VERSION "V5.0.0"

NS_ :

BS_:

BU_: SGW_SG CGW_SG

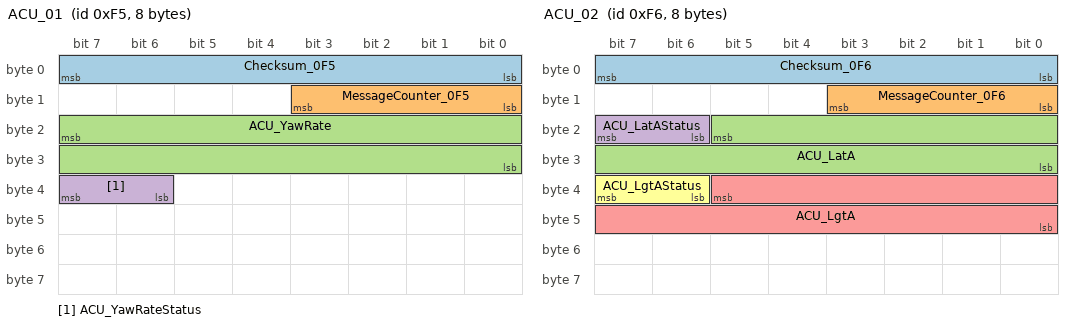
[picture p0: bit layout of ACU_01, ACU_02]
BO_ 245 ACU_01: 8 CGW_SG
 SG_ Checksum_0F5  : 7|8@0+ (1,0) [0|255] "" SGW_SG
 SG_ MessageCounter_0F5  : 11|4@0+ (1,0) [0|15] "" SGW_SG
 SG_ ACU_YawRate  : 23|16@0+ (0.01,-300) [-300|355.35] "degrees/s" SGW_SG
 SG_ ACU_YawRateStatus  : 39|2@0+ (1,0) [0|3] "" SGW_SG

BO_ 246 ACU_02: 8 CGW_SG
 SG_ Checksum_0F6  : 7|8@0+ (1,0) [0|255] "" SGW_SG
 SG_ MessageCounter_0F6  : 11|4@0+ (1,0) [0|15] "" SGW_SG
 SG_ ACU_LatA  : 21|14@0+ (0.01,-49.05) [-49.05|114.78] "m/s^2" SGW_SG
 SG_ ACU_LatAStatus  : 23|2@0+ (1,0) [0|3] "" SGW_SG
 SG_ ACU_LgtA  : 37|14@0+ (0.01,-49.05) [-49.05|114.78] "m/s^2" SGW_SG
 SG_ ACU_LgtAStatus  : 39|2@0+ (1,0) [0|3] "" SGW_SG

BO_ 151 ACU_info: 8 CGW_SG
 SG_ Checksum_097  : 7|8@0+ (1,0) [0|255] "" SGW_SG
 SG_ MessageCounter_097  : 11|4@0+ (1,0) [0|15] "" SGW_SG
 SG_ ACU_CrashOutputSts  : 23|5@0+ (1,0) [0|31] "" SGW_SG
 SG_ ACU_CrashOutputStsValid  : 16|1@0+ (1,0) [0|1] "" SGW_SG
 SG_ ACU_DriverSeatBeltSts  : 31|1@0+ (1,0) [0|1] "" SGW_SG
 SG_ ACU_DriverSeatBeltStsValid  : 30|1@0+ (1,0) [0|1] "" SGW_SG
 SG_ ACU_PassengerSeatBeltSts  : 27|1@0+ (1,0) [0|1] "" SGW_SG
 SG_ ACU_PassengerSeatBeltStsValid  : 26|1@0+ (1,0) [0|1] "" SGW_SG
 SG_ ACU_PassengerSts  : 25|1@0+ (1,0) [0|1] "" SGW_SG
 SG_ ACU_SecondLeftSeatBeltSts  : 39|1@0+ (1,0) [0|1] "" SGW_SG
 SG_ ACU_RLSeatBeltStatusValid  : 38|1@0+ (1,0) [0|1] "" SGW_SG
 SG_ ACU_SecondLeftSts  : 37|1@0+ (1,0) [0|1] "" SGW_SG
 SG_ ACU_SecondRightSeatBeltSts  : 55|1@0+ (1,0) [0|1] "" SGW_SG
 SG_ ACU_RRSeatBeltStatusValid  : 54|1@0+ (1,0) [0|1] "" SGW_SG
 SG_ ACU_SecondRightSts  : 53|1@0+ (1,0) [0|1] "" SGW_SG
 SG_ ACU_PassengerAirbagSts  : 63|2@0+ (1,0) [0|3] "" SGW_SG
 SG_ ACU_DriverWarningLampSts  : 61|2@0+ (1,0) [0|2] "" SGW_SG
 SG_ ACU_PassengerWarningLampSts  : 59|2@0+ (1,0) [0|2] "" SGW_SG
 SG_ ACU_WarningLampSts  : 57|2@0+ (1,0) [0|2] "" SGW_SG

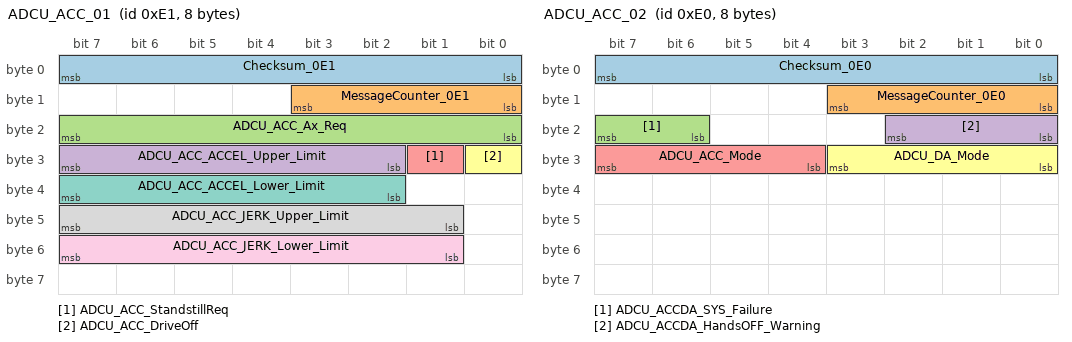
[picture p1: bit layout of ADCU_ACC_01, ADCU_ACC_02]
BO_ 225 ADCU_ACC_01: 8 CGW_SG
 SG_ Checksum_0E1  : 7|8@0+ (1,0) [0|255] "" SGW_SG
 SG_ MessageCounter_0E1  : 11|4@0+ (1,0) [0|15] "" SGW_SG
 SG_ ADCU_ACC_Ax_Req  : 23|8@0+ (0.05,-5) [-5|7.75] "m/s^2" SGW_SG
 SG_ ADCU_ACC_ACCEL_Upper_Limit  : 31|6@0+ (0.05,0) [0|3.15] "m/s^2" SGW_SG
 SG_ ADCU_ACC_StandstillReq  : 25|1@0+ (1,0) [0|1] "" SGW_SG
 SG_ ADCU_ACC_DriveOff  : 24|1@0+ (1,0) [0|1] "" SGW_SG
 SG_ ADCU_ACC_ACCEL_Lower_Limit  : 39|6@0+ (0.05,0) [0|3.15] "m/s^2" SGW_SG
 SG_ ADCU_ACC_JERK_Upper_Limit  : 47|7@0+ (0.1,0) [0|12.7] "m/s^3" SGW_SG
 SG_ ADCU_ACC_JERK_Lower_Limit  : 55|7@0+ (0.1,-12.7) [-12.7|0] "m/s^3" SGW_SG

BO_ 224 ADCU_ACC_02: 8 CGW_SG
 SG_ Checksum_0E0  : 7|8@0+ (1,0) [0|255] "" SGW_SG
 SG_ MessageCounter_0E0  : 11|4@0+ (1,0) [0|15] "" SGW_SG
 SG_ ADCU_ACCDA_SYS_Failure  : 23|2@0+ (1,0) [0|3] "" SGW_SG
 SG_ ADCU_ACCDA_HandsOFF_Warning  : 18|3@0+ (1,0) [0|7] "" SGW_SG
 SG_ ADCU_ACC_Mode  : 31|4@0+ (1,0) [0|10] "" SGW_SG
 SG_ ADCU_DA_Mode  : 27|4@0+ (1,0) [0|14] "" SGW_SG

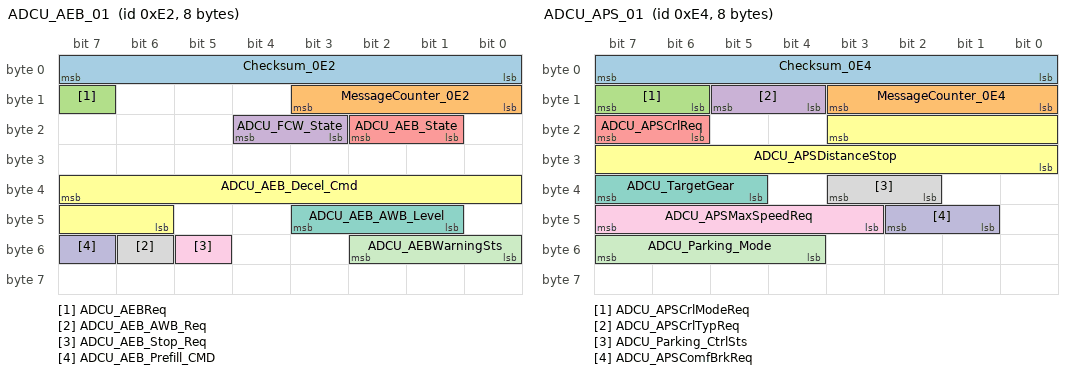
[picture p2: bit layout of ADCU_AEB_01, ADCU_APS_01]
BO_ 226 ADCU_AEB_01: 8 CGW_SG
 SG_ Checksum_0E2  : 7|8@0+ (1,0) [0|255] "" SGW_SG
 SG_ MessageCounter_0E2  : 11|4@0+ (1,0) [0|15] "" SGW_SG
 SG_ ADCU_AEBReq  : 15|1@0+ (1,0) [0|1] "" SGW_SG
 SG_ ADCU_FCW_State  : 20|2@0+ (1,0) [0|3] "" SGW_SG
 SG_ ADCU_AEB_State  : 18|2@0+ (1,0) [0|3] "" SGW_SG
 SG_ ADCU_AEB_Decel_Cmd  : 39|10@0+ (0.05,-16) [-16|16] "m/s^2" SGW_SG
 SG_ ADCU_AEB_AWB_Level  : 43|3@0+ (1,0) [0|5] "" SGW_SG
 SG_ ADCU_AEB_AWB_Req  : 54|1@0+ (1,0) [0|1] "" SGW_SG
 SG_ ADCU_AEB_Stop_Req  : 53|1@0+ (1,0) [0|1] "" SGW_SG
 SG_ ADCU_AEB_Prefill_CMD  : 55|1@0+ (1,0) [0|1] "" SGW_SG
 SG_ ADCU_AEBWarningSts  : 50|3@0+ (1,0) [0|7] "" SGW_SG

BO_ 228 ADCU_APS_01: 8 CGW_SG
 SG_ Checksum_0E4  : 7|8@0+ (1,0) [0|255] "" SGW_SG
 SG_ MessageCounter_0E4  : 11|4@0+ (1,0) [0|15] "" SGW_SG
 SG_ ADCU_APSCrlModeReq  : 15|2@0+ (1,0) [0|3] "" SGW_SG
 SG_ ADCU_APSCrlTypReq  : 13|2@0+ (1,0) [0|3] "" SGW_SG
 SG_ ADCU_APSCrlReq  : 23|2@0+ (1,0) [0|3] "" SGW_SG
 SG_ ADCU_APSDistanceStop  : 19|12@0+ (1,0) [0|4095] "cm" SGW_SG
 SG_ ADCU_TargetGear  : 39|3@0+ (1,0) [0|4] "" SGW_SG
 SG_ ADCU_Parking_CtrlSts  : 35|2@0+ (1,0) [0|3] "" SGW_SG
 SG_ ADCU_APSMaxSpeedReq  : 47|5@0+ (1,0) [0|30] "km/h" SGW_SG
 SG_ ADCU_APSComfBrkReq  : 42|2@0+ (1,0) [0|2] "" SGW_SG
 SG_ ADCU_Parking_Mode  : 55|4@0+ (1,0) [0|15] "" SGW_SG

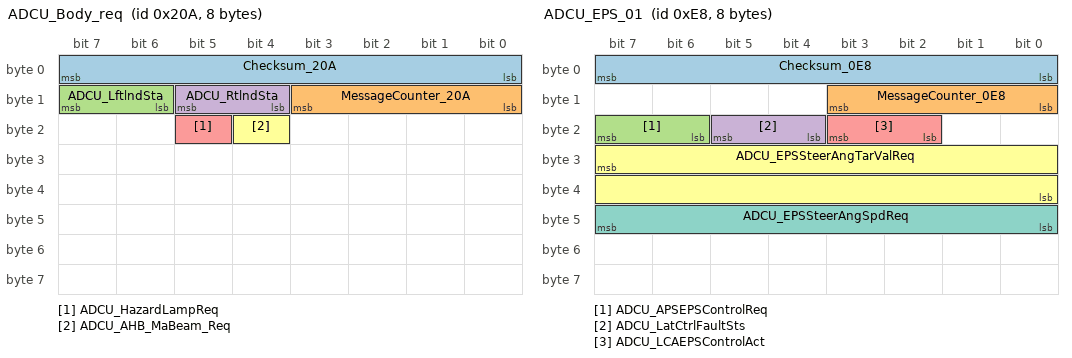
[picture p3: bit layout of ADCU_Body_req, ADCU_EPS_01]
BO_ 522 ADCU_Body_req: 8 CGW_SG
 SG_ Checksum_20A  : 7|8@0+ (1,0) [0|255] "" SGW_SG
 SG_ MessageCounter_20A  : 11|4@0+ (1,0) [0|15] "" SGW_SG
 SG_ ADCU_LftlndSta  : 15|2@0+ (1,0) [0|3] "" SGW_SG
 SG_ ADCU_RtlndSta  : 13|2@0+ (1,0) [0|3] "" SGW_SG
 SG_ ADCU_HazardLampReq  : 21|1@0+ (1,0) [0|1] "" SGW_SG
 SG_ ADCU_AHB_MaBeam_Req  : 20|1@0+ (1,0) [0|1] "" SGW_SG

BO_ 232 ADCU_EPS_01: 8 CGW_SG
 SG_ Checksum_0E8  : 7|8@0+ (1,0) [0|255] "" SGW_SG
 SG_ MessageCounter_0E8  : 11|4@0+ (1,0) [0|15] "" SGW_SG
 SG_ ADCU_APSEPSControlReq  : 23|2@0+ (1,0) [0|3] "" SGW_SG
 SG_ ADCU_LatCtrlFaultSts  : 21|2@0+ (1,0) [0|3] "" SGW_SG
 SG_ ADCU_LCAEPSControlAct  : 19|2@0+ (1,0) [0|3] "" SGW_SG
 SG_ ADCU_EPSSteerAngTarValReq  : 31|16@0+ (0.1,-780) [-780|779.9] "degrees" SGW_SG
 SG_ ADCU_EPSSteerAngSpdReq  : 47|8@0+ (10,-540) [-540|540] "degrees/s" SGW_SG

BO_ 515 ADCU_LDW_01: 8 CGW_SG
 SG_ ADCU_LDW_SYS_Sts  : 39|3@0+ (1,0) [0|7] "" SGW_SG

BO_ 613 APTC_TCU: 8 CGW_SG
 SG_ APTC_HVPowerUpReq  : 7|1@0+ (1,0) [0|1] "" SGW_SG
 SG_ APTC_HeatingFaltStatus  : 6|1@0+ (1,0) [0|1] "" SGW_SG
 SG_ APTC_DriveFaltStatus  : 5|1@0+ (1,0) [0|1] "" SGW_SG
 SG_ APTC_LostCommuFaltStatus  : 4|1@0+ (1,0) [0|1] "" SGW_SG
 SG_ APTC_IGBTFaltStatus  : 3|2@0+ (1,0) [0|3] "" SGW_SG
 SG_ APTC_Core1TempSensorFaltStatus  : 1|2@0+ (1,0) [0|3] "" SGW_SG
 SG_ APTC_LeftCoreTemp  : 15|8@0+ (1,-40) [-40|215] "degrees" SGW_SG
 SG_ APTC_RightCoreTemp  : 23|8@0+ (1,-40) [-40|215] "degrees" SGW_SG
 SG_ APTC_PowerConsumption  : 31|8@0+ (0.04,0) [0|10.2] "KW" SGW_SG
 SG_ APTC_HVBusVoltage  : 39|11@0+ (0.5,0) [0|1020] "V" SGW_SG
 SG_ APTC_OverCurrentFault  : 52|1@0+ (1,0) [0|1] "" SGW_SG
 SG_ APTC_LowVoltageStatus  : 51|2@0+ (1,0) [0|3] "" SGW_SG
 SG_ APTC_HighVoltageStatus  : 49|2@0+ (1,0) [0|3] "" SGW_SG
 SG_ APTC_OverLoadStatus  : 63|2@0+ (1,0) [0|3] "" SGW_SG
 SG_ APTC_IGBTTempSensorStatus  : 61|2@0+ (1,0) [0|3] "" SGW_SG
 SG_ APTC_PCBTempSensorStatus  : 59|2@0+ (1,0) [0|3] "" SGW_SG
 SG_ APTC_Core2TempSensorFaltStatus  : 57|2@0+ (1,0) [0|3] "" SGW_SG

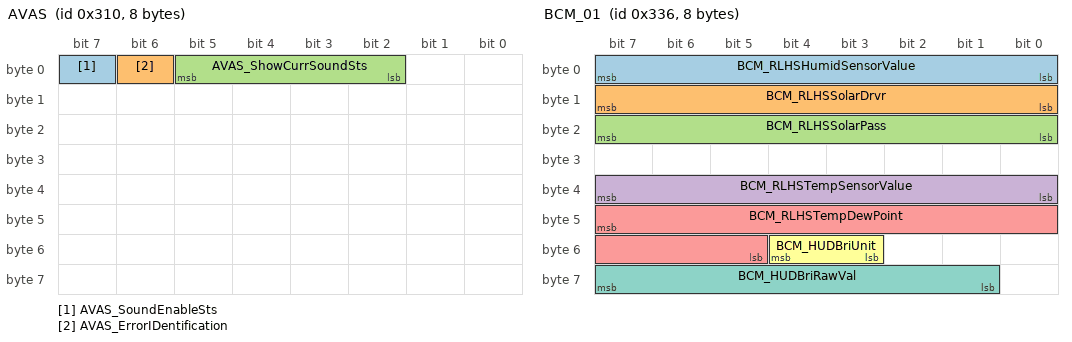
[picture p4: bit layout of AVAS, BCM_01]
BO_ 784 AVAS: 8 CGW_SG
 SG_ AVAS_SoundEnableSts  : 7|1@0+ (1,0) [0|1] "" SGW_SG
 SG_ AVAS_ErrorIDentification  : 6|1@0+ (1,0) [0|1] "" SGW_SG
 SG_ AVAS_ShowCurrSoundSts  : 5|4@0+ (1,0) [0|8] "" SGW_SG

BO_ 822 BCM_01: 8 CGW_SG
 SG_ BCM_RLHSHumidSensorValue  : 7|8@0+ (0.5,-0.5) [0|100] "percent" SGW_SG
 SG_ BCM_RLHSSolarDrvr  : 15|8@0+ (4,0) [0|1000] "W/m^2" SGW_SG
 SG_ BCM_RLHSSolarPass  : 23|8@0+ (4,0) [0|1000] "W/m^2" SGW_SG
 SG_ BCM_RLHSTempSensorValue  : 39|8@0+ (0.5,-40) [-39.5|87] "celsius" SGW_SG
 SG_ BCM_RLHSTempDewPoint  : 47|11@0+ (0.1,-39.6) [-39.5|60.4] "celsius" SGW_SG
 SG_ BCM_HUDBriUnit  : 52|2@0+ (1,0) [0|3] "" SGW_SG
 SG_ BCM_HUDBriRawVal  : 63|7@0+ (1,0) [0|126] "" SGW_SG

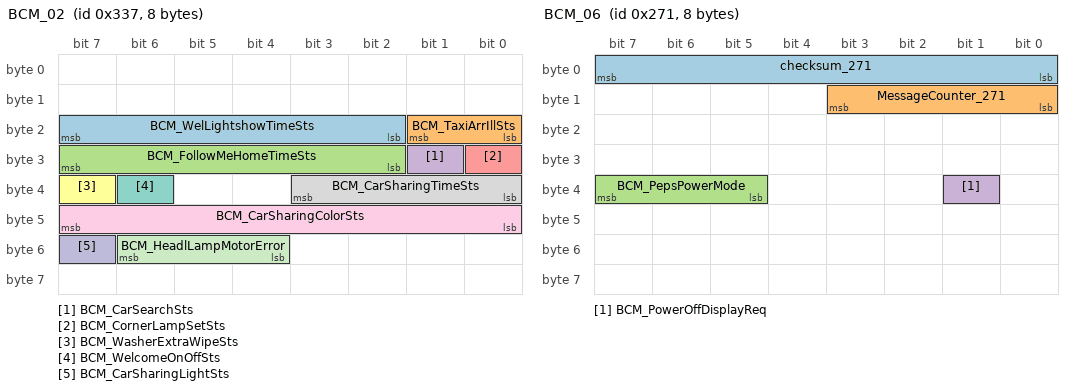
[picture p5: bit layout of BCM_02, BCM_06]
BO_ 823 BCM_02: 8 CGW_SG
 SG_ BCM_WelLightshowTimeSts  : 23|6@0+ (5,5) [5|180] "s" SGW_SG
 SG_ BCM_TaxiArrIllSts  : 17|2@0+ (1,0) [0|2] "" SGW_SG
 SG_ BCM_FollowMeHomeTimeSts  : 31|6@0+ (5,5) [5|180] "s" SGW_SG
 SG_ BCM_CarSearchSts  : 25|1@0+ (1,0) [0|1] "" SGW_SG
 SG_ BCM_CornerLampSetSts  : 24|1@0+ (1,0) [0|1] "" SGW_SG
 SG_ BCM_WasherExtraWipeSts  : 39|1@0+ (1,0) [0|1] "" SGW_SG
 SG_ BCM_WelcomeOnOffSts  : 38|1@0+ (1,0) [0|1] "" SGW_SG
 SG_ BCM_CarSharingTimeSts  : 35|4@0+ (1,0) [0|9] "" SGW_SG
 SG_ BCM_CarSharingColorSts  : 47|8@0+ (1,0) [0|255] "" SGW_SG
 SG_ BCM_CarSharingLightSts  : 55|1@0+ (1,0) [0|1] "" SGW_SG
 SG_ BCM_HeadlLampMotorError  : 54|3@0+ (1,0) [0|7] "" SGW_SG

BO_ 824 BCM_03: 8 CGW_SG
 SG_ Checksum_338  : 7|8@0+ (1,0) [0|255] "" SGW_SG
 SG_ MessageCounter_338  : 11|4@0+ (1,0) [0|15] "" SGW_SG
 SG_ BCM_HazardWarnSts  : 15|1@0+ (1,0) [0|1] "" SGW_SG
 SG_ BCM_DRLReq  : 14|2@0+ (1,0) [0|2] "" SGW_SG
 SG_ BCM_FollowMeHomeSts  : 23|1@0+ (1,0) [0|1] "" SGW_SG
 SG_ BCM_ChargingLightReq  : 22|3@0+ (1,0) [0|7] "" SGW_SG
 SG_ BCM_TaxiArrIllReq  : 16|1@0+ (1,0) [0|1] "" SGW_SG
 SG_ BCM_LeCornrgLiReq  : 31|2@0+ (1,0) [0|2] "" SGW_SG
 SG_ BCM_MainBeamReq  : 29|2@0+ (1,0) [0|2] "" SGW_SG
 SG_ BCM_DippedBeamReq  : 27|2@0+ (1,0) [0|3] "" SGW_SG
 SG_ BCM_RiCornrgLiReq  : 39|2@0+ (1,0) [0|2] "" SGW_SG
 SG_ BCM_RLS_AutoLampSenSts  : 37|2@0+ (1,0) [0|3] "" SGW_SG
 SG_ BCM_RearFogLampSts  : 35|1@0+ (1,0) [0|1] "" SGW_SG
 SG_ BCM_ExtLightFault  : 32|1@0+ (1,0) [0|1] "" SGW_SG
 SG_ BCM_StoplampReq  : 47|1@0+ (1,0) [0|1] "" SGW_SG
 SG_ BCM_AutoLmpSts  : 44|1@0+ (1,0) [0|1] "" SGW_SG
 SG_ BCM_HeightSetSts  : 43|3@0+ (1,0) [0|7] "" SGW_SG
 SG_ BCM_RLS_LightSensorFault  : 40|1@0+ (1,0) [0|1] "" SGW_SG
 SG_ BCM_RLS_RainSensorFault  : 45|1@0+ (1,0) [0|1] "" SGW_SG
 SG_ BCM_PosLampReq  : 55|2@0+ (1,0) [0|2] "" SGW_SG
 SG_ BCM_FrontFogLampReq  : 53|2@0+ (1,0) [0|2] "" SGW_SG
 SG_ BCM_FRDomeLampSts  : 51|2@0+ (1,0) [0|1] "" SGW_SG
 SG_ BCM_RRDomeLampSts  : 49|2@0+ (1,0) [0|1] "" SGW_SG
 SG_ BCM_WiperFaultWarn  : 60|1@0+ (1,0) [0|1] "" SGW_SG

BO_ 825 BCM_04: 8 CGW_SG
 SG_ Checksum_339  : 7|8@0+ (1,0) [0|255] "" SGW_SG
 SG_ MessageCounter_339  : 11|4@0+ (1,0) [0|15] "" SGW_SG
 SG_ BCM_LockFailRemindReq  : 15|1@0+ (1,0) [0|1] "" SGW_SG
 SG_ BCM_LockRLCtrlReq  : 17|2@0+ (1,0) [0|3] "" SGW_SG
 SG_ BCM_LockRRCtrlReq  : 19|2@0+ (1,0) [0|3] "" SGW_SG
 SG_ BCM_LockFRCtrlReq  : 21|2@0+ (1,0) [0|3] "" SGW_SG
 SG_ BCM_LockFLCtrlReq  : 23|2@0+ (1,0) [0|3] "" SGW_SG
 SG_ BCM_AwayLockSts  : 24|1@0+ (1,0) [0|1] "" SGW_SG
 SG_ BCM_OutsideUnlockModeSts  : 26|1@0+ (1,0) [0|1] "" SGW_SG
 SG_ BCM_ApproachingUnlockSts  : 27|1@0+ (1,0) [0|1] "" SGW_SG
 SG_ BCM_ChrgFlapSts  : 40|1@0+ (1,0) [0|1] "" SGW_SG
 SG_ BCM_TailgateLogicLockSts  : 41|1@0+ (1,0) [0|1] "" SGW_SG
 SG_ BCM_TailgateSts  : 42|1@0+ (1,0) [0|1] "" SGW_SG
 SG_ BCM_HoodSts  : 43|1@0+ (1,0) [0|1] "" SGW_SG
 SG_ BCM_CentralLockSts  : 44|1@0+ (1,0) [0|1] "" SGW_SG
 SG_ BCM_ChdLockSts  : 46|2@0+ (1,0) [0|3] "" SGW_SG
 SG_ BCM_GlassUnclsWarnCtrlRqst  : 48|1@0+ (1,0) [0|1] "" SGW_SG
 SG_ BCM_NFCCloseDoorAndLockFeedback  : 49|1@0+ (1,0) [0|1] "" SGW_SG
 SG_ BCM_WinAntipinchNotice  : 50|1@0+ (1,0) [0|1] "" SGW_SG
 SG_ BCM_LockDoorOpenReHornSts  : 53|1@0+ (1,0) [0|1] "" SGW_SG
 SG_ BCM_AntiTheftReHornSts  : 54|1@0+ (1,0) [0|1] "" SGW_SG
 SG_ BCM_LeftKeyReHornSts  : 55|1@0+ (1,0) [0|1] "" SGW_SG
 SG_ BCM_AlarmEnableSts  : 56|1@0+ (1,0) [0|1] "" SGW_SG
 SG_ BCM_RelockSts  : 59|3@0+ (1,0) [0|4] "" SGW_SG
 SG_ BCM_WinClsReq  : 62|1@0+ (1,0) [0|1] "" SGW_SG

BO_ 826 BCM_05: 8 CGW_SG
 SG_ Checksum_33A  : 7|8@0+ (1,0) [0|255] "" SGW_SG
 SG_ MessageCounter_33A  : 11|4@0+ (1,0) [0|15] "" SGW_SG
 SG_ BCM_GearTimesSts  : 15|3@0+ (1,0) [0|5] "" SGW_SG
 SG_ BCM_ChrgFlapLockSts  : 12|1@0+ (1,0) [0|1] "" SGW_SG
 SG_ BCM_FRSeatBeltRemindReq  : 17|2@0+ (1,0) [0|3] "" SGW_SG
 SG_ BCM_FLSeatBeltRemindReq  : 19|2@0+ (1,0) [0|3] "" SGW_SG
 SG_ BCM_KeyNotInCarRemind  : 20|1@0+ (1,0) [0|1] "" SGW_SG
 SG_ BCM_RRSeatBeltRemindReq  : 29|2@0+ (1,0) [0|3] "" SGW_SG
 SG_ BCM_RLSeatBeltRemindReq  : 31|2@0+ (1,0) [0|3] "" SGW_SG
 SG_ BCM_WiperServiceSts  : 33|2@0+ (1,0) [0|1] "" SGW_SG
 SG_ BCM_AutoCloseWinFunSts  : 36|1@0+ (1,0) [0|1] "" SGW_SG
 SG_ BCM_DomeLampBrightSts  : 37|1@0+ (1,0) [0|1] "" SGW_SG
 SG_ BCM_PuddleLiReq  : 39|2@0+ (1,0) [0|2] "" SGW_SG
 SG_ BCM_DomeLampAutoSts  : 41|2@0+ (1,0) [0|2] "" SGW_SG
 SG_ BCM_FrontWiperModeSts  : 44|3@0+ (1,0) [0|5] "" SGW_SG
 SG_ BCM_WiperWorkingSts  : 47|3@0+ (1,0) [0|2] "" SGW_SG
 SG_ BCM_WelLightshowOnOffSts  : 51|2@0+ (1,0) [0|2] "" SGW_SG

BO_ 625 BCM_06: 8 CGW_SG
 SG_ checksum_271  : 7|8@0+ (1,0) [0|255] "" SGW_SG
 SG_ MessageCounter_271  : 11|4@0+ (1,0) [0|15] "" SGW_SG
 SG_ BCM_PepsPowerMode  : 39|3@0+ (1,0) [0|7] "" SGW_SG
 SG_ BCM_PowerOffDisplayReq  : 33|1@0+ (1,0) [0|1] "" SGW_SG

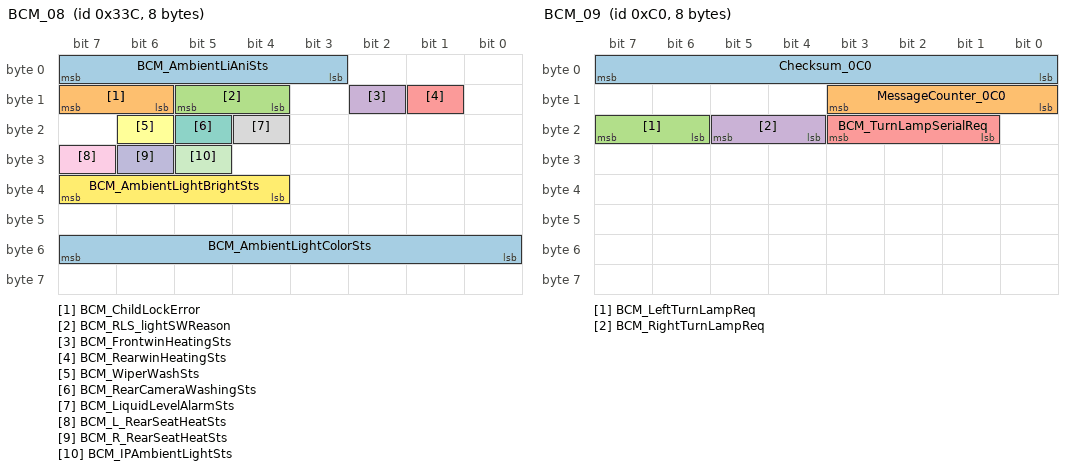
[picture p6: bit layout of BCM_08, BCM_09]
BO_ 828 BCM_08: 8 CGW_SG
 SG_ BCM_AmbientLiAniSts  : 7|5@0+ (1,0) [0|25] "" SGW_SG
 SG_ BCM_ChildLockError  : 15|2@0+ (1,0) [0|3] "" SGW_SG
 SG_ BCM_RLS_lightSWReason  : 13|2@0+ (1,0) [0|3] "" SGW_SG
 SG_ BCM_FrontwinHeatingSts  : 10|1@0+ (1,0) [0|1] "" SGW_SG
 SG_ BCM_RearwinHeatingSts  : 9|1@0+ (1,0) [0|1] "" SGW_SG
 SG_ BCM_WiperWashSts  : 22|1@0+ (1,0) [0|1] "" SGW_SG
 SG_ BCM_RearCameraWashingSts  : 21|1@0+ (1,0) [0|1] "" SGW_SG
 SG_ BCM_LiquidLevelAlarmSts  : 20|1@0+ (1,0) [0|1] "" SGW_SG
 SG_ BCM_L_RearSeatHeatSts  : 31|1@0+ (1,0) [0|1] "" SGW_SG
 SG_ BCM_R_RearSeatHeatSts  : 30|1@0+ (1,0) [0|1] "" SGW_SG
 SG_ BCM_IPAmbientLightSts  : 29|1@0+ (1,0) [0|1] "" SGW_SG
 SG_ BCM_AmbientLightBrightSts  : 39|4@0+ (1,0) [0|10] "" SGW_SG
 SG_ BCM_AmbientLightColorSts  : 55|8@0+ (1,0) [0|255] "" SGW_SG

BO_ 192 BCM_09: 8 CGW_SG
 SG_ Checksum_0C0  : 7|8@0+ (1,0) [0|255] "" SGW_SG
 SG_ MessageCounter_0C0  : 11|4@0+ (1,0) [0|15] "" SGW_SG
 SG_ BCM_LeftTurnLampReq  : 23|2@0+ (1,0) [0|2] "" SGW_SG
 SG_ BCM_RightTurnLampReq  : 21|2@0+ (1,0) [0|2] "" SGW_SG
 SG_ BCM_TurnLampSerialReq  : 19|3@0+ (1,0) [0|3] "" SGW_SG

BO_ 267 BCM_10: 8 CGW_SG
 SG_ BCM_CentralLockFeedback  : 38|2@0+ (1,0) [0|3] "" SGW_SG
 SG_ BCM_LVonReqKeyNotInCar  : 36|1@0+ (1,0) [0|1] "" SGW_SG

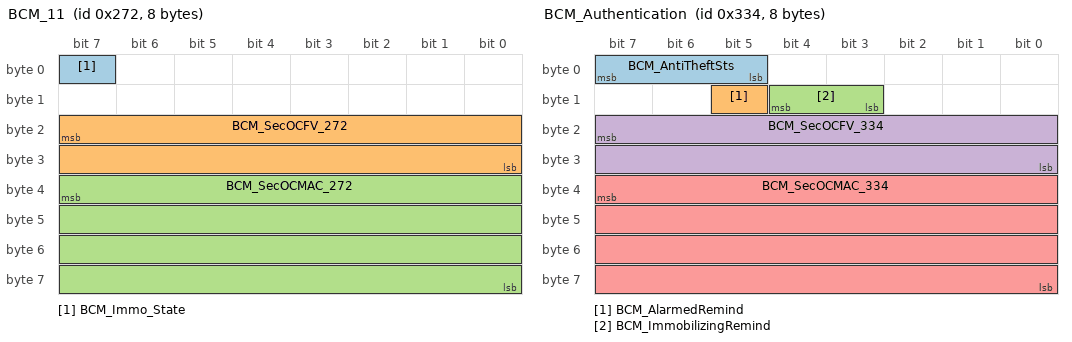
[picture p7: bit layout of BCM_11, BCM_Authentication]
BO_ 626 BCM_11: 8 CGW_SG
 SG_ BCM_Immo_State  : 7|1@0+ (1,0) [0|1] "" SGW_SG
 SG_ BCM_SecOCFV_272  : 23|16@0+ (1,0) [0|65535] "" SGW_SG
 SG_ BCM_SecOCMAC_272  : 39|32@0+ (1,0) [0|4294967295] "" SGW_SG

BO_ 624 BCM_ALM: 8 CGW_SG
 SG_ BCM_ALM1_MusicFrequencySts  : 5|1@0+ (1,0) [0|1] "" SGW_SG
 SG_ BCM_ALM2_MusicFrequencySts  : 4|1@0+ (1,0) [0|1] "" SGW_SG

BO_ 820 BCM_Authentication: 8 CGW_SG
 SG_ BCM_AntiTheftSts  : 7|3@0+ (1,0) [0|3] "" SGW_SG
 SG_ BCM_AlarmedRemind  : 13|1@0+ (1,0) [0|1] "" SGW_SG
 SG_ BCM_ImmobilizingRemind  : 12|2@0+ (1,0) [0|3] "" SGW_SG
 SG_ BCM_SecOCFV_334  : 23|16@0+ (1,0) [0|65535] "" SGW_SG
 SG_ BCM_SecOCMAC_334  : 39|32@0+ (1,0) [0|4294967295] "" SGW_SG

BO_ 934 BMS_BatInfor_01: 8 CGW_SG
 SG_ BMS_CellNumbers  : 15|8@0+ (1,0) [0|255] "" SGW_SG

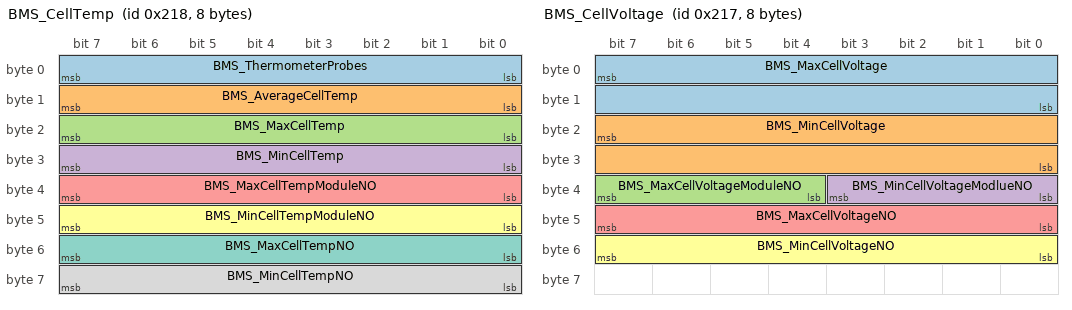
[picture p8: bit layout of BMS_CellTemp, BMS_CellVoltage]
BO_ 536 BMS_CellTemp: 8 CGW_SG
 SG_ BMS_ThermometerProbes  : 7|8@0+ (1,0) [0|255] "" SGW_SG
 SG_ BMS_AverageCellTemp  : 15|8@0+ (1,-40) [-40|215] "celsius" SGW_SG
 SG_ BMS_MaxCellTemp  : 23|8@0+ (1,-40) [-40|215] "celsius" SGW_SG
 SG_ BMS_MinCellTemp  : 31|8@0+ (1,-40) [-40|215] "celsius" SGW_SG
 SG_ BMS_MaxCellTempModuleNO  : 39|8@0+ (1,0) [0|255] "" SGW_SG
 SG_ BMS_MinCellTempModuleNO  : 47|8@0+ (1,0) [0|255] "" SGW_SG
 SG_ BMS_MaxCellTempNO  : 55|8@0+ (1,0) [0|255] "" SGW_SG
 SG_ BMS_MinCellTempNO  : 63|8@0+ (1,0) [0|255] "" SGW_SG

BO_ 535 BMS_CellVoltage: 8 CGW_SG
 SG_ BMS_MaxCellVoltage  : 7|16@0+ (0.001,0) [0|65.535] "V" SGW_SG
 SG_ BMS_MinCellVoltage  : 23|16@0+ (0.001,0) [0|65.535] "V" SGW_SG
 SG_ BMS_MaxCellVoltageModuleNO  : 39|4@0+ (1,0) [0|15] "" SGW_SG
 SG_ BMS_MinCellVoltageModlueNO  : 35|4@0+ (1,0) [0|15] "" SGW_SG
 SG_ BMS_MaxCellVoltageNO  : 47|8@0+ (1,0) [0|255] "" SGW_SG
 SG_ BMS_MinCellVoltageNO  : 55|8@0+ (1,0) [0|255] "" SGW_SG

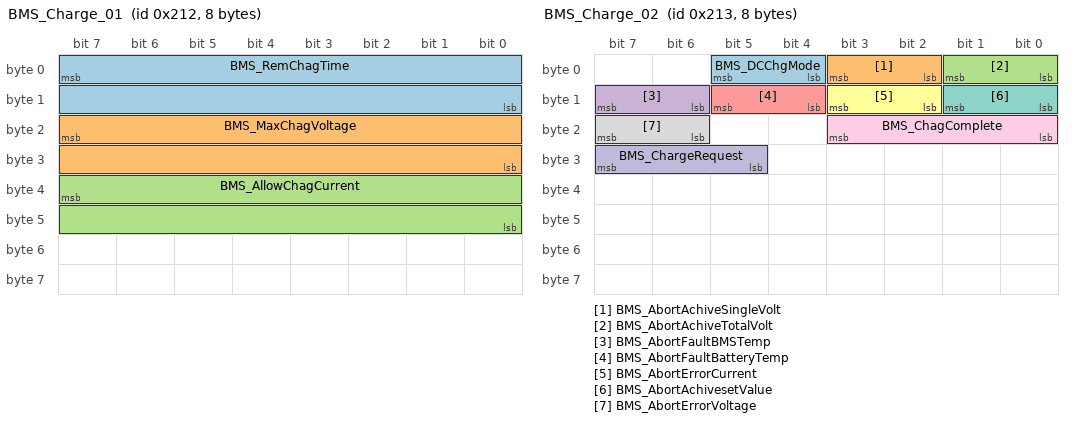
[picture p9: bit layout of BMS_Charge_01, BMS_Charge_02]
BO_ 530 BMS_Charge_01: 8 CGW_SG
 SG_ BMS_RemChagTime  : 7|16@0+ (1,0) [0|3600] "min" SGW_SG
 SG_ BMS_MaxChagVoltage  : 23|16@0+ (0.1,0) [0|6553.5] "V" SGW_SG
 SG_ BMS_AllowChagCurrent  : 39|16@0+ (0.1,-1000) [-1000|1000] "A" SGW_SG

BO_ 531 BMS_Charge_02: 8 CGW_SG
 SG_ BMS_DCChgMode  : 5|2@0+ (1,0) [0|2] "" SGW_SG
 SG_ BMS_AbortAchiveSingleVolt  : 3|2@0+ (1,0) [0|2] "" SGW_SG
 SG_ BMS_AbortAchiveTotalVolt  : 1|2@0+ (1,0) [0|2] "" SGW_SG
 SG_ BMS_AbortFaultBMSTemp  : 15|2@0+ (1,0) [0|2] "" SGW_SG
 SG_ BMS_AbortFaultBatteryTemp  : 13|2@0+ (1,0) [0|2] "" SGW_SG
 SG_ BMS_AbortErrorCurrent  : 11|2@0+ (1,0) [0|2] "" SGW_SG
 SG_ BMS_AbortAchivesetValue  : 9|2@0+ (1,0) [0|2] "" SGW_SG
 SG_ BMS_AbortErrorVoltage  : 23|2@0+ (1,0) [0|2] "" SGW_SG
 SG_ BMS_ChagComplete  : 19|4@0+ (1,0) [0|3] "" SGW_SG
 SG_ BMS_ChargeRequest  : 31|3@0+ (1,0) [0|4] "" SGW_SG

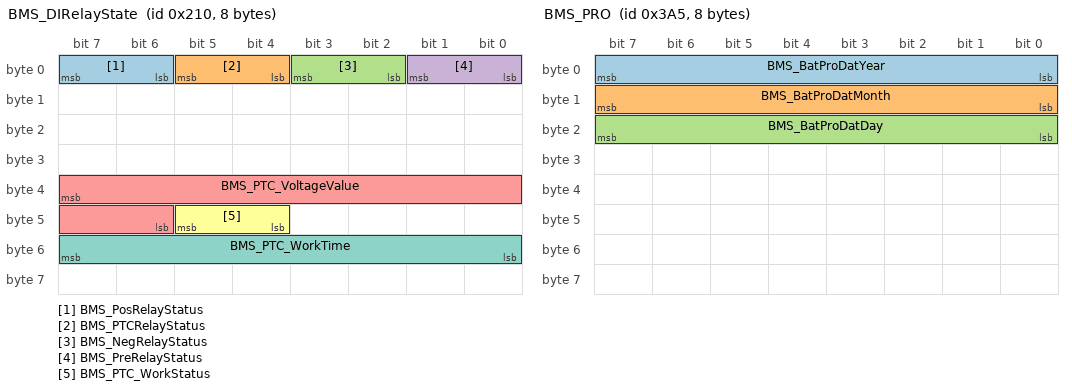
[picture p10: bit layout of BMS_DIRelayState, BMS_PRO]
BO_ 528 BMS_DIRelayState: 8 CGW_SG
 SG_ BMS_PosRelayStatus  : 7|2@0+ (1,0) [0|3] "" SGW_SG
 SG_ BMS_PTCRelayStatus  : 5|2@0+ (1,0) [0|3] "" SGW_SG
 SG_ BMS_NegRelayStatus  : 3|2@0+ (1,0) [0|3] "" SGW_SG
 SG_ BMS_PreRelayStatus  : 1|2@0+ (1,0) [0|3] "" SGW_SG
 SG_ BMS_PTC_VoltageValue  : 39|10@0+ (1,0) [0|1023] "V" SGW_SG
 SG_ BMS_PTC_WorkStatus  : 45|2@0+ (1,0) [0|2] "" SGW_SG
 SG_ BMS_PTC_WorkTime  : 55|8@0+ (1,0) [0|255] "min" SGW_SG

BO_ 772 BMS_ErrorInfo: 8 CGW_SG
 SG_ BMS_ErrorCellOverVolt  : 7|2@0+ (1,0) [0|3] "" SGW_SG
 SG_ BMS_ErrorCellUnderVolt  : 5|2@0+ (1,0) [0|3] "" SGW_SG
 SG_ BMS_ErrorCellHighTemp  : 3|2@0+ (1,0) [0|3] "" SGW_SG
 SG_ BMS_ErrorCellLowTemp  : 1|2@0+ (1,0) [0|3] "" SGW_SG
 SG_ BMS_ErrorBattOverVolt  : 15|2@0+ (1,0) [0|3] "" SGW_SG
 SG_ BMS_ErrorBattUnderVolt  : 13|2@0+ (1,0) [0|3] "" SGW_SG
 SG_ BMS_ErrorChaCurrentOver  : 11|2@0+ (1,0) [0|3] "" SGW_SG
 SG_ BMS_ErrorDisChaCurrentOver  : 9|2@0+ (1,0) [0|3] "" SGW_SG
 SG_ BMS_ErrorBSUOffline  : 23|1@0+ (1,0) [0|1] "" SGW_SG
 SG_ BMS_ErrorLeakCurrent  : 22|2@0+ (1,0) [0|3] "" SGW_SG
 SG_ BMS_ErrorCellVoltDiff  : 20|2@0+ (1,0) [0|3] "" SGW_SG
 SG_ BMS_ErrorCellTempDiff  : 18|2@0+ (1,0) [0|3] "" SGW_SG
 SG_ BMS_ErrorBatVolt  : 31|2@0+ (1,0) [0|3] "" SGW_SG
 SG_ BMS_ErrorHallOffline  : 29|1@0+ (1,0) [0|1] "" SGW_SG
 SG_ BMS_ErrorCellVoltOffline  : 28|1@0+ (1,0) [0|1] "" SGW_SG
 SG_ BMS_ErrorCellTempOffline  : 27|1@0+ (1,0) [0|1] "" SGW_SG
 SG_ BMS_ErrorPreChaFailed  : 26|1@0+ (1,0) [0|1] "" SGW_SG
 SG_ BMS_ErrorRelay  : 25|1@0+ (1,0) [0|1] "" SGW_SG
 SG_ BMS_ErrorBSUBalance  : 24|1@0+ (1,0) [0|1] "" SGW_SG
 SG_ BMS_ErrorLowSoc  : 37|2@0+ (1,0) [0|3] "" SGW_SG
 SG_ BMS_ErrorHighSoc  : 35|1@0+ (1,0) [0|1] "" SGW_SG
 SG_ BMS_ErrorSoCJump_RM  : 34|1@0+ (1,0) [0|1] "" SGW_SG
 SG_ BMS_ErrorHVIL  : 33|1@0+ (1,0) [0|1] "" SGW_SG
 SG_ BMS_ErrorEmergencyOffCrash  : 32|1@0+ (1,0) [0|1] "" SGW_SG
 SG_ BMS_ErrorSystemsMatch  : 47|1@0+ (1,0) [0|1] "" SGW_SG
 SG_ BMS_ErrorSmoke  : 46|1@0+ (1,0) [0|1] "" SGW_SG
 SG_ BMS_ErrorLeakDet  : 45|1@0+ (1,0) [0|1] "" SGW_SG
 SG_ BMS_ThermalRunawayFault  : 43|1@0+ (1,0) [0|1] "" SGW_SG
 SG_ BMS_DTC  : 55|8@0+ (1,0) [0|255] "" SGW_SG

BO_ 933 BMS_PRO: 8 CGW_SG
 SG_ BMS_BatProDatYear  : 7|8@0+ (1,0) [0|1] "" SGW_SG
 SG_ BMS_BatProDatMonth  : 15|8@0+ (1,0) [0|1] "" SGW_SG
 SG_ BMS_BatProDatDay  : 23|8@0+ (1,0) [0|1] "" SGW_SG

BO_ 992 BMS_SGW_01: 8 CGW_SG
 SG_ BMS_FeedEnergySts  : 7|17@0+ (0.1,0) [0|9999] "" SGW_SG
 SG_ BMS_DirveDiscSts  : 31|17@0+ (0.1,0) [0|9999] "" SGW_SG

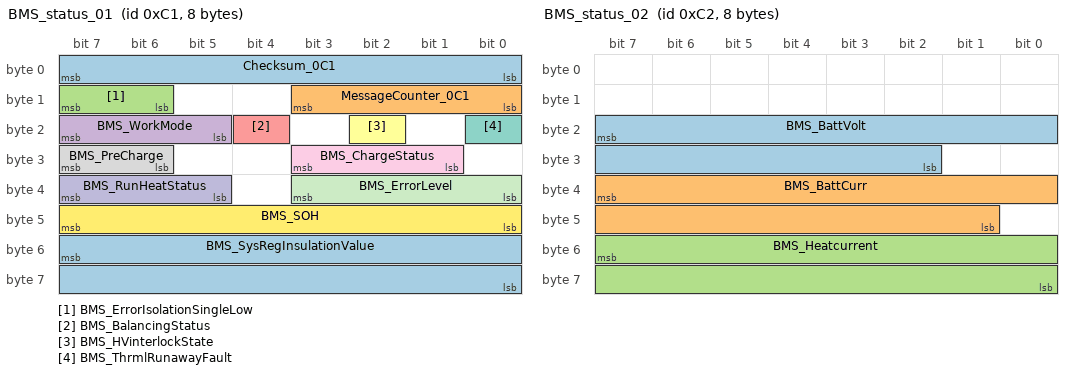
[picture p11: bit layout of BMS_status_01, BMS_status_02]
BO_ 193 BMS_status_01: 8 CGW_SG
 SG_ Checksum_0C1  : 7|8@0+ (1,0) [0|255] "" SGW_SG
 SG_ MessageCounter_0C1  : 11|4@0+ (1,0) [0|15] "" SGW_SG
 SG_ BMS_ErrorIsolationSingleLow  : 15|2@0+ (1,0) [0|3] "" SGW_SG
 SG_ BMS_WorkMode  : 23|3@0+ (1,0) [0|7] "" SGW_SG
 SG_ BMS_BalancingStatus  : 20|1@0+ (1,0) [0|1] "" SGW_SG
 SG_ BMS_HVinterlockState  : 18|1@0+ (1,0) [0|1] "" SGW_SG
 SG_ BMS_ThrmlRunawayFault  : 16|1@0+ (1,0) [0|1] "" SGW_SG
 SG_ BMS_PreCharge  : 31|2@0+ (1,0) [0|3] "" SGW_SG
 SG_ BMS_ChargeStatus  : 27|3@0+ (1,0) [0|7] "" SGW_SG
 SG_ BMS_RunHeatStatus  : 39|3@0+ (1,0) [0|4] "" SGW_SG
 SG_ BMS_ErrorLevel  : 35|4@0+ (1,0) [0|4] "" SGW_SG
 SG_ BMS_SOH  : 47|8@0+ (0.5,0) [0|100] "percent" SGW_SG
 SG_ BMS_SysRegInsulationValue  : 55|16@0+ (1,0) [0|60000] "kOhm" SGW_SG

BO_ 194 BMS_status_02: 8 CGW_SG
 SG_ BMS_BattVolt  : 23|14@0+ (0.1,0) [0|1000] "V" SGW_SG
 SG_ BMS_BattCurr  : 39|15@0+ (0.1,-1024) [-1024|1023] "A" SGW_SG
 SG_ BMS_Heatcurrent  : 55|16@0+ (0.1,-1024) [-1024|1023] "A" SGW_SG

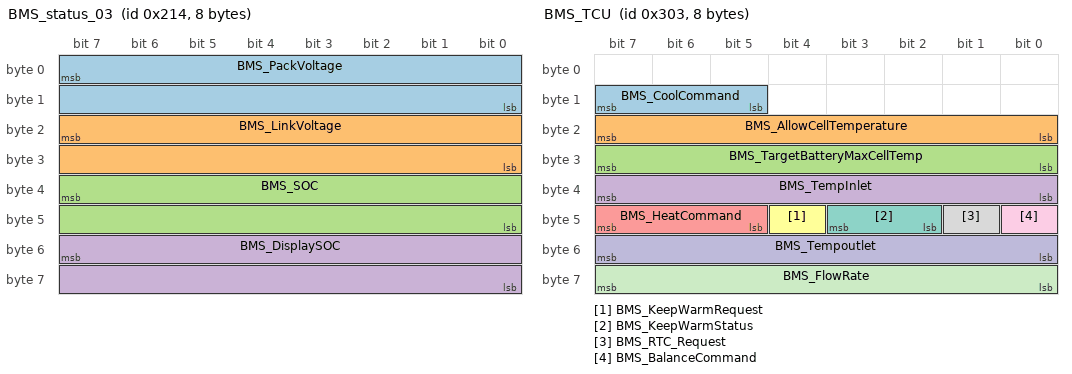
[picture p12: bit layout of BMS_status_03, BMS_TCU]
BO_ 532 BMS_status_03: 8 CGW_SG
 SG_ BMS_PackVoltage  : 7|16@0+ (0.1,0) [0|6553.5] "V" SGW_SG
 SG_ BMS_LinkVoltage  : 23|16@0+ (0.1,0) [0|6553.5] "V" SGW_SG
 SG_ BMS_SOC  : 39|16@0+ (0.01,0) [0|100] "percent" SGW_SG
 SG_ BMS_DisplaySOC  : 55|16@0+ (0.01,0) [0|100] "percent" SGW_SG

BO_ 771 BMS_TCU: 8 CGW_SG
 SG_ BMS_CoolCommand  : 15|3@0+ (1,0) [0|7] "" SGW_SG
 SG_ BMS_AllowCellTemperature  : 23|8@0+ (1,-40) [-40|215] "celsius" SGW_SG
 SG_ BMS_TargetBatteryMaxCellTemp  : 31|8@0+ (1,-40) [-40|215] "celsius" SGW_SG
 SG_ BMS_TempInlet  : 39|8@0+ (1,-40) [-40|215] "celsius" SGW_SG
 SG_ BMS_HeatCommand  : 47|3@0+ (1,0) [0|7] "" SGW_SG
 SG_ BMS_KeepWarmRequest  : 44|1@0+ (1,0) [0|1] "" SGW_SG
 SG_ BMS_KeepWarmStatus  : 43|2@0+ (1,0) [0|2] "" SGW_SG
 SG_ BMS_RTC_Request  : 41|1@0+ (1,0) [0|1] "" SGW_SG
 SG_ BMS_BalanceCommand  : 40|1@0+ (1,0) [0|1] "" SGW_SG
 SG_ BMS_Tempoutlet  : 55|8@0+ (1,-40) [-40|215] "celsius" SGW_SG
 SG_ BMS_FlowRate  : 63|8@0+ (1,0) [0|255] "L/min" SGW_SG

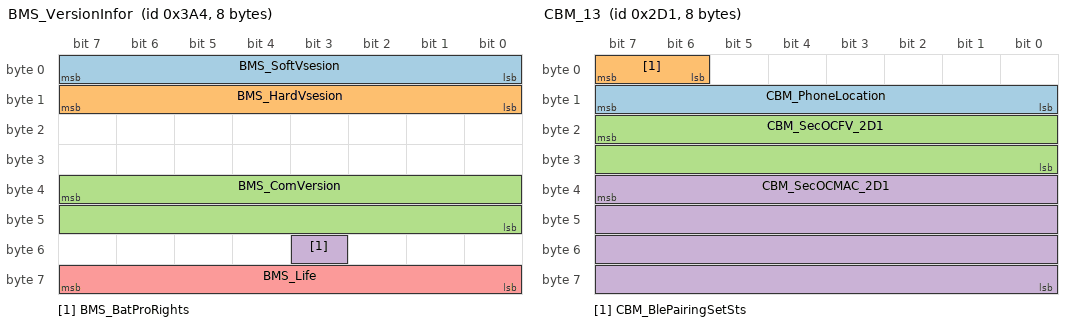
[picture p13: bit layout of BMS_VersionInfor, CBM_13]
BO_ 932 BMS_VersionInfor: 8 CGW_SG
 SG_ BMS_SoftVsesion  : 7|8@0+ (1,0) [0|1] "" SGW_SG
 SG_ BMS_HardVsesion  : 15|8@0+ (1,0) [0|1] "" SGW_SG
 SG_ BMS_ComVersion  : 39|16@0+ (1,0) [0|65535] "" SGW_SG
 SG_ BMS_BatProRights  : 51|1@0+ (1,0) [0|1] "" SGW_SG
 SG_ BMS_Life  : 63|8@0+ (1,0) [0|255] "" SGW_SG

BO_ 257 CBM_request_01: 8 SGW_SG
 SG_ CBM_BLE_CarSearchReq  : 26|1@0+ (1,0) [0|1] "" CGW_SG

BO_ 721 CBM_13: 8 SGW_SG
 SG_ CBM_PhoneLocation  : 15|8@0+ (1,0) [0|8] "" CGW_SG
 SG_ CBM_BlePairingSetSts  : 7|2@0+ (1,0) [0|2] "" CGW_SG
 SG_ CBM_SecOCFV_2D1  : 23|16@0+ (1,0) [0|65535] "" CGW_SG
 SG_ CBM_SecOCMAC_2D1  : 39|32@0+ (1,0) [0|4294967295] "" CGW_SG

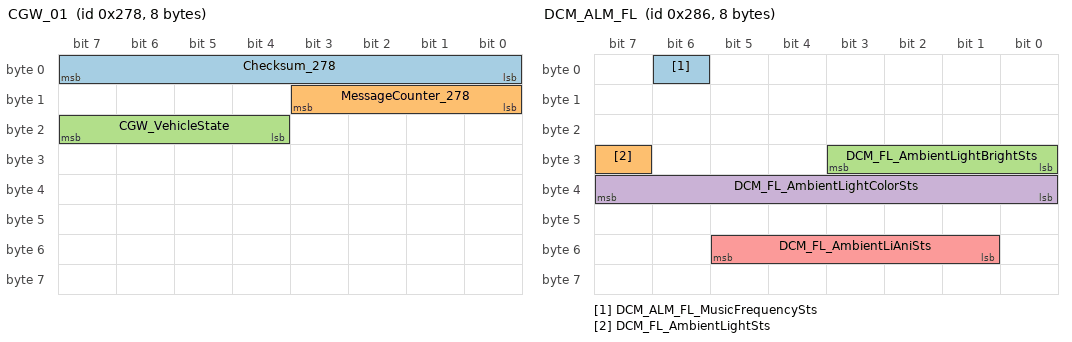
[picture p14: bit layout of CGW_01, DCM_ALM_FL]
BO_ 632 CGW_01: 8 CGW_SG
 SG_ Checksum_278  : 7|8@0+ (1,0) [0|255] "" SGW_SG
 SG_ MessageCounter_278  : 11|4@0+ (1,0) [0|15] "" SGW_SG
 SG_ CGW_VehicleState  : 23|4@0+ (1,0) [0|8] "" SGW_SG

BO_ 646 DCM_ALM_FL: 8 CGW_SG
 SG_ DCM_ALM_FL_MusicFrequencySts  : 6|1@0+ (1,0) [0|1] "" SGW_SG
 SG_ DCM_FL_AmbientLightSts  : 31|1@0+ (1,0) [0|1] "" SGW_SG
 SG_ DCM_FL_AmbientLightBrightSts  : 27|4@0+ (1,0) [0|10] "" SGW_SG
 SG_ DCM_FL_AmbientLightColorSts  : 39|8@0+ (1,0) [0|255] "" SGW_SG
 SG_ DCM_FL_AmbientLiAniSts  : 53|5@0+ (1,0) [0|25] "" SGW_SG

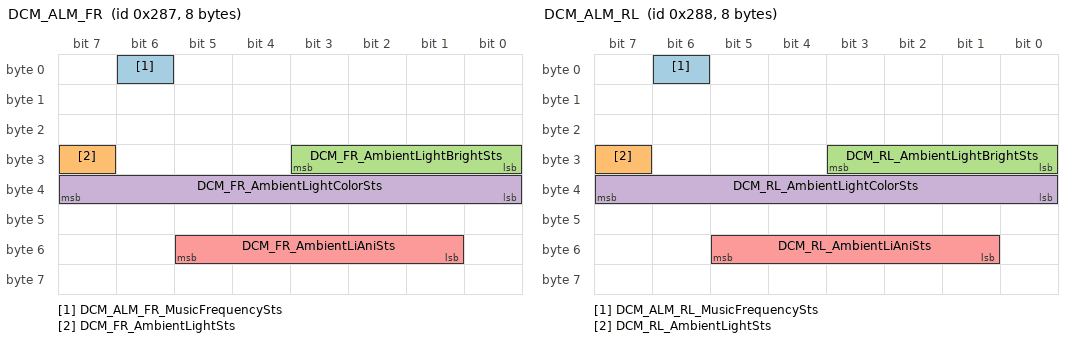
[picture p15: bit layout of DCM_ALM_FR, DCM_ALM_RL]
BO_ 647 DCM_ALM_FR: 8 CGW_SG
 SG_ DCM_ALM_FR_MusicFrequencySts  : 6|1@0+ (1,0) [0|1] "" SGW_SG
 SG_ DCM_FR_AmbientLightSts  : 31|1@0+ (1,0) [0|1] "" SGW_SG
 SG_ DCM_FR_AmbientLightBrightSts  : 27|4@0+ (1,0) [0|10] "" SGW_SG
 SG_ DCM_FR_AmbientLightColorSts  : 39|8@0+ (1,0) [0|255] "" SGW_SG
 SG_ DCM_FR_AmbientLiAniSts  : 53|5@0+ (1,0) [0|25] "" SGW_SG

BO_ 648 DCM_ALM_RL: 8 CGW_SG
 SG_ DCM_ALM_RL_MusicFrequencySts  : 6|1@0+ (1,0) [0|1] "" SGW_SG
 SG_ DCM_RL_AmbientLightSts  : 31|1@0+ (1,0) [0|1] "" SGW_SG
 SG_ DCM_RL_AmbientLightBrightSts  : 27|4@0+ (1,0) [0|10] "" SGW_SG
 SG_ DCM_RL_AmbientLightColorSts  : 39|8@0+ (1,0) [0|255] "" SGW_SG
 SG_ DCM_RL_AmbientLiAniSts  : 53|5@0+ (1,0) [0|25] "" SGW_SG

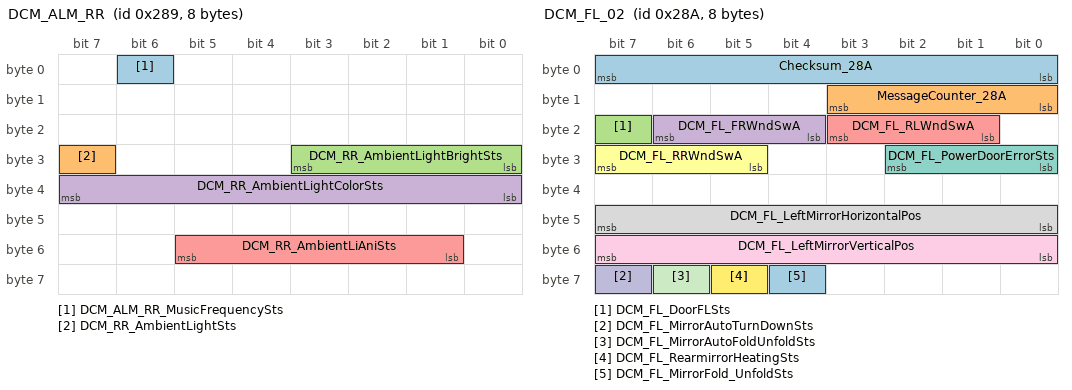
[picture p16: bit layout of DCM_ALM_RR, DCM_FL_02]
BO_ 649 DCM_ALM_RR: 8 CGW_SG
 SG_ DCM_ALM_RR_MusicFrequencySts  : 6|1@0+ (1,0) [0|1] "" SGW_SG
 SG_ DCM_RR_AmbientLightSts  : 31|1@0+ (1,0) [0|1] "" SGW_SG
 SG_ DCM_RR_AmbientLightBrightSts  : 27|4@0+ (1,0) [0|10] "" SGW_SG
 SG_ DCM_RR_AmbientLightColorSts  : 39|8@0+ (1,0) [0|255] "" SGW_SG
 SG_ DCM_RR_AmbientLiAniSts  : 53|5@0+ (1,0) [0|25] "" SGW_SG

BO_ 642 DCM_FL: 8 CGW_SG
 SG_ DCM_FL_CarSharingColorSts  : 7|8@0+ (1,0) [0|255] "" SGW_SG
 SG_ DCM_FL_CarSharingTimeSts  : 11|4@0+ (1,0) [0|9] "s" SGW_SG
 SG_ DCM_FL_PowerDoorModeSts  : 13|2@0+ (1,0) [0|3] "" SGW_SG
 SG_ DCM_FL_FrontKeepOpenSts  : 14|1@0+ (1,0) [0|1] "" SGW_SG
 SG_ DCM_FL_PriorSoundSts  : 15|1@0+ (1,0) [0|1] "" SGW_SG
 SG_ DCM_FL_DoorFLAngle  : 22|7@0+ (1,0) [0|100] "degrees" SGW_SG
 SG_ DCM_FL_DoorFLLockSts  : 23|1@0+ (1,0) [0|1] "" SGW_SG
 SG_ DCM_FL_LinkageAvoidanceReq  : 25|2@0+ (1,0) [0|3] "" SGW_SG
 SG_ DCM_FL_ElectricDoorMovementSts  : 28|3@0+ (1,0) [0|7] "" SGW_SG
 SG_ DCM_FL_DoorAntiPinchSts  : 29|1@0+ (1,0) [0|1] "" SGW_SG
 SG_ DCM_FL_DoorObstacleSts  : 30|1@0+ (1,0) [0|1] "" SGW_SG
 SG_ DCM_FL_FLPESwitchReq  : 31|1@0+ (1,0) [0|1] "" SGW_SG
 SG_ DCM_FL_PWM_POS_STS  : 35|3@0+ (1,0) [0|4] "" SGW_SG
 SG_ DCM_FL_WindowSts  : 38|3@0+ (1,0) [0|5] "" SGW_SG
 SG_ DCM_FL_InsideSwitchReq  : 39|1@0+ (1,0) [0|1] "" SGW_SG
 SG_ DCM_FL_FrontDoorAngleFeedback  : 40|1@0+ (1,0) [0|1] "" SGW_SG
 SG_ DCM_FL_GLASS_LOCATION  : 45|5@0+ (1,0) [0|20] "" SGW_SG
 SG_ DCM_FL_CarSharingLightSts  : 46|1@0+ (1,0) [0|1] "" SGW_SG
 SG_ DCM_FL_WelcomeOnOffSts  : 47|1@0+ (1,0) [0|1] "" SGW_SG

BO_ 650 DCM_FL_02: 8 CGW_SG
 SG_ Checksum_28A  : 7|8@0+ (1,0) [0|255] "" SGW_SG
 SG_ MessageCounter_28A  : 11|4@0+ (1,0) [0|15] "" SGW_SG
 SG_ DCM_FL_DoorFLSts  : 23|1@0+ (1,0) [0|1] "" SGW_SG
 SG_ DCM_FL_FRWndSwA  : 22|3@0+ (1,0) [0|5] "" SGW_SG
 SG_ DCM_FL_RLWndSwA  : 19|3@0+ (1,0) [0|5] "" SGW_SG
 SG_ DCM_FL_RRWndSwA  : 31|3@0+ (1,0) [0|5] "" SGW_SG
 SG_ DCM_FL_PowerDoorErrorSts  : 26|3@0+ (1,0) [0|7] "" SGW_SG
 SG_ DCM_FL_LeftMirrorHorizontalPos  : 47|8@0+ (1,0) [0|100] "percent" SGW_SG
 SG_ DCM_FL_LeftMirrorVerticalPos  : 55|8@0+ (1,0) [0|100] "percent" SGW_SG
 SG_ DCM_FL_MirrorAutoTurnDownSts  : 63|1@0+ (1,0) [0|1] "" SGW_SG
 SG_ DCM_FL_MirrorAutoFoldUnfoldSts  : 62|1@0+ (1,0) [0|1] "" SGW_SG
 SG_ DCM_FL_RearmirrorHeatingSts  : 61|1@0+ (1,0) [0|1] "" SGW_SG
 SG_ DCM_FL_MirrorFold_UnfoldSts  : 60|1@0+ (1,0) [0|1] "" SGW_SG

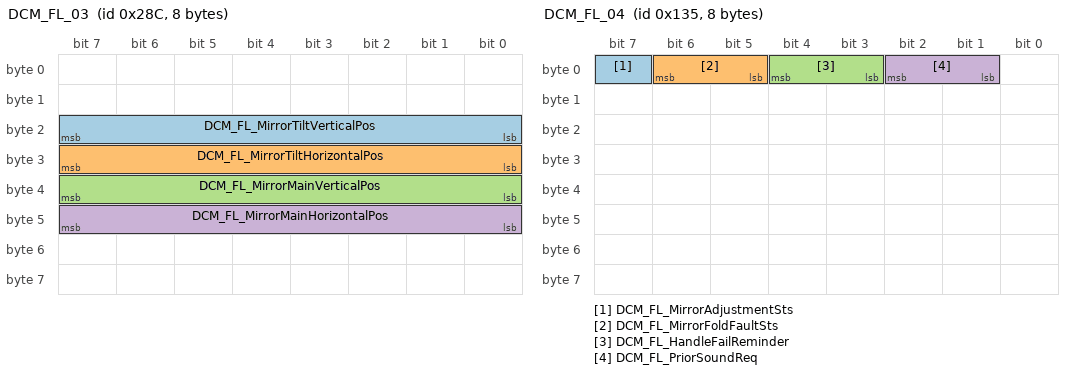
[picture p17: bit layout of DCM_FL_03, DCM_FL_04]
BO_ 652 DCM_FL_03: 8 CGW_SG
 SG_ DCM_FL_MirrorTiltVerticalPos  : 23|8@0+ (1,0) [0|100] "percent" SGW_SG
 SG_ DCM_FL_MirrorTiltHorizontalPos  : 31|8@0+ (1,0) [0|100] "percent" SGW_SG
 SG_ DCM_FL_MirrorMainVerticalPos  : 39|8@0+ (1,0) [0|100] "percent" SGW_SG
 SG_ DCM_FL_MirrorMainHorizontalPos  : 47|8@0+ (1,0) [0|100] "percent" SGW_SG

BO_ 309 DCM_FL_04: 8 CGW_SG
 SG_ DCM_FL_MirrorAdjustmentSts  : 7|1@0+ (1,0) [0|1] "" SGW_SG
 SG_ DCM_FL_MirrorFoldFaultSts  : 6|2@0+ (1,0) [0|3] "" SGW_SG
 SG_ DCM_FL_HandleFailReminder  : 4|2@0+ (1,0) [0|3] "" SGW_SG
 SG_ DCM_FL_PriorSoundReq  : 2|2@0+ (1,0) [0|1] "" SGW_SG

CM_ "Revision:V1.0,
Revision:V1.0.1,
Revision:V1.0.1,
Revision:V1.0.1,
Revision:V1.0.1,
Revision:V1.0.1,
Revision:V1.0.2,
Revision:V1.0.2,
Revision:V1.0.2,
Revision:V1.0.2,
Revision:V1.0.2,
Revision:V1.0.2,
Revision:V1.0.2,
Revision:V1.0.2,
Revision:V1.0.2,
Revision:V1.0.2,
Revision:V1.0.2,
Revision:V1.0.2,
Revision:V1.0.2,
Revision:V1.0.2,
Revision:V1.0.2,
Revision:V1.0.2,
Revision:V1.0.2,
Revision:V1.0.2,
Revision:V1.0.2,
Revision:V1.0.2,
Revision:V1.0.2,
Revision:V1.0.2,
Revision:V1.0.2,
Revision:V1.0.2,
Revision:V1.0.2,
Revision:V1.0.2,
Revision:V1.0.2,
Revision:V1.1,
Revision:V1.1,
Revision:V1.1,
Revision:V1.1,
Revision:V1.1,
Revision:V1.1,
Revision:V1.1,
Revision:V1.1,
Revision:V1.1,
Revision:V1.1,
Revision:V1.1,
Revision:V1.1,
Revision:V1.1,
Revision:V1.1,
Revision:V1.1,
Revision:V1.1,
Revision:V1.1,
Revision:V1.1,
Revision:V1.1,
Revision:V1.1,
Revision:V1.1,
Revision:V1.1,
Revision:V1.1,
Revision:V1.1,
Revision:V1.1,
Revision:V1.1,
Revision:V1.1,
Revision:V1.1,
Revision:V1.1,
Revision:V1.1,
Revision:V1.1,
Revision:V1.1,
Revision:V1.1,
Revision:V1.1,
Revision:V1.1,
Revision:V1.1,
Revision:V1.1,
Revision:V1.1,
Revision:V1.1,
Revision:V1.1,
Revision:V1.1,
Revision:V1.1,
Revision:V1.2,
Revision:V0.1.3,
Revision:V0.1.3,
Revision:V0.1.3,
Revision:V0.1.3,
Revision:V0.1.3,
Revision:V0.1.3,
Revision:V0.1.3,
Revision:V0.2.0,
Revision:V0.2.0,
Revision:V0.2.0,
Revision:V0.2.0,
Revision:V0.2.0,
Revision:V0.2.0,
Revision:V0.2.0,
Revision:V0.2.0,
Revision:V0.2.0,
Revision:V0.2.0,
Revision:V0.2.0,
Revision:V1.0.0,
Revision:V1.0.0,
Revision:V1.1.0,
Revision:V1.1.0,
Revision:V1.1.0,
Revision:V1.0.0,
Revision:V1.0.0,
Revision:V1.0.0,
Revision:V1.0.0,
Revision:V1.0.0,
Revision:V1.0.0,
Revision:V1.0.0,
Revision:V1.0.0,
Revision:V1.0.0,
Revision:V1.0.0,
Revision:V1.0.0,
Revision:V1.0.0,
Revision:V1.0.0,
Revision:V1.0.0,
Revision:V1.0.0,
Revision:V1.0.0,
Revision:V1.0.0,
Revision:V1.0.0,
Revision:V1.0.0,
Revision:V1.0.0,
Revision:V1.0.0,
Revision:V1.0.0,
Revision:V1.0.0,
Revision:V1.0.0,
Revision:V1.0.0,
Revision:V1.0.0,
Revision:V1.0.0,
Revision:V1.0.0,
Revision:V1.0.0,
Revision:V1.0.0,
Revision:V1.0.0,
Revision:V1.0.0,
Revision:V1.0.0,
Revision:V1.0.0,
Revision:V1.0.0,
Revision:V1.0.0,
Revision:V1.0.0,
Revision:V1.0.0,
Revision:V1.0.0,
Revision:V1.0.0,
Revision:V1.0.0,
Revision:V1.0.0,
Revision:V1.0.0,
Revision:V1.0.0,
Revision:V1.0.0,
Revision:V1.0.0,
Revision:V1.0.0,
Revision:V1.0.0,
Revision:V1.0.0,
Revision:V1.0.0,
Revision:V1.0.0,
Revision:V1.0.0,
Revision:V1.0.0,
Revision:V1.0.0,
Revision:V1.0.0,
Revision:V1.0.0,
Revision:V1.0.0,
Revision:V1.0.0,
Revision:V1.0.0,
Revision:V1.0.0,
Revision:V1.0.0,
Revision:V1.0.0,
Revision:V1.0.0,
Revision:V1.0.0,
Revision:V1.0.0,
Revision:V1.0.0,
Revision:V1.0.0,
Revision:V1.0.0,
Revision:V1.0.0,
Revision:V1.0.0,
Revision:V1.0.0,
Revision:V1.0.0,
Revision:V1.0.0,
Revision:V1.0.0,
Revision:V1.0.0,
Revision:V1.0.0,
Revision:V1.0.0,
Revision:V1.0.0,
Revision:V1.0.0,
Revision:V1.0.0,
Revision:V1.0.0,
Revision:V1.0.0,
Revision:V1.0.0,
Revision:V1.0.0,
Revision:V1.0.0,
Revision:V1.0.0,
Revision:V1.0.0,
Revision:V1.0.0,
Revision:V1.0.0,
Revision:V1.0.0,
Revision:V1.0.0,
Revision:V1.0.0,
Revision:V1.0.0,
Revision:V1.0.0,
Revision:V1.0.0,
Revision:V1.0.0,
Revision:V1.0.0,
Revision:V1.0.0,
Revision:V1.0.0,
Revision:V1.0.0,
Revision:V1.0.0,
Revision:V1.0.0,
Revision:V1.0.0,
Revision:V1.0.0,
Revision:V1.0.0,
Revision:V1.0.0,
Revision:V1.0.0,
Revision:V1.0.0,
Revision:V1.0.0,
Revision:V1.0.0,
Revision:V1.0.0,
Revision:V1.0.0,
Revision:V1.0.0,
Revision:V1.0.0,
Revision:V1.0.0,
Revision:V1.0.0,
Revision:V1.0.0,
Revision:V1.0.0,
Revision:V1.0.0,
Revision:V1.0.0,
Revision:V1.0.0,
Revision:V1.0.0,
Revision:V1.0.0,
Revision:V1.0.0,
Revision:V1.0.0,
Revision:V1.0.0,
Revision:V1.0.0,
Revision:V1.0.0,
Revision:V1.0.0,
Revision:V1.0.0,
Revision:V1.0.0,
Revision:V1.0.0,
Revision:V1.0.0,
Revision:V1.0.0,
Revision:V1.0.0,
Revision:V1.0.0,
Revision:V1.0.0,
Revision:V1.0.0,
Revision:V1.0.0,
Revision:V1.0.0,
Revision:V1.0.0,
Revision:V1.0.0,
Revision:V1.0.0,
Revision:V1.0.0,
Revision:V1.0.0,
Revision:V1.0.0,
Revision:V1.0.0,
Revision:V1.0.0,
Revision:V1.0.0,
Revision:V1.0.0,
Revision:V1.0.0,
Revision:V1.0.0,
Revision:V1.0.0,
Revision:V1.0.0,
Revision:V1.0.0,
Revision:V1.0.0,
Revision:V1.0.0,
Revision:V1.0.0,
Revision:V1.0.0,
Revision:V1.0.0,
Revision:V1.0.0,
Revision:V1.0.0,
Revision:V1.0.0,
Revision:V1.0.0,
Revision:V1.0.0,
Revision:V1.0.0,
Revision:V1.0.0,
Revision:V1.0.0,
Revision:V1.0.0,
Revision:V1.0.0,
Revision:V1.0.0,
Revision:V1.0.0,
Revision:V1.0.0,
Revision:V1.0.0,
Revision:V1.0.0,
Revision:V1.0.0,
Revision:V1.0.0,
Revision:V1.0.0,
Revision:V1.0.0,
Revision:V1.0.0,
Revision:V1.0.0,
Revision:V1.0.0,
Revision:V1.0.0,
Revision:V1.0.0,
Revision:V1.0.0,
Revision:V1.0.0,
Revision:V1.0.0,
Revision:V1.0.0,
Revision:V1.0.0,
Revision:V1.0.0,
Revision:V1.0.0,
Revision:V1.0.0,
Revision:V1.0.0,
Revision:V1.0.0,
Revision:V1.0.0,
Revision:V1.0.0,
Revision:V1.0.0,
Revision:V1.0.0,
Revision:V1.0.0,
Revision:V1.0.0,
Revision:V1.0.0,
Revision:V1.0.0,
Revision:V1.0.0,
Revision:V1.0.0,
Revision:V1.0.0,
Revision:V1.0.0,
Revision:V1.0.0,
Revision:V1.0.0,
Revision:V1.0.0,
Revision:V1.0.0,
Revision:V1.0.0,
Revision:V1.0.0,
Revision:V1.0.0,
Revision:V1.0.0,
Revision:V1.0.0,
Revision:V1.0.0,
Revision:V1.0.0,
Revision:V1.0.0,
Revision:V1.0.0,
Revision:V1.0.0,
Revision:V1.0.0,
Revision:V1.0.0,
Revision:V1.0.0,
Revision:V1.0.0,
Revision:V1.0.0,
Revision:V1.0.0,
Revision:V1.0.0,
Revision:V1.0.0,
Revision:V1.0.0,
Revision:V1.0.0,
Revision:V1.0.0,
Revision:V1.0.0,
Revision:V1.0.0,
Revision:V1.0.0,
Revision:V1.0.0,
Revision:V1.0.0,
Revision:V1.0.0,
Revision:V1.0.0,
Revision:V1.0.0,
Revision:V1.0.0,
Revision:V1.0.0,
Revision:V1.0.0,
Revision:V1.0.0,
Revision:V1.0.0,
Revision:V1.0.0,
Revision:V1.1.0,
Revision:V1.1.0,
Revision:V1.1.0,
Revision:V1.1.0,
Revision:V1.1.0,
Revision:V1.1.0,
Revision:V1.1.0,
Revision:V1.1.0,
Revision:V1.1.0,
Revision:V1.1.0,
Revision:V1.1.0,
Revision:V1.1.0,
Revision:V1.1.0,
Revision:V1.1.0,
Revision:V1.1.0,
Revision:V1.1.0,
Revision:V1.1.0,
Revision:V1.1.0,
Revision:V1.1.0,
Revision:V1.1.0,
Revision:V1.1.0,
Revision:V1.1.0,
Revision:V1.1.0,
Revision:V1.1.0,
Revision:V1.1.0,
Revision:V1.1.0,
Revision:V1.1.0,
Revision:V1.1.0,
Revision:V1.1.0,
Revision:V1.1.0,
Revision:V1.1.0,
Revision:V1.1.0,
Revision:V1.1.0,
Revision:V1.1.0,
Revision:V1.1.0,
Revision:V1.1.0,
Revision:V1.1.0,
Revision:V1.1.0,
Revision:V1.1.0,
Revision:V1.1.0,
Revision:V1.1.0,
Revision:V1.1.0,
Revision:V1.1.0,
Revision:V1.1.0,
Revision:V1.1.0,
Revision:V1.1.0,
Revision:V1.1.0,
Revision:V1.1.0,
Revision:V1.1.0,
Revision:V1.1.0,
Revision:V1.1.0,
Revision:V1.1.0,
Revision:V1.1.0,
Revision:V1.1.0,
Revision:V1.1.0,
Revision:V1.1.0,
Revision:V1.1.0,
Revision:V1.1.0,
Revision:V1.1.0,
Revision:V1.1.0,
Revision:V1.1.0,
Revision:V1.1.0,
Revision:V1.1.0,
Revision:V1.1.0,
Revision:V1.1.0,
Revision:V1.1.0,
Revision:V1.1.0,
Revision:V1.1.0,
Revision:V1.1.0,
Revision:V1.1.0,
Revision:V1.1.0,
Revision:V1.1.0,
Revision:V1.1.0,
Revision:V1.1.0,
Revision:V1.1.0,
Revision:V1.1.0,
Revision:V1.1.0,
Revision:V1.1.0,
Revision:V1.1.0,
Revision:V1.1.0,
Revision:V1.1.0,
Revision:V1.1.0,
Revision:V1.1.0,
Revision:V1.1.0,
Revision:V1.1.0,
Revision:V1.1.0,
Revision:V1.1.0,
Revision:V1.1.0,
Revision:V1.1.0,
Revision:V1.1.0,
Revision:V1.1.0,
Revision:V1.1.0,
Revision:V1.1.0,
Revision:V1.1.0,
Revision:V1.1.0,
Revision:V1.1.0,
Revision:V1.1.0,
Revision:V1.1.0,
Revision:V1.1.0,
Revision:V1.1.0,
Revision:V1.1.0,
Revision:V1.1.0,
Revision:V1.1.0,
Revision:V1.1.0,
Revision:V1.1.0,
Revision:V1.1.0,
Revision:V1.1.0,
Revision:V1.1.0,
Revision:V1.1.0,
Revision:V1.1.0,
Revision:V1.1.0,
Revision:V1.1.0,
Revision:V1.1.0,
Revision:V1.1.0,
Revision:V1.1.0,
Revision:V1.1.0,
Revision:V1.1.0,
Revision:V1.1.0,
Revision:V1.1.0,
Revision:V1.1.0,
Revision:V1.1.0,
Revision:V1.1.0,
Revision:V1.1.0,
Revision:V1.1.0,
Revision:V1.1.0,
Revision:V1.1.0,
Revision:V1.1.0,
Revision:V1.1.0,
Revision:V1.1.0,
Revision:V1.1.0,
Revision:V1.1.0,
Revision:V1.1.0,
Revision:V1.1.0,
Revision:V1.1.0,
Revision:V1.1.0,
Revision:V1.1.0,
Revision:V1.1.0,
Revision:V1.1.0,
Revision:V1.2.0,
Revision:V1.2.0,
Revision:V1.2.0,
Revision:V1.2.0,
Revision:V1.2.0,
Revision:V1.2.0,
Revision:V1.2.0,
Revision:V1.2.0,
Revision:V1.2.0,
Revision:V1.2.0,
Revision:V1.2.0,
Revision:V1.2.0,
Revision:V1.2.0,
Revision:V1.2.0,
Revision:V1.2.0,
Revision:V1.2.0,
Revision:V1.2.0,
Revision:V1.2.0,
Revision:V1.2.0,
Revision:V1.2.0,
Revision:V1.2.0,
Revision:V1.2.0,
Revision:V1.2.0,
Revision:V1.2.0,
Revision:V1.2.0,
Revision:V1.2.0,
Revision:V1.2.0,
Revision:V1.2.0,
Revision:V1.2.0,
Revision:V1.2.0,
Revision:V1.2.0,
Revision:V1.2.0,
Revision:V1.2.0,
Revision:V1.2.0,
Revision:V1.2.0,
Revision:V1.2.0,
Revision:V1.2.0,
Revision:V1.2.0,
Revision:V1.2.0,
Revision:V1.2.0,
Revision:V1.2.0,
Revision:V1.2.0,
Revision:V1.2.0,
Revision:V1.2.0,
Revision:V1.2.0,
Revision:V1.2.0,
Revision:V1.2.0,
Revision:V1.2.0,
Revision:V1.2.0,
Revision:V1.2.0,
Revision:V1.2.0,
Revision:V1.2.0,
Revision:V1.2.0,
Revision:V1.2.0,
Revision:V1.2.0,
Revision:V1.2.0,
Revision:V1.2.0,
Revision:V1.2.0,
Revision:V1.2.0,
Revision:V1.2.0,
Revision:V1.2.0,
Revision:V1.2.0,
Revision:V1.2.0,
Revision:V1.2.0,
Revision:V1.2.0,
Revision:V1.2.0,
Revision:V1.2.0,
Revision:V1.2.0,
Revision:V1.2.0,
Revision:V1.2.0,
Revision:V1.2.0,
Revision:V1.2.0,
Revision:V1.2.0,
Revision:V1.2.0,
Revision:V1.2.0,
Revision:V1.2.0,
Revision:V1.2.0,
Revision:V1.2.0,
Revision:V1.2.0,
Revision:V1.2.0,
Revision:V1.2.0,
Revision:V1.2.0,
Revision:V1.2.0,
Revision:V1.2.0,
Revision:V1.2.0,
Revision:V1.2.0,
Revision:V1.2.0,
Revision:V1.2.0,
Revision:V1.2.0,
Revision:V1.2.0,
Revision:V1.2.0,
Revision:V1.2.0,
Revision:V1.2.0,
Revision:V1.2.0,
Revision:V1.2.0,
Revision:V1.2.0,
Revision:V1.2.0,
Revision:V1.2.0,
Revision:V1.2.0,
Revision:V1.2.0,
Revision:V1.2.0,
Revision:V1.2.0,
Revision:V1.2.0,
Revision:V1.2.0,
Revision:V1.2.0,
Revision:V1.2.0,
Revision:V1.2.0,
Revision:V1.2.0,
Revision:V1.2.0,
Revision:V1.2.0,
Revision:V1.2.0,
Revision:V1.2.0,
Revision:V1.2.0,
Revision:V1.2.0,
Revision:V1.2.0,
Revision:V1.2.0,
Revision:V1.2.0,
Revision:V1.2.0,
Revision:V1.2.0,
Revision:V1.2.0,
Revision:V1.2.0,
Revision:V1.2.0,
Revision:V1.2.0,
Revision:V1.2.0,
Revision:V1.2.0,
Revision:V1.2.0,
Revision:V1.2.0,
Revision:V1.2.0,
Revision:V1.2.0,
Revision:V1.2.0,
Revision:V1.2.0,
Revision:V1.2.0,
Revision:V1.2.0,
Revision:V1.2.0,
Revision:V1.2.0,
Revision:V1.2.0,
Revision:V1.2.0,
Revision:V1.2.0,
Revision:V1.2.0,
Revision:V1.2.0,
Revision:V1.2.0,
Revision:V1.2.0,
Revision:V1.2.0,
Revision:V1.2.0,
Revision:V1.2.0,
Revision:V1.2.0,
Revision:V1.2.0,
Revision:V1.2.0,
Revision:V1.2.0,
Revision:V1.2.0,
Revision:V1.2.0,
Revision:V1.2.0,
Revision:V1.2.0,
Revision:V1.2.0,
Revision:V1.2.0,
Revision:V1.2.0,
Revision:V1.2.0,
Revision:V1.2.0,
Revision:V1.2.0,
Revision:V1.2.0,
Revision:V1.2.0,
Revision:V1.2.0,
Revision:V1.2.0,
Revision:V1.2.0,
Revision:V1.2.0,
Revision:V1.2.0,
Revision:V1.2.0,
Revision:V1.2.0,
Revision:V1.2.0,
Revision:V1.2.0,
Revision:V1.2.0,
Revision:V1.2.0,
Revision:V1.2.0,
Revision:V1.2.0,
Revision:V1.2.0,
Revision:V1.2.0,
Revision:V1.2.0,
Revision:V1.2.0,
Revision:V1.2.0,
Revision:V1.2.0,
Revision:V1.2.0,
Revision:V1.2.0,
Revision:V1.2.0,
Revision:V1.2.0,
Revision:V1.2.0,
Revision:V1.2.0,
Revision:V1.2.0,
Revision:V1.2.0,
Revision:V1.2.0,
Revision:V1.2.0,
Revision:V1.2.0,
Revision:V1.2.0,
Revision:V1.2.0,
Revision:V1.2.0,
Revision:V1.2.0,
Revision:V1.2.0,
Revision:V1.2.0,
Revision:V1.2.0,
Revision:V1.2.0,
Revision:V1.2.0,
Revision:V1.2.0,
Revision:V1.2.0,
Revision:V1.2.0,
Revision:V1.2.0,
Revision:V1.2.0,
Revision:V1.2.0,
Revision:V1.2.0,
Revision:V1.2.0,
Revision:V1.2.0,
Revision:V1.2.0,
Revision:V1.2.0,
Revision:V1.2.0,
Revision:V1.2.0,
Revision:V1.2.0,
Revision:V1.2.0,
Revision:V1.2.0,
Revision:V1.2.0,
Revision:V1.2.0,
Revision:V1.2.0,
Revision:V1.2.0,
Revision:V1.2.0,
Revision:V1.2.0,
Revision:V1.2.0,
Revision:V1.2.0,
Revision:V1.2.0,
Revision:V1.2.0,
Revision:V1.2.0,
Revision:V1.2.0,
Revision:V1.2.0,
Revision:V1.2.0,
Revision:V1.2.0,
Revision:V1.2.0,
Revision:V1.2.0,
Revision:V1.2.0,
Revision:V1.2.0,
Revision:V1.2.0,
Revision:V1.2.0,
Revision:V1.2.0,
Revision:V1.2.0,
Revision:V1.2.0,
Revision:V1.2.0,
Revision:V1.2.0,
Revision:V1.2.0,
Revision:V1.2.0,
Revision:V1.2.0,
Revision:V1.2.0,
Revision:V1.2.0,
Revision:V1.2.0,
Revision:V1.2.0,
Revision:V1.2.0,
Revision:V1.2.0,
Revision:V1.2.0,
Revision:V1.2.0,
Revision:V1.2.0,
Revision:V1.2.0,
Revision:V1.2.0,
Revision:V1.2.0,
Revision:V1.2.0,
Revision:V1.2.0,
Revision:V1.2.0,
Revision:V1.2.0,
Revision:V1.2.0,
Revision:V1.2.0,
Revision:V1.2.0,
Revision:V1.2.0,
Revision:V1.2.0,
Revision:V1.2.0,
Revision:V1.2.0,
Revision:V1.2.0,
Revision:V1.2.0,
Revision:V1.2.0,
Revision:V1.2.0,
Revision:V1.2.0,
Revision:V1.2.0,
Revision:V1.2.0,
Revision:V1.2.0,
Revision:V1.2.0,
Revision:V1.2.0,
Revision:V1.2.0,
Revision:V1.2.0,
Revision:V1.2.0,
Revision:V1.2.0,
Revision:V1.2.0,
Revision:V1.2.0,
Revision:V1.2.0,
Revision:V1.2.0,
Revision:V1.2.0,
Revision:V1.2.0,
Revision:V1.2.0,
Revision:V1.2.0,
Revision:V1.2.0,
Revision:V1.2.0,
Revision:V1.2.0,
Revision:V1.2.0,
Revision:V1.2.0,
Revision:V1.2.0,
Revision:V1.2.0,
Revision:V1.2.0,
Revision:V1.2.0,
Revision:V1.2.0,
Revision:V1.2.0,
Revision:V1.2.0,
Revision:V1.2.0,
Revision:V1.2.0,
Revision:V1.2.0,
Revision:V1.2.0,
Revision:V1.3.0,
Revision:V1.3.0,
Revision:V1.3.0,
Revision:V1.3.0,
Revision:V1.3.0,
Revision:V1.3.0,
Revision:V1.3.0,
Revision:V1.3.0,
Revision:V1.3.0,
Revision:V1.3.0,
Revision:V1.3.0,
Revision:V1.3.0,
Revision:V1.3.0,
Revision:V1.3.0,
Revision:V1.3.0,
Revision:V1.3.0,
Revision:V1.3.0,
Revision:V1.3.0,
Revision:V1.3.0,
Revision:V1.3.0,
Revision:V1.3.0,
Revision:V1.3.0,
Revision:V1.3.0,
Revision:V1.3.0,
Revision:V1.3.0,
Revision:V1.3.0,
Revision:V1.3.0,
Revision:V1.3.0,
Revision:V1.3.0,
Revision:V1.3.0,
Revision:V1.3.0,
Revision:V1.3.0,
Revision:V1.3.0,
Revision:V1.3.0,
Revision:V1.3.0,
Revision:V1.3.0,
Revision:V1.3.0,
Revision:V1.3.0,
Revision:V1.3.0,
Revision:V1.3.0,
Revision:V1.3.0,
Revision:V1.3.0,
Revision:V1.3.0,
Revision:V1.3.0,
Revision:V1.3.0,
Revision:V1.3.0,
Revision:V1.3.0,
Revision:V1.3.0,
Revision:V1.3.0,
Revision:V1.3.0,
Revision:V1.3.0,
Revision:V1.3.0,
Revision:V1.3.0,
Revision:V1.3.0,
Revision:V1.3.0,
Revision:V1.3.0,
Revision:V1.3.0,
Revision:V1.3.0,
Revision:V1.3.0,
Revision:V1.3.0,
Revision:V1.3.0,
Revision:V1.3.0,
Revision:V1.3.0,
Revision:V1.3.0,
Revision:V1.3.0,
Revision:V1.3.0,
Revision:V1.3.0,
Revision:V1.3.0,
Revision:V1.3.0,
Revision:V1.3.0,
Revision:V1.3.0,
Revision:V1.3.0,
Revision:V1.3.0,
Revision:V1.3.0,
Revision:V1.3.0,
Revision:V1.3.0,
Revision:V1.3.0,
Revision:V1.3.0,
Revision:V1.3.0,
Revision:V1.3.0,
Revision:V1.3.0,
Revision:V1.3.0,
Revision:V1.3.0,
Revision:V1.3.0,
Revision:V1.3.0,
Revision:V1.3.0,
Revision:V1.3.0,
Revision:V1.3.0,
Revision:V1.3.0,
Revision:V1.3.0,
Revision:V1.3.0,
Revision:V1.3.0,
Revision:V1.3.0,
Revision:V1.3.0,
Revision:V1.3.0,
Revision:V1.3.0,
Revision:V1.3.0,
Revision:V1.3.0,
Revision:V1.3.0,
Revision:V1.3.0,
Revision:V1.3.0,
Revision:V1.3.0,
Revision:V1.3.0,
Revision:V1.3.0,
Revision:V1.3.0,
Revision:V1.3.0,
Revision:V1.3.0,
Revision:V1.3.0,
Revision:V1.3.0,
Revision:V1.3.0,
Revision:V1.3.0,
Revision:V1.3.0,
Revision:V1.3.0,
Revision:V1.3.0,
Revision:V1.3.0,
Revision:V1.3.0,
Revision:V1.3.0,
Revision:V1.3.0,
Revision:V1.3.0,
Revision:V1.3.0,
Revision:V1.3.0,
Revision:V1.3.0,
Revision:V1.3.0,
Revision:V1.3.0,
Revision:V1.3.0,
Revision:V1.3.0,
Revision:V1.3.0,
Revision:V1.3.0,
Revision:V1.3.0,
Revision:V1.3.0,
Revision:V1.3.0,
Revision:V1.3.0,
Revision:V1.3.0,
Revision:V1.3.0,
Revision:V1.3.0,
Revision:V1.3.0,
Revision:V1.3.0,
Revision:V1.3.0,
Revision:V1.3.0,
Revision:V1.3.0,
Revision:V1.3.0,
Revision:V1.3.0,
Revision:V1.3.0,
Revision:V1.3.0,
Revision:V1.3.0,
Revision:V1.3.0,
Revision:V1.3.0,
Revision:V1.3.0,
Revision:V1.3.0,
Revision:V1.3.0,
Revision:V1.3.0,
Revision:V1.3.0,
Revision:V1.3.0,
Revision:V1.3.0,
Revision:V1.3.0,
Revision:V1.3.0,
Revision:V1.3.0,
Revision:V1.3.0,
Revision:V1.3.0,
Revision:V1.3.0,
Revision:V1.3.0,
Revision:V1.3.0,
Revision:V1.3.0,
Revision:V1.3.0,
Revision:V1.3.0,
Revision:V1.3.0,
Revision:V1.3.0,
Revision:V1.3.0,
Revision:V1.3.0,
Revision:V1.3.0,
Revision:V1.3.0,
Revision:V1.3.0,
Revision:V1.3.0,
Revision:V1.3.0,
Revision:V1.3.0,
Revision:V1.3.0,
Revision:V1.3.0,
Revision:V1.3.0,
Revision:V1.3.0,
Revision:V1.3.0,
Revision:V1.3.0,
Revision:V1.3.0,
Revision:V1.3.0,
Revision:V1.3.0,
Revision:V1.3.0,
Revision:V1.3.0,
Revision:V1.3.0,
Revision:V1.3.0,
Revision:V1.3.0,
Revision:V1.3.0,
Revision:V1.3.0,
Revision:V1.3.0,
Revision:V1.3.0,
Revision:V1.3.0,
Revision:V1.3.0,
Revision:V1.3.0,
Revision:V1.3.0,
Revision:V1.3.0,
Revision:V1.3.0,
Revision:V1.3.0,
Revision:V1.3.0,
Revision:V1.3.0,
Revision:V1.3.0,
Revision:V1.3.0,
Revision:V1.3.0,
Revision:V1.3.0,
Revision:V1.3.0,
Revision:V1.3.0,
Revision:V1.3.0,
Revision:V1.3.0,
Revision:V1.3.0,
Revision:V1.3.0,
Revision:V1.3.0,
Revision:V1.3.0,
Revision:V1.3.0,
Revision:V1.3.0,
Revision:V1.3.0,
Revision:V1.3.0,
Revision:V1.3.0,
Revision:V1.3.0,
Revision:V1.3.0,
Revision:V1.3.0,
Revision:V1.3.0,
Revision:V1.3.0,
Revision:V1.3.0,
Revision:V1.3.0,
Revision:V1.3.0,
Revision:V1.3.0,
Revision:V1.3.0,
Revision:V1.3.0,
Revision:V1.3.0,
Revision:V1.3.0,
Revision:V1.3.0,
Revision:V1.3.0,
Revision:V1.3.0,
Revision:V1.3.0,
Revision:V1.3.0,
Revision:V1.3.0,
Revision:V1.3.0,
Revision:V1.3.0,
Revision:V1.3.0,
Revision:V1.3.0,
Revision:V1.3.0,
Revision:V1.3.0,
Revision:V1.3.0,
Revision:V1.3.0,
Revision:V1.3.0,
Revision:V1.3.0,
Revision:V1.3.0,
Revision:V1.3.0,
Revision:V1.3.0,
Revision:V1.3.0,
Revision:V1.3.0,
Revision:V1.3.0,
Revision:V1.3.0,
Revision:V1.3.0,
Revision:V1.3.0,
Revision:V1.3.0,
Revision:V1.3.0,
Revision:V1.3.0,
Revision:V1.3.0,
Revision:V1.3.0,
Revision:V1.3.0,
Revision:V1.3.0,
Revision:V1.3.0,
Revision:V1.3.0,
Revision:V1.3.0,
Revision:V1.3.0,
Revision:V1.3.0,
Revision:V1.3.0,
Revision:V1.3.0,
Revision:V1.3.0,
Revision:V1.3.0,
Revision:V1.3.0,
Revision:V1.3.0,
Revision:V1.3.0,
Revision:V1.3.0,
Revision:V1.3.0,
Revision:V1.3.0,
Revision:V1.3.0,
Revision:V1.3.0,
Revision:V1.3.0,
Revision:V1.3.0,
Revision:V1.3.0,
Revision:V1.3.0,
Revision:V1.3.0,
Revision:V1.3.0,
Revision:V1.3.0,
Revision:V1.3.0,
Revision:V1.3.0,
Revision:V1.3.0,
Revision:V1.3.0,
Revision:V1.3.0,
Revision:V1.3.0,
Revision:V1.3.0,
Revision:V1.3.0,
Revision:V1.3.0,
Revision:V1.3.0,
Revision:V1.3.0,
Revision:V1.3.0,
Revision:V1.3.0,
Revision:V1.3.0,
Revision:V1.3.0,
Revision:V1.3.0,
Revision:V1.3.0,
Revision:V1.3.0,
Revision:V1.3.0,
Revision:V1.3.0,
Revision:V1.3.0,
Revision:V1.3.0,
Revision:V1.3.0,
Revision:V1.3.0,
Revision:V1.3.0,
Revision:V1.3.0,
Revision:V1.3.0,
Revision:V1.3.0,
Revision:V1.3.0,
Revision:V1.3.0,
Revision:V1.3.0,
Revision:V1.3.0,
Revision:V1.3.0,
Revision:V1.3.0,
Revision:V1.3.0,
Revision:V1.3.0,
Revision:V1.3.0,
Revision:V1.3.0,
Revision:V1.3.0,
Revision:V1.3.0,
Revision:V1.3.0,
Revision:V1.3.0,
Revision:V1.3.0,
Revision:V1.3.0,
Revision:V1.3.0,
Revision:V1.3.0,
Revision:V1.3.0,
Revision:V1.3.0,
Revision:V1.3.0,
Revision:V1.3.0,
Revision:V1.3.0,
Revision:V1.3.0,
Revision:V1.3.0,
Revision:V1.3.0,
Revision:V1.3.0,
Revision:V1.3.0,
Revision:V1.3.0,
Revision:V1.3.0,
Revision:V1.3.0,
Revision:V1.3.0,
Revision:V1.3.0,
Revision:V1.3.0,
Revision:V1.3.0,
Revision:V1.3.0,
Revision:V1.3.0,
Revision:V1.3.0,
Revision:V1.3.0,
Revision:V1.3.0,
Revision:V1.3.0,
Revision:V1.3.0,
Revision:V1.3.0,
Revision:V1.3.0,
Revision:V1.3.0,
Revision:V1.3.0,
Revision:V1.3.0,
Revision:V1.3.0,
Revision:V1.3.0,
Revision:V1.3.0,
Revision:V1.3.0,
Revision:V1.3.0,
Revision:V1.3.0,
Revision:V1.3.0,
Revision:V1.3.0,
Revision:V1.3.0,
Revision:V1.3.0,
Revision:V1.3.0,
Revision:V1.3.0,
Revision:V1.3.0,
Revision:V1.3.0,
Revision:V1.3.0,
Revision:V1.3.0,
Revision:V1.3.0,
Revision:V1.3.0,
Revision:V1.3.0,
Revision:V1.3.0,
Revision:V1.3.0,
Revision:V1.3.0,
Revision:V1.3.0,
Revision:V1.3.0,
Revision:V1.3.0,
Revision:V1.3.0,
Revision:V1.3.0,
Revision:V1.3.0,
Revision:V1.3.0,
Revision:V1.3.0,
Revision:V1.3.0,
Revision:V1.3.0,
Revision:V1.3.0,
Revision:V1.3.0,
Revision:V1.3.0,
Revision:V1.3.0,
Revision:V1.3.0,
Revision:V1.3.0,
Revision:V1.3.0,
Revision:V1.3.0,
Revision:V1.3.0,
Revision:V1.3.0,
Revision:V1.3.0,
Revision:V1.3.0,
Revision:V1.3.0,
Revision:V1.3.0,
Revision:V1.3.0,
Revision:V1.3.0,
Revision:V1.3.0,
Revision:V1.3.0,
Revision:V1.3.0,
Revision:V1.3.0,
Revision:V1.3.0,
Revision:V1.3.0,
Revision:V1.3.0,
Revision:V1.3.0,
Revision:V1.3.0,
Revision:V1.3.0,
Revision:V1.3.0,
Revision:V1.3.0,
Revision:V1.3.0,
Revision:V1.3.0,
Revision:V1.3.0,
Revision:V1.3.0,
Revision:V1.3.0,
Revision:V1.3.0,
Revision:V1.3.0,
Revision:V1.3.0,
Revision:V1.3.0,
Revision:V1.3.0,
Revision:V1.3.0,
Revision:V1.3.0,
Revision:V1.3.0,
Revision:V1.3.0,
Revision:V1.3.0,
Revision:V1.3.0,
Revision:V1.3.0,
Revision:V1.3.0,
Revision:V1.3.0,
Revision:V1.3.0,
Revision:V1.3.0,
Revision:V1.3.0,
Revision:V1.3.0,
Revision:V1.3.0,
Revision:V1.3.0,
Revision:V1.3.0,
Revision:V1.3.0,
Revision:V1.3.0,
Revision:V1.3.0,
Revision:V1.3.0,
Revision:V1.3.0,
Revision:V1.3.0,
Revision:V1.3.0,
Revision:V1.3.0,
Revision:V1.3.0,
Revision:V1.3.0,
Revision:V1.3.0,
Revision:V1.3.0,
Revision:V1.3.0,
Revision:V1.3.0,
Revision:V1.3.0,
Revision:V1.3.0,
Revision:V1.3.0,
Revision:V1.3.0,
Revision:V1.3.0,
Revision:V1.3.0,
Revision:V1.3.0,
Revision:V1.3.0,
Revision:V1.3.0,
Revision:V1.3.0,
Revision:V1.3.0,
Revision:V1.3.0,
Revision:V1.3.0,
Revision:V1.3.0,
Revision:V1.3.0,
Revision:V1.3.0,
Revision:V1.3.0,
Revision:V1.3.0,
Revision:V1.3.0,
Revision:V1.3.0,
Revision:V1.3.0,
Revision:V1.3.0,
Revision:V1.3.0,
Revision:V1.3.0,
Revision:V1.3.0,
Revision:V1.3.0,
Revision:V1.3.0,
Revision:V1.3.0,
Revision:V1.3.0,
Revision:V1.3.0,
Revision:V1.3.0,
Revision:V1.3.0,
Revision:V1.3.0,
Revision:V1.3.0,
Revision:V1.3.0,
Revision:V1.3.0,
Revision:V1.3.0,
Revision:V1.3.0,
Revision:V1.3.0,
Revision:V1.3.0,
Revision:V1.3.0,
Revision:V1.3.0,
Revision:V1.3.0,
Revision:V1.3.0,
Revision:V1.3.0,
Revision:V1.3.0,
Revision:V1.3.0,
Revision:V1.3.0,
Revision:V1.3.0,
Revision:V1.3.0,
Revision:V1.3.0,
Revision:V1.3.0,
Revision:V1.3.0,
Revision:V1.3.0,
Revision:V1.3.0,
Revision:V1.3.0,
Revision:V1.3.0,
Revision:V1.3.0,
Revision:V1.3.0,
Revision:V1.3.0,
Revision:V1.3.0,
Revision:V1.3.0,
Revision:V1.3.0,
Revision:V1.3.0,
Revision:V1.3.0,
Revision:V1.3.0,
Revision:V1.3.0,
Revision:V1.3.0,
Revision:V1.3.0,
Revision:V1.3.0,
Revision:V1.3.0,
Revision:V1.3.0,
Revision:V1.3.0,
Revision:V1.3.0,
Revision:V1.3.0,
Revision:V1.3.0,
Revision:V1.3.0,
Revision:V1.3.0,
Revision:V1.3.0,
Revision:V1.3.0,
Revision:V1.3.0,
Revision:V1.3.0,
Revision:V1.3.0,
Revision:V1.3.0,
Revision:V1.3.0,
Revision:V1.3.0,
Revision:V1.3.0,
Revision:V1.3.0,
Revision:V1.3.0,
Revision:V1.3.0,
Revision:V1.3.0,
Revision:V1.3.0,
Revision:V1.3.0,
Revision:V1.3.0,
Revision:V1.3.0,
Revision:V1.3.0,
Revision:V1.3.0,
Revision:V1.3.0,
Revision:V1.3.0,
Revision:V1.3.0,
Revision:V1.3.0,
Revision:V1.3.0,
Revision:V1.3.0,
Revision:V1.3.0,
Revision:V1.3.0,
Revision:V1.3.0,
Revision:V1.3.0,
Revision:V1.3.0,
Revision:V1.3.0,
Revision:V1.3.0,
Revision:V1.3.0,
Revision:V1.3.0,
Revision:V1.3.0,
Revision:V1.3.0,
Revision:V1.3.0,
Revision:V1.3.0,
Revision:V1.3.0,
Revision:V1.3.0,
Revision:V1.3.0,
Revision:V1.3.0,
Revision:V1.3.0,
Revision:V1.3.0,
Revision:V1.3.0,
Revision:V1.3.0,
Revision:V1.3.0,
Revision:V1.3.0,
Revision:V1.3.0,
Revision:V1.3.0,
Revision:V1.3.0,
Revision:V1.3.0,
Revision:V1.3.0,
Revision:V1.3.0,
Revision:V1.3.0,
Revision:V1.3.0,
Revision:V1.3.0,
Revision:V1.3.0,
Revision:V1.3.0,
Revision:V1.3.0,
Revision:V1.3.0,
Revision:V1.3.0,
Revision:V1.3.0,
Revision:V1.3.0,
Revision:V1.3.0,
Revision:V1.3.0,
Revision:V1.3.0,
Revision:V1.3.0,
Revision:V1.3.0,
Revision:V1.3.0,
Revision:V1.3.0,
Revision:V1.3.0,
Revision:V1.3.0,
Revision:V1.3.0,
Revision:V1.3.0,
Revision:V1.3.0,
Revision:V1.3.0,
Revision:V1.3.0,
Revision:V1.3.0,
Revision:V1.3.0,
Revision:V1.3.0,
Revision:V1.3.0,
Revision:V1.3.0,
Revision:V1.3.0,
Revision:V1.3.0,
Revision:V1.3.0,
Revision:V1.3.0,
Revision:V1.3.0,
Revision:V1.3.0,
Revision:V1.3.0,
Revision:V1.3.0,
Revision:V1.3.0,
Revision:V1.3.0,
Revision:V1.3.0,
Revision:V1.3.0,
Revision:V1.3.0,
Revision:V1.3.0,
Revision:V1.3.0,
Revision:V1.3.0,
Revision:V1.3.0,
Revision:V1.3.0,
Revision:V1.3.0,
Revision:V1.3.0,
Revision:V1.3.0,
Revision:V1.3.0,
Revision:V1.3.0,
Revision:V1.3.0,
Revision:V1.3.0,
Revision:V1.3.0,
Revision:V1.3.0,
Revision:V1.3.0,
Revision:V1.3.0,
Revision:V1.3.0,
Revision:V1.3.0,
Revision:V1.3.0,
Revision:V1.3.0,
Revision:V1.3.0,
Revision:V1.3.0,
Revision:V1.3.0,
Revision:V1.3.0,
Revision:V1.3.0,
Revision:V1.3.0,
Revision:V1.3.0,
Revision:V1.3.0,
Revision:V1.3.0,
Revision:V1.3.0,
Revision:V1.3.0,
Revision:V1.3.0,
Revision:V1.3.0,
Revision:V1.3.0,
Revision:V1.3.0,
Revision:V1.3.0,
Revision:V1.3.0,
Revision:V1.3.0,
Revision:V1.3.0,
Revision:V1.3.0,
Revision:V1.3.0,
Revision:V1.3.0,
Revision:V1.3.0,
Revision:V1.3.0,
Revision:V1.3.0,
Revision:V1.3.0,
Revision:V1.3.0,
Revision:V1.3.0,
Revision:V1.3.0,
Revision:V1.3.0,
Revision:V1.3.0,
Revision:V1.3.0,
Revision:V1.3.0,
Revision:V1.3.0,
Revision:V1.3.0,
Revision:V1.3.0,
Revision:V1.3.0,
Revision:V1.3.0,
Revision:V1.3.0,
Revision:V1.3.0,
Revision:V1.3.0,
Revision:V1.3.0,
Revision:V1.3.0,
Revision:V1.3.0,
Revision:V1.3.0,
Revision:V1.3.0,
Revision:V1.3.0,
Revision:V1.3.0,
Revision:V1.3.0,
Revision:V1.3.0,
Revision:V1.3.0,
Revision:V1.3.0,
Revision:V1.3.0,
Revision:V1.3.0,
Revision:V1.3.0,
Revision:V1.3.0,
Revision:V1.3.0,
Revision:V1.3.0,
Revision:V1.3.0,
Revision:V1.3.0,
Revision:V1.3.0,
Revision:V1.3.0,
Revision:V1.3.0,
Revision:V1.3.0,
Revision:V1.3.0,
Revision:V1.3.0,
Revision:V1.3.0,
Revision:V1.3.0,
Revision:V1.3.0,
Revision:V1.3.0,
Revision:V1.3.0,
Revision:V1.3.0,
Revision:V1.3.0,
Revision:V1.3.0,
Revision:V1.3.0,
Revision:V1.3.0,
Revision:V1.3.0,
Revision:V1.3.0,
Revision:V1.3.0,
Revision:V1.3.0,
Revision:V1.3.0,
Revision:V1.3.0,
Revision:V1.3.0,
Revision:V1.3.0,
Revision:V1.3.0,
Revision:V1.3.0,
Revision:V1.3.0,
Revision:V1.3.0,
Revision:V1.3.0,
Revision:V1.3.0,
Revision:V1.3.0,
Revision:V1.3.0,
Revision:V1.3.0,
Revision:V1.3.0,
Revision:V1.3.0,
Revision:V1.3.0,
Revision:V1.3.0,
Revision:V1.3.0,
Revision:V1.3.0,
Revision:V1.3.0,
Revision:V1.3.0,
Revision:V1.3.0,
Revision:V1.3.0,
Revision:V1.3.0,
Revision:V1.3.0,
Revision:V1.3.0,
Revision:V1.3.0,
Revision:V1.3.0,
Revision:V1.3.0,
Revision:V1.3.0,
Revision:V1.3.0,
Revision:V1.3.0,
Revision:V1.3.0,
Revision:V1.3.0,
Revision:V1.3.0,
Revision:V1.3.0,
Revision:V1.3.0,
Revision:V1.3.0,
Revision:V1.3.0,
Revision:V1.3.0,
Revision:V1.3.0,
Revision:V1.3.0,
Revision:V1.3.0,
Revision:V1.3.0,
Revision:V1.3.0,
Revision:V1.3.0,
Revision:V1.3.0,
Revision:V1.3.0,
Revision:V1.3.0,
Revision:V1.3.0,
Revision:V1.3.0,
Revision:V1.3.0,
Revision:V1.3.0,
Revision:V1.3.0,
Revision:V1.3.0,
Revision:V1.3.0,
Revision:V1.3.0,
Revision:V1.3.0,
Revision:V1.3.0,
Revision:V1.3.0,
Revision:V1.3.0,
Revision:V1.3.0,
Revision:V1.3.0,
Revision:V1.3.0,
Revision:V1.3.0,
Revision:V1.3.0,
Revision:V1.3.0,
Revision:V1.3.0,
Revision:V1.3.0,
Revision:V1.3.0,
Revision:V1.3.0,
Revision:V1.3.0,
Revision:V1.3.0,
Revision:V1.3.0,
Revision:V1.3.0,
Revision:V1.3.0,
Revision:V1.3.0,
Revision:V1.3.0,
Revision:V1.3.0,
Revision:V1.3.0,
Revision:V1.3.0,
Revision:V1.3.0,
Revision:V1.3.0,
Revision:V1.3.0,
Revision:V1.3.0,
Revision:V1.3.0,
Revision:V1.3.0,
Revision:V1.3.0,
Revision:V1.3.0,
Revision:V1.3.0,
Revision:V1.3.0,
Revision:V1.3.0,
Revision:V1.3.0,
Revision:V1.3.0,
Revision:V1.3.0,
Revision:V1.3.0,
Revision:V1.3.0,
Revision:V1.3.0,
Revision:V1.3.0,
Revision:V1.3.0,
Revision:V1.3.0,
Revision:V1.3.0,
Revision:V1.3.0,
Revision:V1.3.0,
Revision:V1.3.0,
Revision:V1.3.0,
Revision:V1.3.0,
Revision:V1.3.0,
Revision:V1.3.0,
Revision:V1.3.0,
Revision:V1.3.0,
Revision:V1.3.0,
Revision:V1.3.0,
Revision:V1.3.0,
Revision:V1.3.0,
Revision:V1.3.0,
Revision:V1.3.0,
Revision:V1.3.0,
Revision:V1.3.0,
Revision:V1.3.0,
Revision:V1.3.0,
Revision:V1.3.0,
Revision:V1.3.0,
Revision:V1.3.0,
Revision:V1.4.0,
Revision:V1.4.0,
Revision:V1.4.0,
Revision:V1.4.0,
Revision:V1.4.0,
Revision:V1.4.0,
Revision:V1.4.0,
Revision:V1.4.0,
Revision:V1.4.0,
Revision:V1.4.0,
Revision:V1.4.0,
Revision:V1.4.0,
Revision:V1.4.0,
Revision:V1.4.0,
Revision:V1.4.0,
Revision:V1.4.0,
Revision:V1.4.0,
Revision:V1.4.0,
Revision:V1.4.0,
Revision:V1.4.0,
Revision:V1.4.0,
Revision:V1.4.0,
Revision:V1.4.0,
Revision:V1.4.0,
Revision:V1.4.0,
Revision:V1.4.0,
Revision:V1.4.0,
Revision:V1.4.0,
Revision:V1.4.0,
Revision:V1.4.0,
Revision:V1.4.0,
Revision:V1.4.0,
Revision:V1.4.0,
Revision:V1.4.0,
Revision:V1.4.0,
Revision:V1.4.0,
Revision:V1.4.0,
Revision:V1.4.0,
Revision:V1.4.0,
Revision:V1.4.0,
Revision:V1.4.0,
Revision:V1.4.0,
Revision:V1.4.0,
Revision:V1.4.0,
Revision:V1.4.0,
Revision:V1.4.0,
Revision:V1.4.0,
Revision:V1.4.0,
Revision:V1.4.0,
Revision:V1.4.0,
Revision:V1.4.0,
Revision:V1.4.0,
Revision:V1.4.0,
Revision:V1.4.0,
Revision:V1.4.0,
Revision:V1.4.0,
Revision:V1.4.0,
Revision:V1.4.0,
Revision:V1.4.0,
Revision:V1.4.0,
Revision:V1.4.0,
Revision:V1.4.0,
Revision:V1.4.0,
Revision:V1.4.0,
Revision:V1.4.0,
Revision:V1.4.0,
Revision:V1.4.0,
Revision:V1.4.0,
Revision:V1.4.0,
Revision:V1.4.0,
Revision:V1.4.0,
Revision:V1.4.0,
Revision:V1.4.0,
Revision:V1.4.0,
Revision:V1.4.0,
Revision:V1.4.0,
Revision:V1.4.0,
Revision:V1.4.0,
Revision:V1.4.0,
Revision:V1.4.0,
Revision:V1.4.0,
Revision:V1.4.0,
Revision:V1.4.0,
Revision:V1.4.0,
Revision:V1.4.0,
Revision:V1.4.0,
Revision:V1.4.0,
Revision:V1.4.0,
Revision:V1.4.0,
Revision:V1.4.0,
Revision:V1.4.0,
Revision:V1.4.0,
Revision:V1.4.0,
Revision:V1.4.0,
Revision:V1.4.0,
Revision:V1.4.0,
Revision:V1.4.0,
Revision:V1.4.0,
Revision:V1.4.0,
Revision:V1.4.0,
Revision:V1.4.0,
Revision:V1.4.0,
Revision:V1.4.0,
Revision:V1.4.0,
Revision:V1.4.0,
Revision:V1.4.0,
Revision:V1.4.0,
Revision:V1.4.0,
Revision:V1.4.0,
Revision:V1.4.0,
Revision:V1.4.0,
Revision:V1.4.0,
Revision:V1.4.0,
Revision:V1.4.0,
Revision:V1.4.0,
Revision:V1.4.0,
Revision:V1.4.0,
Revision:V1.4.0,
Revision:V1.4.0,
Revision:V1.4.0,
Revision:V1.4.0,
Revision:V1.4.0,
Revision:V1.4.0,
Revision:V1.4.0,
Revision:V1.4.0,
Revision:V1.4.0,
Revision:V1.4.0,
Revision:V1.4.0,
Revision:V1.4.0,
Revision:V1.4.0,
Revision:V1.4.0,
Revision:V1.4.0,
Revision:V1.4.0,
Revision:V1.4.0,
Revision:V1.4.0,
Revision:V1.4.0,
Revision:V1.4.0,
Revision:V1.4.0,
Revision:V1.4.0,
Revision:V1.4.0,
Revision:V1.4.0,
Revision:V1.4.0,
Revision:V1.4.0,
Revision:V1.4.0,
Revision:V1.4.0,
Revision:V1.4.0,
Revision:V1.4.0,
Revision:V1.4.0,
Revision:V1.4.0,
Revision:V1.4.0,
Revision:V1.4.0,
Revision:V1.4.0,
Revision:V1.4.0,
Revision:V1.4.0,
Revision:V1.4.0,
Revision:V1.4.0,
Revision:V1.4.0,
Revision:V1.4.0,
Revision:V1.4.0,
Revision:V1.4.0,
Revision:V1.4.0,
Revision:V1.4.0,
Revision:V1.4.0,
Revision:V1.4.0,
Revision:V1.4.0,
Revision:V1.4.0,
Revision:V1.4.0,
Revision:V1.4.0,
Revision:V1.4.0,
Revision:V1.4.0,
Revision:V1.4.0,
Revision:V1.4.0,
Revision:V1.4.0,
Revision:V1.4.0,
Revision:V1.4.0,
Revision:V1.4.0,
Revision:V1.4.0,
Revision:V1.4.0,
Revision:V1.4.0,
Revision:V1.4.0,
Revision:V1.4.0,
Revision:V1.4.0,
Revision:V1.4.0,
Revision:V1.4.0,
Revision:V1.4.0,
Revision:V1.4.0,
Revision:V1.4.0,
Revision:V1.4.0,
Revision:V1.4.0,
Revision:V1.4.0,
Revision:V1.4.0,
Revision:V1.4.0,
Revision:V1.4.0,
Revision:V1.4.0,
Revision:V1.4.0,
Revision:V1.4.0,
Revision:V1.4.0,
Revision:V1.4.0,
Revision:V1.4.0,
Revision:V1.4.0,
Revision:V1.4.0,
Revision:V1.4.0,
Revision:V1.4.0,
Revision:V1.4.0,
Revision:V1.4.0,
Revision:V1.4.0,
Revision:V1.4.0,
Revision:V1.4.0,
Revision:V1.4.0,
Revision:V1.4.0,
Revision:V1.4.0,
Revision:V1.4.0,
Revision:V1.4.0,
Revision:V1.4.0,
Revision:V1.4.0,
Revision:V1.4.0,
Revision:V1.4.0,
Revision:V1.4.0,
Revision:V1.4.0,
Revision:V1.4.0,
Revision:V1.4.0,
Revision:V1.4.0,
Revision:V1.4.0,
Revision:V1.4.0,
Revision:V1.4.0,
Revision:V1.4.0,
Revision:V1.4.0,
Revision:V1.4.0,
Revision:V1.4.0,
Revision:V1.4.0,
Revision:V1.4.0,
Revision:V1.4.0,
Revision:V1.4.0,
Revision:V1.4.0,
Revision:V1.4.0,
Revision:V1.4.0,
Revision:V1.4.0,
Revision:V1.4.0,
Revision:V1.4.0,
Revision:V1.4.0,
Revision:V1.4.0,
Revision:V1.4.0,
Revision:V1.4.0,
Revision:V1.4.0,
Revision:V1.4.0,
Revision:V1.4.0,
Revision:V1.4.0,
Revision:V1.4.0,
Revision:V1.4.0,
Revision:V1.4.0,
Revision:V1.4.0,
Revision:V1.4.0,
Revision:V1.4.0,
Revision:V1.4.0,
Revision:V1.4.0,
Revision:V1.4.0,
Revision:V1.4.0,
Revision:V1.4.0,
Revision:V1.4.0,
Revision:V1.4.0,
Revision:V1.4.0,
Revision:V1.4.0,
Revision:V1.4.0,
Revision:V1.4.0,
Revision:V1.4.0,
Revision:V1.4.0,
Revision:V1.4.0,
Revision:V1.4.0,
Revision:V1.4.0,
Revision:V1.4.0,
Revision:V1.4.0,
Revision:V1.4.0,
Revision:V1.4.0,
Revision:V1.4.0,
Revision:V1.4.0,
Revision:V1.4.0,
Revision:V1.4.0,
Revision:V1.4.0,
Revision:V1.4.0,
Revision:V1.4.0,
Revision:V1.4.0,
Revision:V1.4.0,
Revision:V1.4.0,
Revision:V1.4.0,
Revision:V1.4.0,
Revision:V1.4.0,
Revision:V1.4.0,
Revision:V1.4.0,
Revision:V1.4.0,
Revision:V1.4.0,
Revision:V1.4.0,
Revision:V1.4.0,
Revision:V1.4.0,
Revision:V1.4.0,
Revision:V1.4.0,
Revision:V1.4.0,
Revision:V1.4.0,
Revision:V1.4.0,
Revision:V1.4.0,
Revision:V1.4.0,
Revision:V1.4.0,
Revision:V1.4.0,
Revision:V1.4.0,
Revision:V1.4.0,
Revision:V1.4.0,
Revision:V1.4.0,
Revision:V1.4.0,
Revision:V1.4.0,
Revision:V1.4.0,
Revision:V1.4.0,
Revision:V1.4.0,
Revision:V1.4.0,
Revision:V1.4.0,
Revision:V1.4.0,
Revision:V1.4.0,
Revision:V1.4.0,
Revision:V1.4.0,
Revision:V1.4.0,
Revision:V1.4.0,
Revision:V1.4.0,
Revision:V1.4.0,
Revision:V1.4.0,
Revision:V1.4.0,
Revision:V1.4.0,
Revision:V1.4.0,
Revision:V1.4.0,
Revision:V1.4.0,
Revision:V1.4.0,
Revision:V1.4.0,
Revision:V1.4.0,
Revision:V1.4.0,
Revision:V1.4.0,
Revision:V1.4.0,
Revision:V1.4.0,
Revision:V1.4.0,
Revision:V1.4.0,
Revision:V1.4.0,
Revision:V1.4.0,
Revision:V1.4.0,
Revision:V1.4.0,
Revision:V1.4.0,
Revision:V1.4.0,
Revision:V1.4.0,
Revision:V1.4.0,
Revision:V1.4.0,
Revision:V1.4.0,
Revision:V1.4.0,
Revision:V1.4.0,
Revision:V1.4.0,
Revision:V1.4.0,
Revision:V1.4.0,
Revision:V1.4.0,
Revision:V1.4.0,
Revision:V1.4.0,
Revision:V1.4.0,
Revision:V1.4.0,
Revision:V1.4.0,
Revision:V1.4.0,
Revision:V1.4.0,
Revision:V1.4.0,
Revision:V1.4.0,
Revision:V1.4.0,
Revision:V1.4.0,
Revision:V1.4.0,
Revision:V1.4.0,
Revision:V1.4.0,
Revision:V1.4.0,
Revision:V1.4.0,
Revision:V1.4.0,
Revision:V1.4.0,
Revision:V1.4.0,
Revision:V1.4.0,
Revision:V1.4.0,
Revision:V1.4.0,
Revision:V1.4.0,
Revision:V1.4.0,
Revision:V1.4.0,
Revision:V1.4.0,
Revision:V1.4.0,
Revision:V1.4.0,
Revision:V1.4.0,
Revision:V1.4.0,
Revision:V1.4.0,
Revision:V1.4.0,
Revision:V1.4.0,
Revision:V1.4.0,
Revision:V1.4.0,
Revision:V1.4.0,
Revision:V1.4.0,
Revision:V1.4.0,
Revision:V1.4.0,
Revision:V1.4.0,
Revision:V1.4.0,
Revision:V1.4.0,
Revision:V1.4.0,
Revision:V1.4.0,
Revision:V1.4.0,
Revision:V1.4.0,
Revision:V1.4.0,
Revision:V1.4.0,
Revision:V1.4.0,
Revision:V1.4.0,
Revision:V1.4.0,
Revision:V1.4.0,
Revision:V1.4.0,
Revision:V1.4.0,
Revision:V1.4.0,
Revision:V1.4.0,
Revision:V1.4.0,
Revision:V1.4.0,
Revision:V1.4.0,
Revision:V1.4.0,
Revision:V1.4.0,
Revision:V1.4.0,
Revision:V1.4.0,
Revision:V1.4.0,
Revision:V1.4.0,
Revision:V1.4.0,
Revision:V1.4.0,
Revision:V1.4.0,
Revision:V1.4.0,
Revision:V1.4.0,
Revision:V1.4.0,
Revision:V1.4.0,
Revision:V1.4.0,
Revision:V1.4.0,
Revision:V1.4.0,
Revision:V1.4.0,
Revision:V1.4.0,
Revision:V1.4.0,
Revision:V1.4.0,
Revision:V1.4.0,
Revision:V1.4.0,
Revision:V1.4.0,
Revision:V1.4.0,
Revision:V1.4.0,
Revision:V1.4.0,
Revision:V1.4.0,
Revision:V1.4.0,
Revision:V1.4.0,
Revision:V1.4.0,
Revision:V1.4.0,
Revision:V1.4.0,
Revision:V1.4.0,
Revision:V1.4.0,
Revision:V1.4.0,
Revision:V1.4.0,
Revision:V1.4.0,
Revision:V1.4.0,
Revision:V1.4.0,
Revision:V1.4.0,
Revision:V1.4.0,
Revision:V1.4.0,
Revision:V1.4.0,
Revision:V1.4.0,
Revision:V1.4.0,
Revision:V1.4.0,
Revision:V1.4.0,
Revision:V1.4.0,
Revision:V1.4.0,
Revision:V1.4.0,
Revision:V1.4.0,
Revision:V1.4.0,
Revision:V1.4.0,
Revision:V1.4.0,
Revision:V1.4.0,
Revision:V1.4.0,
Revision:V1.4.0,
Revision:V1.4.0,
Revision:V1.4.0,
Revision:V1.4.0,
Revision:V1.4.0,
Revision:V1.4.0,
Revision:V1.4.0,
Revision:V1.4.0,
Revision:V1.4.0,
Revision:V1.4.0,
Revision:V1.4.0,
Revision:V1.4.0,
Revision:V1.4.0,
Revision:V1.4.0,
Revision:V1.4.0,
Revision:V1.5.0,
Revision:V1.5.0,
Revision:V1.5.0,
Revision:V1.5.0,
Revision:V1.5.0,
Revision:V1.5.0,
Revision:V1.5.0,
Revision:V1.5.0,
Revision:V1.5.0,
Revision:V1.5.0,
Revision:V1.5.0,
Revision:V1.5.0,
Revision:V1.5.0,
Revision:V1.5.0,
Revision:V1.5.0,
Revision:V1.5.0,
Revision:V1.5.0,
Revision:V1.5.0,
Revision:V1.5.0,
Revision:V1.5.0,
Revision:V1.5.0,
Revision:V1.5.0,
Revision:V1.5.0,
Revision:V1.5.0,
Revision:V1.5.0,
Revision:V1.5.0,
Revision:V1.5.0,
Revision:V1.5.0,
Revision:V1.5.0,
Revision:V1.5.0,
Revision:V1.5.0,
Revision:V1.5.0,
Revision:V1.5.0,
Revision:V1.5.0,
Revision:V1.5.0,
Revision:V1.5.0,
Revision:V1.5.0,
Revision:V1.5.0,
Revision:V1.5.0,
Revision:V1.5.0,
Revision:V1.5.0,
Revision:V1.5.0,
Revision:V1.5.0,
Revision:V1.5.0,
Revision:V1.5.0,
Revision:V1.5.0,
Revision:V1.5.0,
Revision:V1.5.0,
Revision:V1.5.0,
Revision:V1.5.0,
Revision:V1.5.0,
Revision:V1.5.0,
Revision:V1.5.0,
Revision:V1.5.1,
Revision:V1.6.0,
Revision:V1.6.0,
Revision:V1.6.0,
Revision:V1.6.0,
Revision:V1.6.0,
Revision:V1.6.0,
Revision:V1.6.0,
Revision:V1.6.0,
Revision:V1.6.0,
Revision:V1.6.0,
Revision:V1.6.0,
Revision:V1.6.0,
Revision:V1.6.0,
Revision:V1.6.0,
Revision:V1.6.0,
Revision:V1.6.0,
Revision:V1.6.0,
Revision:V1.6.0,
Revision:V1.6.0,
Revision:V1.6.0,
Revision:V1.6.0,
Revision:V1.6.0,
Revision:V1.6.0,
Revision:V1.6.0,
Revision:V1.6.0,
Revision:V1.6.0,
Revision:V1.6.0,
Revision:V1.6.0,
Revision:V1.6.0,
Revision:V1.6.0,
Revision:V1.6.0,
Revision:V1.6.0,
Revision:V1.6.0,
Revision:V1.6.0,
Revision:V1.6.0,
Revision:V1.6.0,
Revision:V1.6.0,
Revision:V1.6.0,
Revision:V1.6.0,
Revision:V1.6.0,
Revision:V1.6.0,
Revision:V1.6.0,
Revision:V1.6.0,
Revision:V1.6.0,
Revision:V1.6.0,
Revision:V1.6.0,
Revision:V1.6.0,
Revision:V1.6.0,
Revision:V1.6.0,
Revision:V1.6.0,
Revision:V1.6.0,
Revision:V1.6.0,
Revision:V1.6.0,
Revision:V1.6.0,
Revision:V1.6.0,
Revision:V1.6.0,
Revision:V1.6.0,
Revision:V1.6.0,
Revision:V1.6.0,
Revision:V1.6.0,
Revision:V1.6.0,
Revision:V1.6.0,
Revision:V1.6.0,
Revision:V1.6.0,
Revision:V1.6.0,
Revision:V1.6.0,
Revision:V1.6.0,
Revision:V1.6.0,
Revision:V1.6.0,
Revision:V1.6.0,
Revision:V1.6.0,
Revision:V1.6.0,
Revision:V1.6.0,
Revision:V1.6.0,
Revision:V1.6.0,
Revision:V1.6.0,
Revision:V1.6.0,
Revision:V1.6.0,
Revision:V1.6.0,
Revision:V1.6.0,
Revision:V1.6.0,
Revision:V1.6.0,
Revision:V1.6.0,
Revision:V1.6.0,
Revision:V1.6.0,
Revision:V1.6.0,
Revision:V1.6.0,
Revision:V1.6.0,
Revision:V1.6.0,
Revision:V1.6.0,
Revision:V1.6.0,
Revision:V1.6.0,
Revision:V1.6.0,
Revision:V1.6.0,
Revision:V1.6.0,
Revision:V1.6.0,
Revision:V1.6.0,
Revision:V1.6.0,
Revision:V1.6.0,
Revision:V1.6.0,
Revision:V1.6.0,
Revision:V1.6.0,
Revision:V1.6.0,
Revision:V1.6.0,
Revision:V1.6.0,
Revision:V1.6.0,
Revision:V1.6.0,
Revision:V1.6.0,
Revision:V1.6.0,
Revision:V1.6.0,
Revision:V1.6.0,
Revision:V1.6.0,
Revision:V1.6.0,
Revision:V1.6.0,
Revision:V1.6.0,
Revision:V1.6.0,
Revision:V1.6.0,
Revision:V1.6.0,
Revision:V1.6.0,
Revision:V1.6.0,
Revision:V1.6.0,
Revision:V1.6.0,
Revision:V1.6.0,
Revision:V1.6.0,
Revision:V1.6.0,
Revision:V1.6.0,
Revision:V1.6.0,
Revision:V1.6.0,
Revision:V1.6.0,
Revision:V1.6.0,
Revision:V1.6.0,
Revision:V1.6.0,
Revision:V1.6.0,
Revision:V1.6.0,
Revision:V1.6.0,
Revision:V1.6.0,
Revision:V1.6.0,
Revision:V1.6.0,
Revision:V1.6.0,
Revision:V1.6.0,
Revision:V1.6.0,
Revision:V1.6.0,
Revision:V1.6.0,
Revision:V1.6.0,
Revision:V1.6.0,
Revision:V1.6.0,
Revision:V1.6.0,
Revision:V1.6.0,
Revision:V1.6.0,
Revision:V1.6.0,
Revision:V1.6.0,
Revision:V1.6.0,
Revision:V1.6.0,
Revision:V1.6.0,
Revision:V1.6.0,
Revision:V1.6.0,
Revision:V1.6.0,
Revision:V1.6.0,
Revision:V1.6.0,
Revision:V1.6.0,
Revision:V1.6.0,
Revision:V1.6.0,
Revision:V1.6.0,
Revision:V1.6.0,
Revision:V1.6.0,
Revision:V1.6.0,
Revision:V1.6.0,
Revision:V1.6.0,
Revision:V1.6.0,
Revision:V1.6.0,
Revision:V1.6.0,
Revision:V1.6.0,
Revision:V1.6.0,
Revision:V1.6.0,
Revision:V1.6.0,
Revision:V1.6.0,
Revision:V1.6.0,
Revision:V1.6.0,
Revision:V1.6.0,
Revision:V1.6.0,
Revision:V1.6.0,
Revision:V1.6.0,
Revision:V1.6.0,
Revision:V1.6.0,
Revision:V1.6.0,
Revision:V1.6.0,
Revision:V1.6.0,
Revision:V1.6.0,
Revision:V1.6.0,
Revision:V1.6.0,
Revision:V1.6.0,
Revision:V1.6.0,
Revision:V1.6.0,
Revision:V1.6.0,
Revision:V1.6.0,
Revision:V1.6.0,
Revision:V1.6.0,
Revision:V1.6.0,
Revision:V1.6.0,
Revision:V1.6.0,
Revision:V1.6.0,
Revision:V1.6.0,
Revision:V1.6.0,
Revision:V1.6.0,
Revision:V1.6.0,
Revision:V1.6.0,
Revision:V1.6.0,
Revision:V1.6.0,
Revision:V1.6.0,
Revision:V1.6.0,
Revision:V1.6.0,
Revision:V1.6.0,
Revision:V1.6.0,
Revision:V1.6.0,
Revision:V1.6.0,
Revision:V1.6.0,
Revision:V1.6.0,
Revision:V1.6.0,
Revision:V1.6.0,
Revision:V1.6.0,
Revision:V1.6.0,
Revision:V1.6.0,
Revision:V1.6.0,
Revision:V1.6.0,
Revision:V1.6.0,
Revision:V1.6.0,
Revision:V1.6.0,
Revision:V1.6.0,
Revision:V1.6.0,
Revision:V1.6.0,
Revision:V1.6.0,
Revision:V1.6.0,
Revision:V1.6.0,
Revision:V1.6.0,
Revision:V1.6.0,
Revision:V1.6.0,
Revision:V1.6.0,
Revision:V1.6.0,
Revision:V1.6.0,
Revision:V1.6.0,
Revision:V1.6.0,
Revision:V1.6.0,
Revision:V1.6.0,
Revision:V1.6.0,
Revision:V1.6.0,
Revision:V1.6.0,
Revision:V1.6.0,
Revision:V1.6.0,
Revision:V1.6.0,
Revision:V1.6.0,
Revision:V1.6.0,
Revision:V1.6.0,
Revision:V1.6.0,
Revision:V1.6.0,
Revision:V1.6.0,
Revision:V1.6.0,
Revision:V1.6.0,
Revision:V1.6.0,
Revision:V1.6.0,
Revision:V1.6.0,
Revision:V1.6.0,
Revision:V1.6.0,
Revision:V1.6.0,
Revision:V1.6.0,
Revision:V1.6.0,
Revision:V1.6.0,
Revision:V1.6.0,
Revision:V1.6.0,
Revision:V1.6.0,
Revision:V1.6.0,
Revision:V1.6.0,
Revision:V1.6.0,
Revision:V1.6.0,
Revision:V1.6.0,
Revision:V1.6.0,
Revision:V1.6.0,
Revision:V1.6.0,
Revision:V1.6.0,
Revision:V1.6.0,
Revision:V1.6.0,
Revision:V1.6.0,
Revision:V1.6.0,
Revision:V1.6.0,
Revision:V1.6.0,
Revision:V1.6.0,
Revision:V1.6.0,
Revision:V1.6.0,
Revision:V1.6.0,
Revision:V1.6.0,
Revision:V1.6.0,
Revision:V1.6.0,
Revision:V1.6.0,
Revision:V1.6.0,
Revision:V1.6.0,
Revision:V1.6.0,
Revision:V1.6.0,
Revision:V1.6.0,
Revision:V1.6.0,
Revision:V1.6.0,
Revision:V1.6.0,
Revision:V1.6.0,
Revision:V1.6.0,
Revision:V1.6.0,
Revision:V1.6.0,
Revision:V1.6.0,
Revision:V1.6.0,
Revision:V1.6.0,
Revision:V1.6.0,
Revision:V1.6.0,
Revision:V1.6.0,
Revision:V1.6.0,
Revision:V1.6.0,
Revision:V1.6.0,
Revision:V1.6.0,
Revision:V1.6.0,
Revision:V1.6.0,
Revision:V1.6.0,
Revision:V1.6.0,
Revision:V1.6.0,
Revision:V1.6.0,
Revision:V1.6.0,
Revision:V1.6.0,
Revision:V1.6.0,
Revision:V1.6.0,
Revision:V1.6.0,
Revision:V1.6.0,
Revision:V1.6.0,
Revision:V1.6.0,
Revision:V1.6.0,
Revision:V1.6.0,
Revision:V1.6.0,
Revision:V1.6.0,
Revision:V1.6.0,
Revision:V1.6.0,
Revision:V1.6.0,
Revision:V1.6.0,
Revision:V1.6.0,
Revision:V1.6.0,
Revision:V1.6.0,
Revision:V1.6.0,
Revision:V1.6.0,
Revision:V1.6.0,
Revision:V1.6.0,
Revision:V1.6.0,
Revision:V1.6.0,
Revision:V1.6.0,
Revision:V1.6.0,
Revision:V1.6.0,
Revision:V1.6.0,
Revision:V1.6.0,
Revision:V1.6.0,
Revision:V1.6.0,
Revision:V1.6.0,
Revision:V1.6.0,
Revision:V1.6.0,
Revision:V1.6.0,
Revision:V1.6.0,
Revision:V1.6.0,
Revision:V1.6.0,
Revision:V1.6.0,
Revision:V1.6.0,
Revision:V1.6.0,
Revision:V1.6.0,
Revision:V1.6.0,
Revision:V1.6.0,
Revision:V1.6.0,
Revision:V1.6.0,
Revision:V1.6.0,
Revision:V1.6.0,
Revision:V1.6.0,
Revision:V1.6.0,
Revision:V1.6.0,
Revision:V1.6.0,
Revision:V1.6.0,
Revision:V1.6.0,
Revision:V1.6.0,
Revision:V1.6.0,
Revision:V1.6.0,
Revision:V1.6.0,
Revision:V1.6.0,
Revision:V1.6.0,
Revision:V1.6.0,
Revision:V1.6.0,
Revision:V1.6.0,
Revision:V1.6.0,
Revision:V1.6.0,
Revision:V1.6.0,
Revision:V1.6.0,
Revision:V1.6.0,
Revision:V1.6.0,
Revision:V1.6.0,
Revision:V1.6.0,
Revision:V1.6.0,
Revision:V1.6.0,
Revision:V1.6.0,
Revision:V1.6.0,
Revision:V1.6.0,
Revision:V1.6.0,
Revision:V1.6.0,
Revision:V1.6.0,
Revision:V1.6.0,
Revision:V1.6.0,
Revision:V1.6.0,
Revision:V1.6.0,
Revision:V1.6.0,
Revision:V1.6.0,
Revision:V1.6.0,
Revision:V1.6.0,
Revision:V1.6.0,
Revision:V1.6.0,
Revision:V1.6.0,
Revision:V1.6.0,
Revision:V1.6.0,
Revision:V1.6.0,
Revision:V1.6.0,
Revision:V1.6.0,
Revision:V1.6.0,
Revision:V1.6.0,
Revision:V1.6.0,
Revision:V1.6.0,
Revision:V1.6.0,
Revision:V1.6.0,
Revision:V1.6.0,
Revision:V1.6.0,
Revision:V1.6.0,
Revision:V1.6.0,
Revision:V1.6.0,
Revision:V1.6.0,
Revision:V1.6.0,
Revision:V1.6.0,
Revision:V1.6.0,
Revision:V1.6.0,
Revision:V1.6.0,
Revision:V1.6.0,
Revision:V1.6.0,
Revision:V1.6.0,
Revision:V1.6.0,
Revision:V1.6.0,
Revision:V1.6.0,
Revision:V1.6.0,
Revision:V1.6.0,
Revision:V1.6.0,
Revision:V1.6.0,
Revision:V1.6.0,
Revision:V1.6.0,
Revision:V1.6.0,
Revision:V1.6.0,
Revision:V1.6.0,
Revision:V1.6.0,
Revision:V1.6.0,
Revision:V1.6.0,
Revision:V1.6.0,
Revision:V1.6.0,
Revision:V1.6.0,
Revision:V1.6.0,
Revision:V1.6.0,
Revision:V1.6.0,
Revision:V1.6.0,
Revision:V1.6.0,
Revision:V1.6.0,
Revision:V1.6.0,
Revision:V1.6.0,
Revision:V1.6.0,
Revision:V1.6.0,
Revision:V1.6.0,
Revision:V1.6.0,
Revision:V1.6.0,
Revision:V1.6.0,
Revision:V1.6.0,
Revision:V1.6.0,
Revision:V1.6.0,
Revision:V1.6.0,
Revision:V1.6.0,
Revision:V1.6.0,
Revision:V1.6.0,
Revision:V1.6.0,
Revision:V1.6.0,
Revision:V1.6.0,
Revision:V1.6.0,
Revision:V1.6.0,
Revision:V1.6.0,
Revision:V1.6.0,
Revision:V1.6.0,
Revision:V1.6.0,
Revision:V1.6.0,
Revision:V1.6.0,
Revision:V1.6.0,
Revision:V1.6.0,
Revision:V1.6.0,
Revision:V1.6.0,
Revision:V1.6.0,
Revision:V1.6.0,
Revision:V1.6.0,
Revision:V1.6.0,
Revision:V1.6.0,
Revision:V1.6.0,
Revision:V1.6.0,
Revision:V1.6.0,
Revision:V1.6.0,
Revision:V1.6.0,
Revision:V1.6.0,
Revision:V1.6.0,
Revision:V1.6.0,
Revision:V1.6.0,
Revision:V1.6.0,
Revision:V1.6.0,
Revision:V1.6.0,
Revision:V1.6.0,
Revision:V1.6.0,
Revision:V1.6.0,
Revision:V1.6.0,
Revision:V1.6.0,
Revision:V1.6.0,
Revision:V1.6.0,
Revision:V1.6.0,
Revision:V1.6.0,
Revision:V1.6.0,
Revision:V1.6.0,
Revision:V1.6.0,
Revision:V1.6.0,
Revision:V1.6.0,
Revision:V1.6.0,
Revision:V1.6.0,
Revision:V1.6.0,
Revision:V1.6.0,
Revision:V1.6.0,
Revision:V1.6.0,
Revision:V1.6.0,
Revision:V1.6.0,
Revision:V1.6.0,
Revision:V1.6.0,
Revision:V1.6.0,
Revision:V1.6.0,
Revision:V1.6.0,
Revision:V1.6.0,
Revision:V1.6.0,
Revision:V1.6.0,
Revision:V1.6.0,
Revision:V1.6.0,
Revision:V1.6.0,
Revision:V1.6.0,
Revision:V1.6.0,
Revision:V1.6.0,
Revision:V1.6.0,
Revision:V1.6.0,
Revision:V1.6.0,
Revision:V1.6.0,
Revision:V1.6.0,
Revision:V1.6.0,
Revision:V1.6.0,
Revision:V1.6.0,
Revision:V1.6.0,
Revision:V1.6.0,
Revision:V1.6.0,
Revision:V1.6.0,
Revision:V1.6.0,
Revision:V1.6.0,
Revision:V1.6.0,
Revision:V1.6.0,
Revision:V1.6.0,
Revision:V1.6.0,
Revision:V1.6.0,
Revision:V1.6.0,
Revision:V1.6.0,
Revision:V1.6.0,
Revision:V1.6.0,
Revision:V1.6.0,
Revision:V1.6.0,
Revision:V1.6.0,
Revision:V1.6.0,
Revision:V1.6.0,
Revision:V1.6.0,
Revision:V1.6.0,
Revision:V1.6.0,
Revision:V1.6.0,
Revision:V1.6.0,
Revision:V1.6.0,
Revision:V1.6.0,
Revision:V1.6.0,
Revision:V1.6.0,
Revision:V1.6.0,
Revision:V1.6.0,
Revision:V1.6.0,
Revision:V1.6.0,
Revision:V1.6.0,
Revision:V1.6.0,
Revision:V1.6.0,
Revision:V1.6.0,
Revision:V1.6.0,
Revision:V1.6.0,
Revision:V1.6.0,
Revision:V1.6.0,
Revision:V1.6.0,
Revision:V1.6.0,
Revision:V1.6.0,
Revision:V1.6.0,
Revision:V1.6.0,
Revision:V1.6.0,
Revision:V1.6.0,
Revision:V1.6.0,
Revision:V1.6.0,
Revision:V1.6.0,
Revision:V1.6.0,
Revision:V1.6.0,
Revision:V1.6.0,
Revision:V1.6.0,
Revision:V1.6.0,
Revision:V1.6.0,
Revision:V1.6.0,
Revision:V1.6.0,
Revision:V1.6.0,
Revision:V1.6.0,
Revision:V1.6.0,
Revision:V1.6.0,
Revision:V1.6.0,
Revision:V1.6.0,
Revision:V1.6.0,
Revision:V1.6.0,
Revision:V1.6.0,
Revision:V1.6.0,
Revision:V1.6.0,
Revision:V1.6.0,
Revision:V1.6.0,
Revision:V1.6.0,
Revision:V1.6.0,
Revision:V1.6.0,
Revision:V1.6.0,
Revision:V1.6.0,
Revision:V1.6.0,
Revision:V1.6.0,
Revision:V1.6.0,
Revision:V1.6.0,
Revision:V1.6.0,
Revision:V1.6.0,
Revision:V1.6.0,
Revision:V1.6.0,
Revision:V1.6.0,
Revision:V1.6.0,
Revision:V1.6.0,
Revision:V1.6.0,
Revision:V1.6.0,
Revision:V1.6.0,
Revision:V1.6.0,
Revision:V1.6.0,
Revision:V1.6.0,
Revision:V1.6.0,
Revision:V1.6.0,
Revision:V1.6.0,
Revision:V1.6.0,
Revision:V1.6.0,
Revision:V1.6.0,
Revision:V1.6.0,
Revision:V1.6.0,
Revision:V1.6.0,
Revision:V1.6.0,
Revision:V1.6.0,
Revision:V1.6.0,
Revision:V1.6.0,
Revision:V1.6.0,
Revision:V1.6.0,
Revision:V1.6.0,
Revision:V1.6.0,
Revision:V1.6.0,
Revision:V1.6.0,
Revision:V1.6.0,
Revision:V1.6.0,
Revision:V1.6.0,
Revision:V1.6.0,
Revision:V1.6.0,
Revision:V1.6.0,
Revision:V1.6.0,
Revision:V1.6.0,
Revision:V1.6.0,
Revision:V1.6.0,
Revision:V1.6.0,
Revision:V1.6.0,
Revision:V1.6.0,
Revision:V1.6.0,
Revision:V1.6.0,
Revision:V1.6.0,
Revision:V1.6.0,
Revision:V1.6.0,
Revision:V1.6.0,
Revision:V1.6.0,
Revision:V1.6.0,
Revision:V1.6.0,
Revision:V1.6.0,
Revision:V1.6.0,
Revision:V1.6.0,
Revision:V1.6.0,
Revision:V1.6.0,
Revision:V1.6.0,
Revision:V1.6.0,
Revision:V1.6.0,
Revision:V1.6.0,
Revision:V1.6.0,
Revision:V1.6.0,
Revision:V1.6.0,
Revision:V1.6.0,
Revision:V1.6.0,
Revision:V1.6.0,
Revision:V1.6.0,
Revision:V1.6.0,
Revision:V1.6.0,
Revision:V1.6.0,
Revision:V1.6.0,
Revision:V1.6.0,
Revision:V1.6.0,
Revision:V1.6.0,
Revision:V1.6.0,
Revision:V1.6.0,
Revision:V1.6.0,
Revision:V1.6.0,
Revision:V1.6.0,
Revision:V1.6.0,
Revision:V1.6.0,
Revision:V1.6.0,
Revision:V1.6.0,
Revision:V1.6.0,
Revision:V1.6.0,
Revision:V1.6.0,
Revision:V1.6.0,
Revision:V1.6.0,
Revision:V1.6.0,
Revision:V1.6.0,
Revision:V1.6.0,
Revision:V1.6.0,
Revision:V1.6.0,
Revision:V1.6.0,
Revision:V1.6.0,
Revision:V1.6.0,
Revision:V1.6.0,
Revision:V1.6.0,
Revision:V1.6.0,
Revision:V1.6.0,
Revision:V1.6.0,
Revision:V1.6.0,
Revision:V1.6.0,
Revision:V1.6.0,
Revision:V1.6.0,
Revision:V1.6.0,
Revision:V1.6.0,
Revision:V1.6.0,
Revision:V1.6.0,
Revision:V1.6.0,
Revision:V1.6.0,
Revision:V1.6.0,
Revision:V1.6.0,
Revision:V1.6.0,
Revision:V1.6.0,
Revision:V1.6.0,
Revision:V1.6.0,
Revision:V1.6.0,
Revision:V1.6.0,
Revision:V1.6.0,
Revision:V1.6.0,
Revision:V1.6.0,
Revision:V1.6.0,
Revision:V1.6.0,
Revision:V1.6.0,
Revision:V1.6.0,
Revision:V1.6.0,
Revision:V1.6.0,
Revision:V1.6.0,
Revision:V1.6.0,
Revision:V1.6.0,
Revision:V1.6.0,
Revision:V1.6.0,
Revision:V1.6.0,
Revision:V1.6.0,
Revision:V1.6.0,
Revision:V1.6.0,
Revision:V1.6.0,
Revision:V1.6.0,
Revision:V1.6.0,
Revision:V1.6.0,
Revision:V1.6.0,
Revision:V1.6.0,
Revision:V1.6.0,
Revision:V1.6.0,
Revision:V1.6.0,
Revision:V1.6.0,
Revision:V1.6.0,
Revision:V1.6.0,
Revision:V1.6.0,
Revision:V1.6.0,
Revision:V1.6.0,
Revision:V1.6.0,
Revision:V1.6.0,
Revision:V1.6.0,
Revision:V1.6.0,
Revision:V1.6.0,
Revision:V1.6.0,
Revision:V1.6.0,
Revision:V1.6.0,
Revision:V1.6.0,
Revision:V1.6.0,
Revision:V1.6.0,
Revision:V1.6.0,
Revision:V1.6.0,
Revision:V1.6.0,
Revision:V1.6.0,
Revision:V1.6.0,
Revision:V1.6.0,
Revision:V1.6.0,
Revision:V1.6.0,
Revision:V1.6.0,
Revision:V1.6.0,
Revision:V1.6.0,
Revision:V1.6.0,
Revision:V1.6.0,
Revision:V1.6.0,
Revision:V1.6.0,
Revision:V1.6.0,
Revision:V1.6.0,
Revision:V1.6.0,
Revision:V1.6.0,
Revision:V1.6.0,
Revision:V1.6.0,
Revision:V1.6.0,
Revision:V1.6.0,
Revision:V1.6.0,
Revision:V1.6.0,
Revision:V1.6.0,
Revision:V1.6.0,
Revision:V1.6.0,
Revision:V1.6.0,
Revision:V1.6.0,
Revision:V1.6.0,
Revision:V1.6.0,
Revision:V1.6.0,
Revision:V1.6.0,
Revision:V1.6.0,
Revision:V1.6.0,
Revision:V1.6.0,
Revision:V1.6.0,
Revision:V1.6.0,
Revision:V1.6.0,
Revision:V1.6.0,
Revision:V1.6.0,
Revision:V1.6.0,
Revision:V1.6.0,
Revision:V1.6.0,
Revision:V1.6.0,
Revision:V1.6.0,
Revision:V1.6.0,
Revision:V1.6.0,
Revision:V1.6.0,
Revision:V1.6.0,
Revision:V1.6.0,
Revision:V1.6.0,
Revision:V1.6.0,
Revision:V1.6.0,
Revision:V1.6.0,
Revision:V1.6.0,
Revision:V1.6.0,
Revision:V1.6.0,
Revision:V1.6.0,
Revision:V1.6.0,
Revision:V1.6.0,
Revision:V1.6.0,
Revision:V1.6.0,
Revision:V1.6.0,
Revision:V1.6.0,
Revision:V1.6.0,
Revision:V1.6.0,
Revision:V1.6.0,
Revision:V1.6.0,
Revision:V1.6.0,
Revision:V1.6.0,
Revision:V1.6.0,
Revision:V1.6.0,
Revision:V1.6.0,
Revision:V1.6.0,
Revision:V1.6.0,
Revision:V1.6.0,
Revision:V1.6.0,
Revision:V1.6.0,
Revision:V1.6.0,
Revision:V1.6.0,
Revision:V1.6.0,
Revision:V1.6.0,
Revision:V1.6.0,
Revision:V1.6.0,
Revision:V1.6.0,
Revision:V1.6.0,
Revision:V1.6.0,
Revision:V1.6.0,
Revision:V1.6.0,
Revision:V1.6.0,
Revision:V1.6.0,
Revision:V1.6.0,
Revision:V1.6.0,
Revision:V1.6.0,
Revision:V1.6.0,
Revision:V1.6.0,
Revision:V1.6.0,
Revision:V1.6.0,
Revision:V1.6.0,
Revision:V1.6.0,
Revision:V1.6.0,
Revision:V1.6.0,
Revision:V1.6.0,
Revision:V1.6.0,
Revision:V1.6.0,
Revision:V1.6.0,
Revision:V1.6.0,
Revision:V1.6.0,
Revision:V1.6.0,
Revision:V1.6.0,
Revision:V1.6.0,
Revision:V1.6.0,
Revision:V1.6.0,
Revision:V1.6.0,
Revision:V1.6.0,
Revision:V1.6.0,
Revision:V1.6.0,
Revision:V1.6.0,
Revision:V1.6.0,
Revision:V1.6.0,
Revision:V1.6.0,
Revision:V1.6.0,
Revision:V1.6.0,
Revision:V1.6.0,
Revision:V1.6.0,
Revision:V1.6.0,
Revision:V1.6.0,
Revision:V1.6.0,
Revision:V1.6.0,
Revision:V1.6.0,
Revision:V1.6.0,
Revision:V1.6.0,
Revision:V1.6.0,
Revision:V1.6.0,
Revision:V1.6.0,
Revision:V1.6.0,
Revision:V1.6.0,
Revision:V1.6.0,
Revision:V1.6.0,
Revision:V1.6.0,
Revision:V1.6.0,
Revision:V1.6.0,
Revision:V1.6.0,
Revision:V1.6.0,
Revision:V1.6.0,
Revision:V1.6.0,
Revision:V1.6.0,
Revision:V1.6.0,
Revision:V1.6.0,
Revision:V1.6.0,
Revision:V1.6.0,
Revision:V1.6.0,
Revision:V1.6.0,
Revision:V1.6.0,
Revision:V1.6.0,
Revision:V1.6.0,
Revision:V1.6.0,
Revision:V1.6.0,
Revision:V1.6.0,
Revision:V1.6.0,
Revision:V1.6.0,
Revision:V1.6.0,
Revision:V1.6.0,
Revision:V1.6.0,
Revision:V1.6.0,
Revision:V1.6.0,
Revision:V1.6.0,
Revision:V1.6.0,
Revision:V1.6.0,
Revision:V1.6.0,
Revision:V1.6.0,
Revision:V1.6.0,
Revision:V1.6.0,
Revision:V1.6.0,
Revision:V1.6.0,
Revision:V1.6.0,
Revision:V1.6.0,
Revision:V1.6.0,
Revision:V1.6.0,
Revision:V1.6.0,
Revision:V1.6.0,
Revision:V1.6.0,
Revision:V1.6.0,
Revision:V1.6.0,
Revision:V1.6.0,
Revision:V1.6.0,
Revision:V1.6.0,
Revision:V1.6.0,
Revision:V1.6.0,
Revision:V1.6.0,
Revision:V1.6.0,
Revision:V1.6.0,
Revision:V1.6.0,
Revision:V1.6.0,
Revision:V1.6.0,
Revision:V1.6.0,
Revision:V1.6.0,
Revision:V1.6.0,
Revision:V1.6.0,
Revision:V1.6.0,
Revision:V1.6.0,
Revision:V1.6.0,
Revision:V1.6.0,
Revision:V1.6.0,
Revision:V1.6.0,
Revision:V1.6.0,
Revision:V1.6.0,
Revision:V1.6.0,
Revision:V1.6.0,
Revision:V1.6.0,
Revision:V1.6.0,
Revision:V1.6.0,
Revision:V1.6.0,
Revision:V1.6.0,
Revision:V1.6.0,
Revision:V1.6.0,
Revision:V1.6.0,
Revision:V1.6.0,
Revision:V1.6.0,
Revision:V1.6.0,
Revision:V1.6.0,
Revision:V1.6.0,
Revision:V1.6.0,
Revision:V1.6.0,
Revision:V1.6.0,
Revision:V1.6.0,
Revision:V1.6.0,
Revision:V1.6.0,
Revision:V1.6.0,
Revision:V1.6.0,
Revision:V1.6.0,
Revision:V1.6.0,
Revision:V1.6.0,
Revision:V1.6.0,
Revision:V1.6.0,
Revision:V1.6.0,
Revision:V1.6.0,
Revision:V1.6.0,
Revision:V1.6.0,
Revision:V1.6.0,
Revision:V1.6.0,
Revision:V1.6.0,
Revision:V1.6.0,
Revision:V1.6.0,
Revision:V1.6.0,
Revision:V1.6.0,
Revision:V1.6.0,
Revision:V1.6.0,
Revision:V1.6.0,
Revision:V1.6.0,
Revision:V1.6.0,
Revision:V1.6.0,
Revision:V1.6.0,
Revision:V1.6.0,
Revision:V1.6.0,
Revision:V1.6.0,
Revision:V1.6.0,
Revision:V1.6.0,
Revision:V1.6.0,
Revision:V1.6.0,
Revision:V1.6.0,
Revision:V1.6.0,
Revision:V1.6.0,
Revision:V1.6.0,
Revision:V1.6.0,
Revision:V1.6.0,
Revision:V1.6.0,
Revision:V1.6.0,
Revision:V1.6.0,
Revision:V1.6.0,
Revision:V1.6.0,
Revision:V1.6.0,
Revision:V1.6.0,
Revision:V1.6.0,
Revision:V1.6.0,
Revision:V1.6.0,
Revision:V1.6.0,
Revision:V1.6.0,
Revision:V1.6.0,
Revision:V1.6.0,
Revision:V1.6.0,
Revision:V1.6.0,
Revision:V1.6.0,
Revision:V1.6.0,
Revision:V1.6.0,
Revision:V1.6.0,
Revision:V1.6.0,
Revision:V1.6.0,
Revision:V1.6.0,
Revision:V1.6.0,
Revision:V1.6.0,
Revision:V1.6.0,
Revision:V1.6.0,
Revision:V1.6.0,
Revision:V1.6.0,
Revision:V1.6.0,
Revision:V1.6.0,
Revision:V1.6.0,
Revision:V1.6.0,
Revision:V1.6.0,
Revision:V1.6.0,
Revision:V1.6.0,
Revision:V1.6.0,
Revision:V1.6.0,
Revision:V1.6.0,
Revision:V1.6.0,
Revision:V1.6.0,
Revision:V1.6.0,
Revision:V1.6.0,
Revision:V1.6.0,
Revision:V1.6.0,
Revision:V1.6.0,
Revision:V1.6.0,
Revision:V1.6.0,
Revision:V1.6.0,
Revision:V1.6.0,
Revision:V1.6.0,
Revision:V1.6.0,
Revision:V1.6.0,
Revision:V1.6.0,
Revision:V1.6.0,
Revision:V1.6.0,
Revision:V1.7.0,
Revision:V1.7.0,
Revision:V1.7.0,
Revision:V1.7.0,
Revision:V1.7.0,
Revision:V1.7.0,
Revision:V1.7.0,
Revision:V1.7.0,
Revision:V1.7.0,
Revision:V1.7.0,
Revision:V1.7.0,
Revision:V1.7.0,
Revision:V1.7.0,
Revision:V1.7.0,
Revision:V1.7.0,
Revision:V1.7.0,
Revision:V1.7.0,
Revision:V1.7.0,
Revision:V1.7.0,
Revision:V1.7.0,
Revision:V1.7.0,
Revision:V1.7.0,
Revision:V1.7.0,
Revision:V1.7.0,
Revision:V1.7.0,
Revision:V1.7.0,
Revision:V1.7.0,
Revision:V1.7.0,
Revision:V1.7.0,
Revision:V1.7.0,
Revision:V1.7.0,
Revision:V1.7.0,
Revision:V1.7.0,
Revision:V1.7.0,
Revision:V1.7.0,
Revision:V1.7.0,
Revision:V1.7.0,
Revision:V1.7.0,
Revision:V1.7.0,
Revision:V1.7.0,
Revision:V1.7.0,
Revision:V1.7.0,
Revision:V1.7.0,
Revision:V1.7.0,
Revision:V1.7.0,
Revision:V1.7.0,
Revision:V1.7.0,
Revision:V1.7.0,
Revision:V1.7.0,
Revision:V1.7.0,
Revision:V1.7.0,
Revision:V1.7.0,
Revision:V1.7.0,
Revision:V1.7.0,
Revision:V1.7.0,
Revision:V1.7.0,
Revision:V1.7.0,
Revision:V1.7.0,
Revision:V1.7.0,
Revision:V1.7.0,
Revision:V1.7.0,
Revision:V1.7.0,
Revision:V1.7.0,
Revision:V1.7.0,
Revision:V1.7.0,
Revision:V1.7.0,
Revision:V1.7.0,
Revision:V1.7.0,
Revision:V1.7.0,
Revision:V1.7.0,
Revision:V1.7.0,
Revision:V1.7.0,
Revision:V1.7.0,
Revision:V1.7.0,
Revision:V1.7.0,
Revision:V1.7.0,
Revision:V1.7.0,
Revision:V1.7.0,
Revision:V1.7.0,
Revision:V1.7.0,
Revision:V1.7.0,
Revision:V1.7.0,
Revision:V1.7.0,
Revision:V1.7.0,
Revision:V1.7.0,
Revision:V1.7.0,
Revision:V1.7.0,
Revision:V1.7.0,
Revision:V1.7.0,
Revision:V1.7.0,
Revision:V1.7.0,
Revision:V1.7.0,
Revision:V1.7.0,
Revision:V1.7.0,
Revision:V1.7.0,
Revision:V1.7.0,
Revision:V1.7.0,
Revision:V1.7.0,
Revision:V1.7.0,
Revision:V1.7.0,
Revision:V1.7.0,
Revision:V1.7.0,
Revision:V1.7.0,
Revision:V1.7.0,
Revision:V1.7.0,
Revision:V1.7.0,
Revision:V1.7.0,
Revision:V1.7.0,
Revision:V1.7.0,
Revision:V1.7.0,
Revision:V1.7.0,
Revision:V1.7.0,
Revision:V1.7.0,
Revision:V1.7.0,
Revision:V1.7.0,
Revision:V1.7.0,
Revision:V1.7.0,
Revision:V1.7.0,
Revision:V1.7.0,
Revision:V1.7.0,
Revision:V1.7.0,
Revision:V1.7.0,
Revision:V1.7.0,
Revision:V1.7.0,
Revision:V1.7.0,
Revision:V1.7.0,
Revision:V1.7.0,
Revision:V1.7.0,
Revision:V1.7.0,
Revision:V1.7.0,
Revision:V1.7.0,
Revision:V1.7.0,
Revision:V1.7.0,
Revision:V1.7.0,
Revision:V1.7.0,
Revision:V1.7.0,
Revision:V1.7.0,
Revision:V1.7.0,
Revision:V1.7.0,
Revision:V1.7.0,
Revision:V1.7.0,
Revision:V1.7.0,
Revision:V1.7.0,
Revision:V1.7.0,
Revision:V1.7.0,
Revision:V1.7.0,
Revision:V1.7.0,
Revision:V1.7.0,
Revision:V1.7.0,
Revision:V1.7.0,
Revision:V1.7.0,
Revision:V1.7.0,
Revision:V1.7.0,
Revision:V1.7.0,
Revision:V1.7.0,
Revision:V1.7.0,
Revision:V1.7.0,
Revision:V1.7.0,
Revision:V1.7.0,
Revision:V1.7.0,
Revision:V1.7.0,
Revision:V1.7.0,
Revision:V1.7.0,
Revision:V1.7.0,
Revision:V1.7.0,
Revision:V1.7.0,
Revision:V1.7.0,
Revision:V1.7.0,
Revision:V1.7.0,
Revision:V1.7.0,
Revision:V1.7.0,
Revision:V1.7.0,
Revision:V1.7.0,
Revision:V1.7.0,
Revision:V1.7.0,
Revision:V1.7.0,
Revision:V1.7.0,
Revision:V1.7.0,
Revision:V1.7.0,
Revision:V1.7.0,
Revision:V1.7.0,
Revision:V1.7.0,
Revision:V1.7.0,
Revision:V1.7.0,
Revision:V1.7.0,
Revision:V1.7.0,
Revision:V1.7.0,
Revision:V1.7.0,
Revision:V1.7.0,
Revision:V1.7.0,
Revision:V1.7.0,
Revision:V1.7.0,
Revision:V1.7.0,
Revision:V1.7.0,
Revision:V1.7.0,
Revision:V1.7.0,
Revision:V1.7.0,
Revision:V1.7.0,
Revision:V1.7.0,
Revision:V1.7.0,
Revision:V1.7.0,
Revision:V1.7.0,
Revision:V1.7.0,
Revision:V1.7.0,
Revision:V1.7.0,
Revision:V1.7.0,
Revision:V1.7.0,
Revision:V1.7.0,
Revision:V1.7.0,
Revision:V1.7.0,
Revision:V1.7.0,
Revision:V1.7.0,
Revision:V1.7.0,
Revision:V1.7.0,
Revision:V1.7.0,
Revision:V1.7.0,
Revision:V1.7.0,
Revision:V1.7.0,
Revision:V1.7.0,
Revision:V1.7.0,
Revision:V1.7.0,
Revision:V1.7.0,
Revision:V1.7.0,
Revision:V1.7.0,
Revision:V1.7.0,
Revision:V1.7.0,
Revision:V1.7.0,
Revision:V1.7.0,
Revision:V1.7.0,
Revision:V1.7.0,
Revision:V1.7.0,
Revision:V1.7.0,
Revision:V1.7.0,
Revision:V1.7.0,
Revision:V1.7.0,
Revision:V1.7.0,
Revision:V1.7.0,
Revision:V1.7.0,
Revision:V1.7.0,
Revision:V1.7.0,
Revision:V1.7.0,
Revision:V1.7.0,
Revision:V1.7.0,
Revision:V1.7.0,
Revision:V1.7.0,
Revision:V1.7.0,
Revision:V1.7.0,
Revision:V1.7.0,
Revision:V1.7.0,
Revision:V1.7.0,
Revision:V1.7.0,
Revision:V1.8.0,
Revision:V1.8.0,
Revision:V1.8.0,
Revision:V1.8.0,
Revision:V1.8.0,
Revision:V1.8.0,
Revision:V1.8.0,
Revision:V1.8.0,
Revision:V1.8.0,
Revision:V1.8.0,
Revision:V1.8.0,
Revision:V1.8.0,
Revision:V1.8.0,
Revision:V1.8.0,
Revision:V1.8.0,
Revision:V1.8.0,
Revision:V1.8.0,
Revision:V1.8.0,
Revision:V1.8.0,
Revision:V1.8.0,
Revision:V1.8.0,
Revision:V1.8.0,
Revision:V1.8.0,
Revision:V1.8.0,
Revision:V1.8.0,
Revision:V1.8.0,
Revision:V1.8.0,
Revision:V1.8.0,
Revision:V1.8.0,
Revision:V1.8.0,
Revision:V1.8.0,
Revision:V1.8.0,
Revision:V1.8.0,
Revision:V1.8.0,
Revision:V1.8.0,
Revision:V1.8.0,
Revision:V1.8.0,
Revision:V1.8.0,
Revision:V1.8.0,
Revision:V1.8.0,
Revision:V1.8.0,
Revision:V1.8.0,
Revision:V1.8.0,
Revision:V1.8.0,
Revision:V1.8.0,
Revision:V1.8.0,
Revision:V1.8.0,
Revision:V1.8.0,
Revision:V1.8.0,
Revision:V1.8.0,
Revision:V1.8.0,
Revision:V1.8.0,
Revision:V1.8.0,
Revision:V3.0.0,
Revision:V3.0.0,
Revision:V3.0.0,
Revision:V3.0.0,
Revision:V3.0.0,
Revision:V3.0.0,
Revision:V3.0.0,
Revision:V3.0.0,
Revision:V3.0.0,
Revision:V3.0.0,
Revision:V3.0.0,
Revision:V3.0.0,
Revision:V3.0.0,
Revision:V3.0.0,
Revision:V3.0.0,
Revision:V3.0.0,
Revision:V3.0.0,
Revision:V3.0.0,
Revision:V3.0.0,
Revision:V3.0.0,
Revision:V3.0.0,
Revision:V3.0.0,
Revision:V3.0.0,
Revision:V3.0.0,
Revision:V3.0.0,
Revision:V3.0.0,
Revision:V3.0.0,
Revision:V3.0.0,
Revision:V3.0.0,
Revision:V3.0.0,
Revision:V3.0.0,
Revision:V3.0.0,
Revision:V3.0.0,
Revision:V3.0.0,
Revision:V3.0.0,
Revision:V3.0.0,
Revision:V3.0.0,
Revision:V3.0.0,
Revision:V3.0.0,
Revision:V3.0.0,
Revision:V3.0.0,
Revision:V3.0.0,
Revision:V3.0.0,
Revision:V3.0.0,
Revision:V3.0.0,
Revision:V3.0.0,
Revision:V3.0.0,
Revision:V3.0.0,
Revision:V3.0.0,
Revision:V3.0.0,
Revision:V3.0.0,
Revision:V3.0.0,
Revision:V3.0.0,
Revision:V3.0.0,
Revision:V3.0.0,
Revision:V3.0.0,
Revision:V3.0.0,
Revision:V3.0.0,
Revision:V3.0.0,
Revision:V3.0.0,
Revision:V3.0.0,
Revision:V3.0.0,
Revision:V3.0.0,
Revision:V3.0.0,
Revision:V3.0.0,
Revision:V3.0.0,
Revision:V3.0.0,
Revision:V3.0.0,
Revision:V3.0.0,
Revision:V3.0.0,
Revision:V3.0.0,
Revision:V3.0.0,
Revision:V3.0.0,
Revision:V3.0.0,
Revision:V3.0.0,
Revision:V3.0.0,
Revision:V3.0.0,
Revision:V3.0.0,
Revision:V3.0.0,
Revision:V3.0.0,
Revision:V3.0.0,
Revision:V3.0.0,
Revision:V3.0.0,
Revision:V3.0.0,
Revision:V3.0.0,
Revision:V3.0.0,
Revision:V3.0.0,
Revision:V3.0.0,
Revision:V3.0.0,
Revision:V3.0.0,
Revision:V3.0.0,
Revision:V3.0.0,
Revision:V3.0.0,
Revision:V3.0.0,
Revision:V3.0.0,
Revision:V3.0.0,
Revision:V3.0.0,
Revision:V3.0.0,
Revision:V3.0.0,
Revision:V3.0.0,
Revision:V3.0.0,
Revision:V3.0.0,
Revision:V3.0.0,
Revision:V3.0.0,
Revision:V3.0.0,
Revision:V3.0.0,
Revision:V3.0.0,
Revision:V3.0.0,
Revision:V3.0.0,
Revision:V3.0.0,
Revision:V3.0.0,
Revision:V3.0.0,
Revision:V3.0.0,
Revision:V3.0.0,
Revision:V3.0.0,
Revision:V3.0.0,
Revision:V3.0.0,
Revision:V3.0.0,
Revision:V3.0.0,
Revision:V3.0.0,
Revision:V3.0.0,
Revision:V3.0.0,
Revision:V3.0.0,
Revision:V3.0.0,
Revision:V3.0.0,
Revision:V3.0.0,
Revision:V3.0.0,
Revision:V3.0.0,
Revision:V3.0.0,
Revision:V3.0.0,
Revision:V3.0.0,
Revision:V3.0.0,
Revision:V3.0.0,
Revision:V3.0.0,
Revision:V3.0.0,
Revision:V3.0.0,
Revision:V3.0.0,
Revision:V3.0.0,
Revision:V3.0.0,
Revision:V3.0.0,
Revision:V3.0.0,
Revision:V3.0.0,
Revision:V3.0.0,
Revision:V3.0.0,
Revision:V3.0.0,
Revision:V3.0.0,
Revision:V3.0.0,
Revision:V3.0.0,
Revision:V3.0.0,
Revision:V3.0.0,
Revision:V3.0.0,
Revision:V3.0.0,
Revision:V3.0.0,
Revision:V3.0.0,
Revision:V3.0.0,
Revision:V3.0.0,
Revision:V3.0.0,
Revision:V3.0.0,
Revision:V3.0.0,
Revision:V3.0.0,
Revision:V3.0.0,
Revision:V3.0.0,
Revision:V3.0.0,
Revision:V3.0.0,
Revision:V3.0.0,
Revision:V3.0.0,
Revision:V3.0.0,
Revision:V3.0.0,
Revision:V3.0.0,
Revision:V3.0.0,
Revision:V3.0.0,
Revision:V3.0.0,
Revision:V3.0.0,
Revision:V3.0.0,
Revision:V3.0.0,
Revision:V3.0.0,
Revision:V3.0.0,
Revision:V3.0.0,
Revision:V3.0.0,
Revision:V3.0.0,
Revision:V3.0.0,
Revision:V3.0.0,
Revision:V3.0.0,
Revision:V3.0.0,
Revision:V3.0.0,
Revision:V3.0.0,
Revision:V3.0.0,
Revision:V3.0.0,
Revision:V3.0.0,
Revision:V3.0.0,
Revision:V3.0.0,
Revision:V3.0.0,
Revision:V3.0.0,
Revision:V3.0.0,
Revision:V3.0.0,
Revision:V3.0.0,
Revision:V3.0.0,
Revision:V3.0.0,
Revision:V3.0.0,
Revision:V3.0.0,
Revision:V3.0.0,
Revision:V3.0.0,
Revision:V3.0.0,
Revision:V3.0.0,
Revision:V3.0.0,
Revision:V3.0.0,
Revision:V3.0.0,
Revision:V3.0.0,
Revision:V3.0.0,
Revision:V3.0.0,
Revision:V3.0.0,
Revision:V3.0.0,
Revision:V3.0.0,
Revision:V3.0.0,
Revision:V3.0.0,
Revision:V3.0.0,
Revision:V3.0.0,
Revision:V3.0.0,
Revision:V3.0.0,
Revision:V3.0.0,
Revision:V3.0.0,
Revision:V3.0.0,
Revision:V3.0.0,
Revision:V3.0.0,
Revision:V3.0.0,
Revision:V3.0.0,
Revision:V3.0.0,
Revision:V3.0.0,
Revision:V3.0.0,
Revision:V3.0.0,
Revision:V3.0.0,
Revision:V3.0.0,
Revision:V3.0.0,
Revision:V3.0.0,
Revision:V3.0.0,
Revision:V3.0.0,
Revision:V3.0.0,
Revision:V3.0.0,
Revision:V3.0.0,
Revision:V3.0.0,
Revision:V3.0.0,
Revision:V3.0.0,
Revision:V3.0.0,
Revision:V3.0.0,
Revision:V3.0.0,
Revision:V3.0.0,
Revision:V3.0.0,
Revision:V3.0.0,
Revision:V3.0.0,
Revision:V3.0.0,
Revision:V3.0.0,
Revision:V3.0.0,
Revision:V3.0.0,
Revision:V3.0.0,
Revision:V3.0.0,
Revision:V3.0.0,
Revision:V3.0.0,
Revision:V3.0.0,
Revision:V3.0.0,
Revision:V3.0.0,
Revision:V3.0.0,
Revision:V3.0.0,
Revision:V3.0.0,
Revision:V3.0.0,
Revision:V3.0.0,
Revision:V3.0.0,
Revision:V3.0.0,
Revision:V3.0.0,
Revision:V3.0.0,
Revision:V3.1.0,
Revision:V3.1.0,
Revision:V3.1.0,
Revision:V3.1.0,
Revision:V3.1.0,
Revision:V3.1.0,
Revision:V3.1.0,
Revision:V3.1.0,
Revision:V3.1.0,
Revision:V3.1.0,
Revision:V3.2.0,
Revision:V3.2.0,
Revision:V3.2.0,
Revision:V3.2.0,
Revision:V3.2.0,
Revision:V3.2.0,
Revision:V3.2.0,
Revision:V3.2.0,
Revision:V3.2.0,
Revision:V3.2.0,
Revision:V3.2.0,
Revision:V3.2.0,
Revision:V3.2.0,
Revision:V3.2.0,
Revision:V3.2.0,
Revision:V3.2.0,
Revision:V3.2.0,
Revision:V3.2.0,
Revision:V3.2.0,
Revision:V3.2.0,
Revision:V3.2.0,
Revision:V3.2.0,
Revision:V3.2.0,
Revision:V3.2.0,
Revision:V3.2.0,
Revision:V3.2.0,
Revision:V3.2.0,
Revision:V3.2.0,
Revision:V3.2.0,
Revision:V3.2.0,
Revision:V3.2.0,
Revision:V3.2.0,
Revision:V3.2.0,
Revision:V3.2.0,
Revision:V3.2.0,
Revision:V3.2.0,
Revision:V3.2.0,
Revision:V3.2.0,
Revision:V3.2.0,
Revision:V3.2.0,
Revision:V3.2.0,
Revision:V3.2.0,
Revision:V3.2.0,
Revision:V3.2.0,
Revision:V3.2.0,
Revision:V3.2.0,
Revision:V3.2.0,
Revision:V3.2.0,
Revision:V3.2.0,
Revision:V3.2.0,
Revision:V3.2.0,
Revision:V3.2.0,
Revision:V3.2.0,
Revision:V3.2.0,
Revision:V3.2.0,
Revision:V3.2.0,
Revision:V3.2.0,
Revision:V3.2.0,
Revision:V3.2.0,
Revision:V3.2.0,
Revision:V3.2.0,
Revision:V3.2.0,
Revision:V3.3.0,
Revision:V3.4.0,
Revision:V3.4.0,
Revision:V3.4.0,
Revision:V4.0.0,
Revision:V4.0.0,
Revision:V5.0.0,
Revision:V5.0.0,
Revision:V5.0.0,
Revision:V5.0.0,
Revision:V5.0.0,
Revision:V5.0.0,
Revision:V5.0.0,
Revision:V5.0.0,
Revision:V5.0.0,
Revision:V5.0.0,
Revision:V5.0.0,
Revision:V5.0.0,
Revision:V5.0.0,
Revision:V5.0.0,
Revision:V5.0.0,
Revision:V5.0.0,
Revision:V5.0.0,
Revision:V5.0.0,
Revision:V5.0.0,
Revision:V5.0.0,
Revision:V5.0.0,
Revision:V5.0.0,
Revision:V5.0.0,
Revision:V5.0.0,
Revision:V5.0.0,
Revision:V5.0.0,
Revision:V5.0.0,
Revision:V5.0.0,
Revision:V5.0.0,
Revision:V5.0.0,
Revision:V5.0.0,
Revision:V5.0.0,
Revision:V5.0.0,
Revision:V5.0.0,
Revision:V5.0.0,
Revision:V5.0.0,
Revision:V5.0.0,
Revision:V5.0.0,
Revision:V5.0.0,
Revision:V5.0.0,
Revision:V5.0.0,
Revision:V5.0.0,
Revision:V5.0.0,
Revision:V5.0.0,
Revision:V5.0.0,
Revision:V5.0.0,
Revision:V5.0.0,
Revision:V5.0.0,
Revision:V5.0.0,
Revision:V5.0.0,
Revision:V5.0.0,
Revision:V5.0.0,
Revision:V5.0.0,
Revision:V5.0.0,
Revision:V5.0.0,
Revision:V5.0.0,
Revision:V5.0.0,
Revision:V5.0.0,
Revision:V5.0.0,
Revision:V5.0.0,
Revision:V5.0.0,
Revision:V5.0.0,
Revision:V5.0.0,
Revision:V5.0.0,
Revision:V5.0.0,
Revision:V5.0.0,
Revision:V5.0.0,
Revision:V5.0.0,
Revision:V5.0.0,
Revision:V5.0.0,
Revision:V5.0.0,
Revision:V5.0.0,
Revision:V5.0.0,
Revision:V5.0.0,
Revision:V5.0.0,
Revision:V5.0.0,
Revision:V5.0.0,
Revision:V5.0.0,
Revision:V5.0.0,
Revision:V5.0.0,
Revision:V5.0.0,
Revision:V5.0.0,
Revision:V5.0.0,
Revision:V5.0.0,
Revision:V5.0.0,
Revision:V5.0.0,
Revision:V5.0.0,
Revision:V5.0.0,
Revision:V5.0.0,
Revision:V5.0.0,
Revision:V5.0.0,
Revision:V5.0.0,
Revision:V5.0.0,
Revision:V5.0.0,
Revision:V5.0.0,
Revision:V5.0.0,
Revision:V5.0.0,
Revision:V5.0.0,
Revision:V5.0.0,
Revision:V5.0.0,
Revision:V5.0.0,
Revision:V5.0.0,
Revision:V5.0.0,
Revision:V5.0.0,
Revision:V5.0.0,
Revision:V5.0.0,
Revision:V5.0.0,
Revision:V5.0.0,
Revision:V5.0.0,
Revision:V5.0.0,
Revision:V5.0.0,
Revision:V5.0.0,
Revision:V5.0.0,
Revision:V5.0.0,
Revision:V5.0.0,
Revision:V5.0.0,
Revision:V5.0.0,
Revision:V5.0.0,
Revision:V5.0.0,
Revision:V5.0.0,
Revision:V5.0.0,
Revision:V5.0.0,
Revision:V5.0.0,
Revision:V5.0.0,
Revision:V5.0.0,
Revision:V5.0.0,
Revision:V5.0.0,
Revision:V5.0.0,
Revision:V5.0.0,
Revision:V5.0.0,
Revision:V5.0.0,
Revision:V5.0.0,
Revision:V5.0.0,
Revision:V5.0.0,
Revision:V5.0.0,
Revision:V5.0.0,
Revision:V5.0.0,
Revision:V5.0.0,
Revision:V5.0.0,
Revision:V5.0.0,
Revision:V5.0.0,
Revision:V5.0.0,
Revision:V5.0.0,
Revision:V5.0.0,
Revision:V5.0.0,
Revision:V5.0.0,
Revision:V5.0.0,
Revision:V5.0.0,
Revision:V5.0.0,
Revision:V5.0.0,
Revision:V5.0.0,
Revision:V5.0.0,
Revision:V5.0.0,
Revision:V5.0.0,
Revision:V5.0.0,
Revision:V5.0.0,
Revision:V5.0.0,
Revision:V5.0.0,
Revision:V5.0.0,
Revision:V5.0.0,
Revision:V5.0.0,
Revision:V5.0.0,
Revision:V5.0.0,
Revision:V5.0.0,
Revision:V5.0.0,
Revision:V5.0.0,
Revision:V5.0.0,
Revision:V5.0.0,
Revision:V5.0.0,
Revision:V5.0.0,
Revision:V5.0.0,
Revision:V5.0.0,
Revision:V5.0.0,
Revision:V5.0.0,
Revision:V5.0.0,
Revision:V5.0.0,
Revision:V5.0.0,
Revision:V5.0.0,
Revision:V5.0.0,
Revision:V5.0.0,
Revision:V5.0.0,
Revision:V5.0.0,
Revision:V5.0.0,
Revision:V5.0.0,
Revision:V5.0.0," ;

CM_ SG_ 245 Checksum_0F5 "Checksum signal for frame";
CM_ SG_ 245 MessageCounter_0F5 "Message counter signal for frame";
CM_ SG_ 245 ACU_YawRate "Yaw rate (clockwise is negative, counterclockwise is positive)";
CM_ SG_ 245 ACU_YawRateStatus "Yaw rate status";
CM_ SG_ 246 Checksum_0F6 "Checksum signal for frame";
CM_ SG_ 246 MessageCounter_0F6 "Message counter signal for frame";
CM_ SG_ 246 ACU_LatA "Lateral acceleration(From the driver's perspective, from left to right is the positive direction of lateral acceleration)";
CM_ SG_ 246 ACU_LatAStatus "Lateral acceleration status";
CM_ SG_ 246 ACU_LgtA "Longitudinal acceleration(The forward direction of the vehicle is the positive direction of the longitudinal acceleration)";
CM_ SG_ 246 ACU_LgtAStatus "Longitudinal acceleration status";
CM_ SG_ 151 Checksum_097 "Checksum signal for frame";
CM_ SG_ 151 MessageCounter_097 "Message counter signal for frame";
CM_ SG_ 151 ACU_CrashOutputSts "Crash Output Status";
CM_ SG_ 151 ACU_CrashOutputStsValid "Collision signal effective indication";
CM_ SG_ 151 ACU_DriverSeatBeltSts "Driver seat belt status";
CM_ SG_ 151 ACU_DriverSeatBeltStsValid "Driver seat belt state invalid";
CM_ SG_ 151 ACU_PassengerSeatBeltSts "Passenger seat belt status";
CM_ SG_ 151 ACU_PassengerSeatBeltStsValid "Passenger seat belt status invalid signal";
CM_ SG_ 151 ACU_PassengerSts "Passenger seat occupied state";
CM_ SG_ 151 ACU_SecondLeftSeatBeltSts "Second row left seat belt condition";
CM_ SG_ 151 ACU_RLSeatBeltStatusValid "Second row seat belt status on the left is valid";
CM_ SG_ 151 ACU_SecondLeftSts "The left seat of the second row is occupied";
CM_ SG_ 151 ACU_SecondRightSeatBeltSts "Second row right seat belt status";
CM_ SG_ 151 ACU_RRSeatBeltStatusValid "Second row seat belt status on the lright is valid";
CM_ SG_ 151 ACU_SecondRightSts "The right seat of the second row is occupied";
CM_ SG_ 151 ACU_PassengerAirbagSts "Passenger Airbag Status, closed or not";
CM_ SG_ 151 ACU_DriverWarningLampSts "Driver Warning Lamp Status";
CM_ SG_ 151 ACU_PassengerWarningLampSts "Passenger Warning Lamp Status";
CM_ SG_ 151 ACU_WarningLampSts "WarningLampStatus";
CM_ SG_ 225 Checksum_0E1 "Checksum signal for frame";
CM_ SG_ 225 MessageCounter_0E1 "Message counter signal for frame";
CM_ SG_ 225 ADCU_ACC_Ax_Req "This signal represents the ACC acceleration/deceleration request";
CM_ SG_ 225 ADCU_ACC_ACCEL_Upper_Limit "This signal is the upper value of acceleration limit band.";
CM_ SG_ 225 ADCU_ACC_StandstillReq "ACC request the VLC to decelerate to stop.";
CM_ SG_ 225 ADCU_ACC_DriveOff "ACC request the VLC to drive off.";
CM_ SG_ 225 ADCU_ACC_ACCEL_Lower_Limit "This signal is the lower value of acceleration limit band.";
CM_ SG_ 225 ADCU_ACC_JERK_Upper_Limit "This signal is the value of positive jerk limit request.";
CM_ SG_ 225 ADCU_ACC_JERK_Lower_Limit "This signal is the value of negative jerk limit request.";
CM_ SG_ 224 Checksum_0E0 "Checksum signal for frame";
CM_ SG_ 224 MessageCounter_0E0 "Message counter signal for frame";
CM_ SG_ 224 ADCU_ACCDA_SYS_Failure "ACC/DA system failure state
If this signal is set to anything other than 0, the IBS shall ignore any requests from ACC";
CM_ SG_ 224 ADCU_ACCDA_HandsOFF_Warning "ACC/DA Hands off warning";
CM_ SG_ 224 ADCU_ACC_Mode "ACC mode for system state";
CM_ SG_ 224 ADCU_DA_Mode "DA mode for system state";
CM_ SG_ 226 Checksum_0E2 "Checksum signal for frame";
CM_ SG_ 226 MessageCounter_0E2 "Message counter signal for frame";
CM_ SG_ 226 ADCU_AEBReq "A control requeset flag for AEB";
CM_ SG_ 226 ADCU_FCW_State "This signal describes the state FCW Function.";
CM_ SG_ 226 ADCU_AEB_State "This signal describes the state AEB Function.";
CM_ SG_ 226 ADCU_AEB_Decel_Cmd "Depending on the driving situation, ADCU gives IBS the AEB deceleration command. IBS maintains the deceleration.";
CM_ SG_ 226 ADCU_AEB_AWB_Level "AWB level";
CM_ SG_ 226 ADCU_AEB_AWB_Req "This signal means command to activate AWB";
CM_ SG_ 226 ADCU_AEB_Stop_Req "A control request flag for vehicle stop. AEB expects vehicle to be controlled to a complete stop and hold its state by ESC.";
CM_ SG_ 226 ADCU_AEB_Prefill_CMD "This signal means command to activate pre-fill";
CM_ SG_ 226 ADCU_AEBWarningSts "PEBSWarning,include PreWarning and emergency Warning.";
CM_ SG_ 228 Checksum_0E4 "Checksum signal for frame";
CM_ SG_ 228 MessageCounter_0E4 "Message counter signal for frame";
CM_ SG_ 228 ADCU_APSCrlModeReq "Request Low Speed Maneuvering Control Mode (APS or RC)";
CM_ SG_ 228 ADCU_APSCrlTypReq "Request comfort or emergency brake";
CM_ SG_ 228 ADCU_APSCrlReq "Request Maneuvering dynamic control function (Driving or Low Speed Maneuvering)";
CM_ SG_ 228 ADCU_APSDistanceStop "Maximum distance to go until stop request";
CM_ SG_ 228 ADCU_TargetGear "Shift request signal";
CM_ SG_ 228 ADCU_Parking_CtrlSts "Parking indicator light status";
CM_ SG_ 228 ADCU_APSMaxSpeedReq "V Max request";
CM_ SG_ 228 ADCU_APSComfBrkReq "BrakeMode Request";
CM_ SG_ 228 ADCU_Parking_Mode "APS function status.";
CM_ SG_ 522 Checksum_20A "Checksum signal for frame";
CM_ SG_ 522 MessageCounter_20A "Message counter signal for frame";
CM_ SG_ 522 ADCU_LftlndSta "Left outside rear mirror warning light request";
CM_ SG_ 522 ADCU_RtlndSta "Right outside rear mirror warning light request";
CM_ SG_ 522 ADCU_HazardLampReq "ADAS turn on hazard lamp";
CM_ SG_ 522 ADCU_AHB_MaBeam_Req "High Beam Request";
CM_ SG_ 232 Checksum_0E8 "Checksum signal for frame";
CM_ SG_ 232 MessageCounter_0E8 "Message counter signal for frame";
CM_ SG_ 232 ADCU_APSEPSControlReq "ADCU request EPS control activity indication";
CM_ SG_ 232 ADCU_LatCtrlFaultSts "ADCU lateral control unit fault status";
CM_ SG_ 232 ADCU_LCAEPSControlAct "ADCU lateral control active request";
CM_ SG_ 232 ADCU_EPSSteerAngTarValReq "Request steering wheel angle for ADCU";
CM_ SG_ 232 ADCU_EPSSteerAngSpdReq "Request steering wheel angle speed for ADCU";
CM_ SG_ 515 ADCU_LDW_SYS_Sts "LDW system symbol state";
CM_ SG_ 613 APTC_HVPowerUpReq "APTC high voltage power supply off line request";
CM_ SG_ 613 APTC_HeatingFaltStatus "ptc heater core status";
CM_ SG_ 613 APTC_DriveFaltStatus "Ptc driver status";
CM_ SG_ 613 APTC_LostCommuFaltStatus "TCU signal lost";
CM_ SG_ 613 APTC_IGBTFaltStatus "IGBT failure";
CM_ SG_ 613 APTC_Core1TempSensorFaltStatus "Left core sensor temperature error";
CM_ SG_ 613 APTC_LeftCoreTemp "Left core sensor temperature";
CM_ SG_ 613 APTC_RightCoreTemp "Right core sensor temperature";
CM_ SG_ 613 APTC_PowerConsumption "APTC OutPut Power";
CM_ SG_ 613 APTC_HVBusVoltage "HV voltage";
CM_ SG_ 613 APTC_OverCurrentFault "Indicate Over Current Fault";
CM_ SG_ 613 APTC_LowVoltageStatus "Indicate Low Volatge Status";
CM_ SG_ 613 APTC_HighVoltageStatus "Indicate High Volatge Status";
CM_ SG_ 613 APTC_OverLoadStatus "Indicate Over load Fault";
CM_ SG_ 613 APTC_IGBTTempSensorStatus "Indicate IGBT Sensor Status";
CM_ SG_ 613 APTC_PCBTempSensorStatus "Indicate PCB Sensor Status";
CM_ SG_ 613 APTC_Core2TempSensorFaltStatus "Right core sensor temperature error";
CM_ SG_ 784 AVAS_SoundEnableSts "Current AVAS state (Enable/Disable)";
CM_ SG_ 784 AVAS_ErrorIDentification "Show sound error";
CM_ SG_ 784 AVAS_ShowCurrSoundSts "Current AVAS state of selected sound";
CM_ SG_ 822 BCM_RLHSHumidSensorValue "This signal delivers information about air humid : from 0% to 100%";
CM_ SG_ 822 BCM_RLHSSolarDrvr "The left solar sensor measured";
CM_ SG_ 822 BCM_RLHSSolarPass "The right solar sensor measured";
CM_ SG_ 822 BCM_RLHSTempSensorValue "This signal delivers information about temperature in car";
CM_ SG_ 822 BCM_RLHSTempDewPoint "Dew point temperature";
CM_ SG_ 822 BCM_HUDBriUnit "HUD Brightness Unit";
CM_ SG_ 822 BCM_HUDBriRawVal "Brightness adjust value for HUD";
CM_ SG_ 823 BCM_WelLightshowTimeSts "Welcome light time state signal";
CM_ SG_ 823 BCM_TaxiArrIllSts "Taxi arrive illumination  setting state signal";
CM_ SG_ 823 BCM_FollowMeHomeTimeSts "Follow me home time state signal";
CM_ SG_ 823 BCM_CarSearchSts "My car finder state";
CM_ SG_ 823 BCM_CornerLampSetSts "Auto corner lamp set state signal";
CM_ SG_ 823 BCM_WasherExtraWipeSts "Washer extra wipe status";
CM_ SG_ 823 BCM_WelcomeOnOffSts "BCM feedback automatically activate the welcome light stauts";
CM_ SG_ 823 BCM_CarSharingTimeSts "BCM feedback car sharing welcome light runtime status";
CM_ SG_ 823 BCM_CarSharingColorSts "BCM feedback car sharing color status";
CM_ SG_ 823 BCM_CarSharingLightSts "BCM feedback car sharing light stauts";
CM_ SG_ 823 BCM_HeadlLampMotorError "Headlight height adjustment motor malfunction";
CM_ SG_ 824 Checksum_338 "Checksum signal for frame";
CM_ SG_ 824 MessageCounter_338 "Message counter signal for frame";
CM_ SG_ 824 BCM_HazardWarnSts "The hazard warning state signal";
CM_ SG_ 824 BCM_DRLReq "DRL request";
CM_ SG_ 824 BCM_FollowMeHomeSts "Follow me home feedback signal";
CM_ SG_ 824 BCM_ChargingLightReq "Charging light show active";
CM_ SG_ 824 BCM_TaxiArrIllReq "Taxi arrive illumination active request signal";
CM_ SG_ 824 BCM_LeCornrgLiReq "Left turn assist lamp request";
CM_ SG_ 824 BCM_MainBeamReq "High beam request signal";
CM_ SG_ 824 BCM_DippedBeamReq "Low beam request signal";
CM_ SG_ 824 BCM_RiCornrgLiReq "Right turn assist lamp request";
CM_ SG_ 824 BCM_RLS_AutoLampSenSts "The dipped beam headlamp automatic control sensitivity setting state signal";
CM_ SG_ 824 BCM_RearFogLampSts "Rear fog state signal";
CM_ SG_ 824 BCM_ExtLightFault "Exterior lighting fault signal";
CM_ SG_ 824 BCM_StoplampReq "Stop lamp request signal";
CM_ SG_ 824 BCM_AutoLmpSts "Auto light state signal";
CM_ SG_ 824 BCM_HeightSetSts "Head lamp height set state";
CM_ SG_ 824 BCM_RLS_LightSensorFault "Light sensor fault signal";
CM_ SG_ 824 BCM_RLS_RainSensorFault "Rain sensor fault signal";
CM_ SG_ 824 BCM_PosLampReq "Position lamp request signal";
CM_ SG_ 824 BCM_FrontFogLampReq "Front fog lamp request signal";
CM_ SG_ 824 BCM_FRDomeLampSts "Front Dome Lamp setting feedback";
CM_ SG_ 824 BCM_RRDomeLampSts "Rear Dome Lamp setting feedback";
CM_ SG_ 824 BCM_WiperFaultWarn "Front wiper fault warn";
CM_ SG_ 825 Checksum_339 "Checksum signal for frame";
CM_ SG_ 825 MessageCounter_339 "Message counter signal for frame";
CM_ SG_ 825 BCM_LockFailRemindReq "Locking fail reminder request";
CM_ SG_ 825 BCM_LockRLCtrlReq "Left rear door lock control command";
CM_ SG_ 825 BCM_LockRRCtrlReq "Right rear door lock control command";
CM_ SG_ 825 BCM_LockFRCtrlReq "Right front door lock control command";
CM_ SG_ 825 BCM_LockFLCtrlReq "Left front door lock control command";
CM_ SG_ 825 BCM_AwayLockSts "away lock settings feedback";
CM_ SG_ 825 BCM_OutsideUnlockModeSts "Outside unlock mode set feedback";
CM_ SG_ 825 BCM_ApproachingUnlockSts "Approaching unlock set feedback";
CM_ SG_ 825 BCM_ChrgFlapSts "Charging flap status";
CM_ SG_ 825 BCM_TailgateLogicLockSts "Tailgate logic lock status";
CM_ SG_ 825 BCM_TailgateSts "Tailgate status";
CM_ SG_ 825 BCM_HoodSts "Hood status";
CM_ SG_ 825 BCM_CentralLockSts "Central lock status";
CM_ SG_ 825 BCM_ChdLockSts "Child lock status";
CM_ SG_ 825 BCM_GlassUnclsWarnCtrlRqst "Latching automatic window closing control command";
CM_ SG_ 825 BCM_NFCCloseDoorAndLockFeedback "NFC Close Door And Lock Setting Sts";
CM_ SG_ 825 BCM_WinAntipinchNotice "Window Anti-Pinch Event Notification";
CM_ SG_ 825 BCM_LockDoorOpenReHornSts "Lock event with Open door reminder state";
CM_ SG_ 825 BCM_AntiTheftReHornSts "Anti-theft horn alert state";
CM_ SG_ 825 BCM_LeftKeyReHornSts "Horn reminder state for keys left in the car";
CM_ SG_ 825 BCM_AlarmEnableSts "Alarm enable states";
CM_ SG_ 825 BCM_RelockSts "Auto re-lock status";
CM_ SG_ 825 BCM_WinClsReq "Request user confirmation to close windows when it rains";
CM_ SG_ 826 Checksum_33A "Checksum signal for frame";
CM_ SG_ 826 MessageCounter_33A "Message counter signal for frame";
CM_ SG_ 826 BCM_GearTimesSts "R gear times status";
CM_ SG_ 826 BCM_ChrgFlapLockSts "Charging flap lock status";
CM_ SG_ 826 BCM_FRSeatBeltRemindReq "The front passenger seat belt unfastened reminder request signal";
CM_ SG_ 826 BCM_FLSeatBeltRemindReq "The driver seat belt unfastened reminder request signal";
CM_ SG_ 826 BCM_KeyNotInCarRemind "Key not found reminder";
CM_ SG_ 826 BCM_RRSeatBeltRemindReq "The second row right seat belt unfastened reminder request signal";
CM_ SG_ 826 BCM_RLSeatBeltRemindReq "The second row left seat belt unfastened reminder request signal";
CM_ SG_ 826 BCM_WiperServiceSts "Wiper Service Mode State";
CM_ SG_ 826 BCM_AutoCloseWinFunSts "Auto close window function status";
CM_ SG_ 826 BCM_DomeLampBrightSts "Dome lamp brightness feedback signal";
CM_ SG_ 826 BCM_PuddleLiReq "Puddle light in exterior mirror request";
CM_ SG_ 826 BCM_DomeLampAutoSts "Dome Lamp automatic setting";
CM_ SG_ 826 BCM_FrontWiperModeSts "Front wipers mode status feedback";
CM_ SG_ 826 BCM_WiperWorkingSts "Front wipers working status";
CM_ SG_ 826 BCM_WelLightshowOnOffSts "Welcome Light show switch state signal";
CM_ SG_ 625 checksum_271 "Checksum signal for frame";
CM_ SG_ 625 MessageCounter_271 "Message counter signal for frame";
CM_ SG_ 625 BCM_PepsPowerMode "Power mode";
CM_ SG_ 625 BCM_PowerOffDisplayReq "Power-down pop-up window prompt request";
CM_ SG_ 828 BCM_AmbientLiAniSts "Ambient light animation state signal";
CM_ SG_ 828 BCM_ChildLockError "Child Lock Error Status";
CM_ SG_ 828 BCM_RLS_lightSWReason "RLS Light Swith Reason";
CM_ SG_ 828 BCM_FrontwinHeatingSts "windshield heating status";
CM_ SG_ 828 BCM_RearwinHeatingSts "Tailgate window heating status";
CM_ SG_ 828 BCM_WiperWashSts "Wiper Wash status";
CM_ SG_ 828 BCM_RearCameraWashingSts "Rear camera washing status";
CM_ SG_ 828 BCM_LiquidLevelAlarmSts "Liquid level alarm status";
CM_ SG_ 828 BCM_L_RearSeatHeatSts "Rear left seat heating status";
CM_ SG_ 828 BCM_R_RearSeatHeatSts "Rear right seat heating status";
CM_ SG_ 828 BCM_IPAmbientLightSts "IP ambient lamp state signal";
CM_ SG_ 828 BCM_AmbientLightBrightSts "Instrument ambient light brightness state";
CM_ SG_ 828 BCM_AmbientLightColorSts "IP ambient light color set state";
CM_ SG_ 192 Checksum_0C0 "Checksum signal for frame";
CM_ SG_ 192 MessageCounter_0C0 "Message counter signal for frame";
CM_ SG_ 192 BCM_LeftTurnLampReq "Left turn lamp request signal";
CM_ SG_ 192 BCM_RightTurnLampReq "Right turn lamp request signal";
CM_ SG_ 192 BCM_TurnLampSerialReq "Turn lamp dynamic flow";
CM_ SG_ 267 BCM_CentralLockFeedback "Feedback of the central locking or unlocking result";
CM_ SG_ 267 BCM_LVonReqKeyNotInCar "DK is not in the car when powered on";
CM_ SG_ 626 BCM_Immo_State "BCM-VCU Immobilizing state";
CM_ SG_ 626 BCM_SecOCFV_272 "Freshness value";
CM_ SG_ 626 BCM_SecOCMAC_272 "Message authentication code";
CM_ SG_ 624 BCM_ALM1_MusicFrequencySts "atmosphere light music rhythm state";
CM_ SG_ 624 BCM_ALM2_MusicFrequencySts "atmosphere light music rhythm state";
CM_ SG_ 820 BCM_AntiTheftSts "Anti-theft status";
CM_ SG_ 820 BCM_AlarmedRemind "Vehicle has experienced anti-theft alarm reminders";
CM_ SG_ 820 BCM_ImmobilizingRemind "Immobilizing Remind";
CM_ SG_ 820 BCM_SecOCFV_334 "Freshness value";
CM_ SG_ 820 BCM_SecOCMAC_334 "Message authentication code";
CM_ SG_ 934 BMS_CellNumbers "Sum of cell in pack";
CM_ SG_ 536 BMS_ThermometerProbes "Sum of Temperature Probe in PACK";
CM_ SG_ 536 BMS_AverageCellTemp "Average battery cell temperature";
CM_ SG_ 536 BMS_MaxCellTemp "Maximal Cell TemperatureInlet value";
CM_ SG_ 536 BMS_MinCellTemp "Minimal Cell TemperatureInlet value";
CM_ SG_ 536 BMS_MaxCellTempModuleNO "Maximal Cell TemperatureInlet module NO";
CM_ SG_ 536 BMS_MinCellTempModuleNO "Minimal Cell TemperatureInlet module NO";
CM_ SG_ 536 BMS_MaxCellTempNO "Maximal Cell TemperatureInlet NO";
CM_ SG_ 536 BMS_MinCellTempNO "Minimal Cell TemperatureInlet NO";
CM_ SG_ 535 BMS_MaxCellVoltage "The Maximal Cell Voltage";
CM_ SG_ 535 BMS_MinCellVoltage "The Minimal Cell Voltage";
CM_ SG_ 535 BMS_MaxCellVoltageModuleNO "Maximal Cell Voltage module NO";
CM_ SG_ 535 BMS_MinCellVoltageModlueNO "Minimal Cell Voltage module NO";
CM_ SG_ 535 BMS_MaxCellVoltageNO "The Maximal Cell Voltage NO";
CM_ SG_ 535 BMS_MinCellVoltageNO "The Minimal Cell Voltage NO";
CM_ SG_ 530 BMS_RemChagTime "Remaining charging time prediction in minute";
CM_ SG_ 530 BMS_MaxChagVoltage "Maximum allowable charging voltage";
CM_ SG_ 530 BMS_AllowChagCurrent "Maximum allowable charging current";
CM_ SG_ 531 BMS_DCChgMode "DC charging mode";
CM_ SG_ 531 BMS_AbortAchiveSingleVolt "Abort charging when reaching the set value of unit voltage";
CM_ SG_ 531 BMS_AbortAchiveTotalVolt "Stop charging when the total voltage setting is reached";
CM_ SG_ 531 BMS_AbortFaultBMSTemp "BMS over temperature suspension charging";
CM_ SG_ 531 BMS_AbortFaultBatteryTemp "Battery pack over temperature stops charging";
CM_ SG_ 531 BMS_AbortErrorCurrent "Overcurrent suspension charging";
CM_ SG_ 531 BMS_AbortAchivesetValue "Abort charging when reaching the required SOC target value";
CM_ SG_ 531 BMS_AbortErrorVoltage "Abnormal voltage suspends charging";
CM_ SG_ 531 BMS_ChagComplete "Charging completion status";
CM_ SG_ 531 BMS_ChargeRequest "BMS charging request";
CM_ SG_ 528 BMS_PosRelayStatus "State of positive relay status";
CM_ SG_ 528 BMS_PTCRelayStatus "the status of PTC relay from BMS side";
CM_ SG_ 528 BMS_NegRelayStatus "State of negtive relay status";
CM_ SG_ 528 BMS_PreRelayStatus "State of precharge relay status";
CM_ SG_ 528 BMS_PTC_VoltageValue "Voltage across Pack PTC";
CM_ SG_ 528 BMS_PTC_WorkStatus "PTC WorkStatus";
CM_ SG_ 528 BMS_PTC_WorkTime "PTC WorkTime";
CM_ SG_ 772 BMS_ErrorCellOverVolt "Cell voltage over limit";
CM_ SG_ 772 BMS_ErrorCellUnderVolt "Cell voltage under limit";
CM_ SG_ 772 BMS_ErrorCellHighTemp "Cell temperature over limit";
CM_ SG_ 772 BMS_ErrorCellLowTemp "Cell temperature under limit";
CM_ SG_ 772 BMS_ErrorBattOverVolt "Battery voltage over limit";
CM_ SG_ 772 BMS_ErrorBattUnderVolt "Battery voltage under limit";
CM_ SG_ 772 BMS_ErrorChaCurrentOver "Battery charge current over limit";
CM_ SG_ 772 BMS_ErrorDisChaCurrentOver "Battery discharge current over limit";
CM_ SG_ 772 BMS_ErrorBSUOffline "BSU offline";
CM_ SG_ 772 BMS_ErrorLeakCurrent "Leakage current exceeds the limit";
CM_ SG_ 772 BMS_ErrorCellVoltDiff "Cell‘s voltage diffrence between maximal and minimal one is over limit";
CM_ SG_ 772 BMS_ErrorCellTempDiff "Cell's temperature diffrence between maximal and minimal one is over limit";
CM_ SG_ 772 BMS_ErrorBatVolt "Battery error";
CM_ SG_ 772 BMS_ErrorHallOffline "Hall offline";
CM_ SG_ 772 BMS_ErrorCellVoltOffline "Cell voltage detector offline";
CM_ SG_ 772 BMS_ErrorCellTempOffline "Cell temperature detector offline";
CM_ SG_ 772 BMS_ErrorPreChaFailed "HV precharg failed";
CM_ SG_ 772 BMS_ErrorRelay "Relay error";
CM_ SG_ 772 BMS_ErrorBSUBalance "BSU balance fuction error";
CM_ SG_ 772 BMS_ErrorLowSoc "SOC under limit";
CM_ SG_ 772 BMS_ErrorHighSoc "SOC over limit";
CM_ SG_ 772 BMS_ErrorSoCJump_RM "SOC jump";
CM_ SG_ 772 BMS_ErrorHVIL "HVIL offline";
CM_ SG_ 772 BMS_ErrorEmergencyOffCrash "Crash signal";
CM_ SG_ 772 BMS_ErrorSystemsMatch "BMS not matched alarm";
CM_ SG_ 772 BMS_ErrorSmoke "Smoke alarm";
CM_ SG_ 772 BMS_ErrorLeakDet "Leakage detection";
CM_ SG_ 772 BMS_ThermalRunawayFault "Thermal Runaway failure";
CM_ SG_ 772 BMS_DTC "Fault code";
CM_ SG_ 933 BMS_BatProDatYear "Battery pack production date year";
CM_ SG_ 933 BMS_BatProDatMonth "Battery pack production date month";
CM_ SG_ 933 BMS_BatProDatDay "Battery pack production date day";
CM_ SG_ 992 BMS_FeedEnergySts "Accumulated actual feedback energy for this operation";
CM_ SG_ 992 BMS_DirveDiscSts "Accumulated actual discharge energy during this operation";
CM_ SG_ 193 Checksum_0C1 "Checksum signal for frame";
CM_ SG_ 193 MessageCounter_0C1 "Message counter signal for frame";
CM_ SG_ 193 BMS_ErrorIsolationSingleLow "The insulation resistance is too low.";
CM_ SG_ 193 BMS_WorkMode "State of BMS";
CM_ SG_ 193 BMS_BalancingStatus "Cell balancing status";
CM_ SG_ 193 BMS_HVinterlockState "HV interlock state";
CM_ SG_ 193 BMS_ThrmlRunawayFault "Thermal runaway fault";
CM_ SG_ 193 BMS_PreCharge "State of BMS Precharge";
CM_ SG_ 193 BMS_ChargeStatus "State of BMS Charge Mode";
CM_ SG_ 193 BMS_RunHeatStatus "State of Heat state when car running";
CM_ SG_ 193 BMS_ErrorLevel "BMS Error Level";
CM_ SG_ 193 BMS_SOH "BMS SOH";
CM_ SG_ 193 BMS_SysRegInsulationValue "BMS system insulation value";
CM_ SG_ 194 BMS_BattVolt "the voltage of dclink from BMS side";
CM_ SG_ 194 BMS_BattCurr "the current of dclink from BMS side";
CM_ SG_ 194 BMS_Heatcurrent "Heat current";
CM_ SG_ 532 BMS_PackVoltage "Pack Inside Volt";
CM_ SG_ 532 BMS_LinkVoltage "Pack Outside Volt";
CM_ SG_ 532 BMS_SOC "BMS Real SOC";
CM_ SG_ 532 BMS_DisplaySOC "BMS Display SOC";
CM_ SG_ 771 BMS_CoolCommand "Cool command from BMS";
CM_ SG_ 771 BMS_AllowCellTemperature "Maximum allowable charging temperature";
CM_ SG_ 771 BMS_TargetBatteryMaxCellTemp "Target battery cell temperature";
CM_ SG_ 771 BMS_TempInlet "Water inlet temperature";
CM_ SG_ 771 BMS_HeatCommand "Heat command from BMS";
CM_ SG_ 771 BMS_KeepWarmRequest "Keep warm request";
CM_ SG_ 771 BMS_KeepWarmStatus "Keep warm status";
CM_ SG_ 771 BMS_RTC_Request "BMS real time clock wake up request";
CM_ SG_ 771 BMS_BalanceCommand "Balance command from BMS";
CM_ SG_ 771 BMS_Tempoutlet "Outlet water temperature";
CM_ SG_ 771 BMS_FlowRate "Coolant flow rate";
CM_ SG_ 932 BMS_SoftVsesion "BMS software version";
CM_ SG_ 932 BMS_HardVsesion "BMS hardware version";
CM_ SG_ 932 BMS_ComVersion "BMS Communication Protocol Version";
CM_ SG_ 932 BMS_BatProRights "Battery property rights";
CM_ SG_ 932 BMS_Life "BMS life signal";
CM_ SG_ 257 CBM_BLE_CarSearchReq "Bluetooth remote search request";
CM_ SG_ 721 CBM_PhoneLocation "Bluetooth key location information";
CM_ SG_ 721 CBM_BlePairingSetSts "BLE pairing enable state";
CM_ SG_ 721 CBM_SecOCFV_2D1 "Freshness value";
CM_ SG_ 721 CBM_SecOCMAC_2D1 "Message authentication code";
CM_ SG_ 632 Checksum_278 "Checksum signal for frame";
CM_ SG_ 632 MessageCounter_278 "Message counter signal for frame";
CM_ SG_ 632 CGW_VehicleState "Vehicle state";
CM_ SG_ 646 DCM_ALM_FL_MusicFrequencySts "atmosphere light music rhythm state";
CM_ SG_ 646 DCM_FL_AmbientLightSts "DCM_FL ambient lamp state signal";
CM_ SG_ 646 DCM_FL_AmbientLightBrightSts "DCM_FL ambient light brightness state";
CM_ SG_ 646 DCM_FL_AmbientLightColorSts "DCM_FL ambient light color set state";
CM_ SG_ 646 DCM_FL_AmbientLiAniSts "Ambient light animation state signal";
CM_ SG_ 647 DCM_ALM_FR_MusicFrequencySts "atmosphere light music rhythm state";
CM_ SG_ 647 DCM_FR_AmbientLightSts "DCM_FR ambient lamp state signal";
CM_ SG_ 647 DCM_FR_AmbientLightBrightSts "DCM_FR ambient light brightness state";
CM_ SG_ 647 DCM_FR_AmbientLightColorSts "DCM_FR ambient light color set state";
CM_ SG_ 647 DCM_FR_AmbientLiAniSts "Ambient light animation state signal";
CM_ SG_ 648 DCM_ALM_RL_MusicFrequencySts "atmosphere light music rhythm state";
CM_ SG_ 648 DCM_RL_AmbientLightSts "DCM_RL ambient lamp state signal";
CM_ SG_ 648 DCM_RL_AmbientLightBrightSts "DCM_RL ambient light brightness state";
CM_ SG_ 648 DCM_RL_AmbientLightColorSts "DCM_RL ambient light color set state";
CM_ SG_ 648 DCM_RL_AmbientLiAniSts "Ambient light animation state signal";
CM_ SG_ 649 DCM_ALM_RR_MusicFrequencySts "atmosphere light music rhythm state";
CM_ SG_ 649 DCM_RR_AmbientLightSts "DCM_RR ambient lamp state signal";
CM_ SG_ 649 DCM_RR_AmbientLightBrightSts "DCM_RR ambient light brightness state";
CM_ SG_ 649 DCM_RR_AmbientLightColorSts "DCM_RR ambient light color set state";
CM_ SG_ 649 DCM_RR_AmbientLiAniSts "Ambient light animation state signal";
CM_ SG_ 642 DCM_FL_CarSharingColorSts "DCM_FL feedback car sharing color status";
CM_ SG_ 642 DCM_FL_CarSharingTimeSts "DCM_FL feedback car sharing welcome light runtime status";
CM_ SG_ 642 DCM_FL_PowerDoorModeSts "Status of FL Power Door Mode";
CM_ SG_ 642 DCM_FL_FrontKeepOpenSts "Status feedback of FL “keep the front door opened”";
CM_ SG_ 642 DCM_FL_PriorSoundSts "Status feedback of sound reminder prior FL door automatic via speaker";
CM_ SG_ 642 DCM_FL_DoorFLAngle "FL door angle signal";
CM_ SG_ 642 DCM_FL_DoorFLLockSts "Left front door lock status";
CM_ SG_ 642 DCM_FL_LinkageAvoidanceReq "FLdoor linkage avoidance";
CM_ SG_ 642 DCM_FL_ElectricDoorMovementSts "FL Electric door movement status";
CM_ SG_ 642 DCM_FL_DoorAntiPinchSts "Left front door anti pinch status";
CM_ SG_ 642 DCM_FL_DoorObstacleSts "Left front door obstacle avoidance status";
CM_ SG_ 642 DCM_FL_FLPESwitchReq "Front left exterior door handle PE switch status";
CM_ SG_ 642 DCM_FL_PWM_POS_STS "Driver window position status";
CM_ SG_ 642 DCM_FL_WindowSts "Left front window status";
CM_ SG_ 642 DCM_FL_InsideSwitchReq "Driver's door open switch operation";
CM_ SG_ 642 DCM_FL_FrontDoorAngleFeedback "Feedback value for rear door angle setting";
CM_ SG_ 642 DCM_FL_GLASS_LOCATION "Left front window percentage position";
CM_ SG_ 642 DCM_FL_CarSharingLightSts "DCM_FL feedback car sharing light stauts";
CM_ SG_ 642 DCM_FL_WelcomeOnOffSts "DCM_FL feedback automatically activate the welcome light stauts";
CM_ SG_ 650 Checksum_28A "Checksum signal for frame";
CM_ SG_ 650 MessageCounter_28A "Message counter signal for frame";
CM_ SG_ 650 DCM_FL_DoorFLSts "Driver's door status";
CM_ SG_ 650 DCM_FL_FRWndSwA "Front right window enabled";
CM_ SG_ 650 DCM_FL_RLWndSwA "Rear left window enabled";
CM_ SG_ 650 DCM_FL_RRWndSwA "Rear right window enabled";
CM_ SG_ 650 DCM_FL_PowerDoorErrorSts "FL Power Door error status";
CM_ SG_ 650 DCM_FL_LeftMirrorHorizontalPos "Left and right position of left rearview mirror (percentage)";
CM_ SG_ 650 DCM_FL_LeftMirrorVerticalPos "Up and down positions of the left rearview mirror (percentage)";
CM_ SG_ 650 DCM_FL_MirrorAutoTurnDownSts "Left exterior mirror automatic flip down enable status feedback";
CM_ SG_ 650 DCM_FL_MirrorAutoFoldUnfoldSts "Left exterior mirror automatic folding and unfolding setting status";
CM_ SG_ 650 DCM_FL_RearmirrorHeatingSts "Left rear mirror heat status";
CM_ SG_ 650 DCM_FL_MirrorFold_UnfoldSts "Mirror folding or unfolding status signal";
CM_ SG_ 652 DCM_FL_MirrorTiltVerticalPos "Locally stored left exterior mirror vertical position in tilt mode";
CM_ SG_ 652 DCM_FL_MirrorTiltHorizontalPos "Locally stored left exterior mirror horizontal position in tilt mode";
CM_ SG_ 652 DCM_FL_MirrorMainVerticalPos "Locally stored left exterior mirror vertical position in main mode";
CM_ SG_ 652 DCM_FL_MirrorMainHorizontalPos "Locally stored left exterior mirror horizontal position in main mode";
CM_ SG_ 309 DCM_FL_MirrorAdjustmentSts "Left exterior mirror adjustment failure status";
CM_ SG_ 309 DCM_FL_MirrorFoldFaultSts "Left exterior mirror folding and unfolding failure status";
CM_ SG_ 309 DCM_FL_HandleFailReminder "Reminder of FL Hidden Hnadle Fnfolding";
CM_ SG_ 309 DCM_FL_PriorSoundReq "Require of sound reminder prior FL door automatic via speaker";

BA_DEF_  "DBName" STRING ;
BA_DEF_  "BusType" STRING ;
BA_DEF_  "NmMessageCount" INT 0 255;
BA_DEF_ BU_  "NmNode" ENUM  "no","yes";
BA_DEF_ BO_  "GenMsgSendType" ENUM  "Cyclic","Event","IfActive","CE","CA","NoMsgSendType";
BA_DEF_ BO_  "GenMsgCycleTime" INT 0 0;
BA_DEF_ BO_  "GenMsgCycleTimeFast" INT 0 0;
BA_DEF_ BO_  "CANFD_BRS" ENUM  "0","1";
BA_DEF_ BO_  "GenMsgNrOfRepetition" INT 0 0;
BA_DEF_ BO_  "GenMsgDelayTime" INT 0 0;
BA_DEF_ BO_  "GenMsgILSupport" ENUM  "No","Yes";
BA_DEF_ BO_  "NmMessage" ENUM "No","Yes";
BA_DEF_ BO_  "DiagState" ENUM  "No","Yes";
BA_DEF_ BO_  "DiagRequest" ENUM  "No","Yes";
BA_DEF_ BO_  "DiagResponse" ENUM  "No","Yes";
BA_DEF_ BO_  "VFrameFormat" ENUM  "StandardCAN","ExtendedCAN","reserved","reserved","reserved","reserved","reserved","reserved","reserved","reserved","reserved","reserved","reserved","reserved","StandardCAN_FD","ExtendedCAN_FD";
BA_DEF_ SG_  "GenSigSendType" ENUM  "Cyclic","OnChange","OnWrite","IfActive","OnChangeWithRepetition","OnWriteWithRepetition","IfActiveWithRepetition","NoSigSendType","NotUsed","NotUsed","NotUsed","NotUsed","NotUsed";
BA_DEF_ SG_  "GenSigStartValue" INT 0 0;
BA_DEF_ SG_  "GenSigInvalidValue" INT 0 0;
BA_DEF_DEF_  "GenMsgSendType" "Cyclic";
BA_DEF_DEF_  "GenMsgCycleTime" 0;
BA_DEF_DEF_  "GenSigSendType" "Cyclic";
BA_DEF_DEF_  "GenSigStartValue" 0;
BA_DEF_DEF_  "GenSigInvalidValue" 0;
BA_DEF_DEF_  "GenMsgCycleTimeFast" 0;
BA_DEF_DEF_  "GenMsgNrOfRepetition" 0;
BA_DEF_DEF_  "GenMsgDelayTime" 0;
BA_DEF_DEF_  "CANFD_BRS" "1";
BA_DEF_DEF_  "DBName" "";
BA_DEF_DEF_  "BusType" "";
BA_DEF_DEF_  "NmNode" "no";
BA_DEF_DEF_  "NmMessageCount" 255;
BA_DEF_DEF_  "GenMsgILSupport" "Yes";
BA_DEF_DEF_  "NmMessage" "No";
BA_DEF_DEF_  "DiagState" "No";
BA_DEF_DEF_  "DiagRequest" "No";
BA_DEF_DEF_  "DiagResponse" "No";
BA_DEF_DEF_  "VFrameFormat" "StandardCAN_FD";
BA_ "DBName" "ATOM_CANFD_Matrix_SGW-CGW_V5.0.0_20250123_SGW_SG";
BA_ "BusType" "CAN FD";
BA_ "NmNode" BU_ SGW_SG 1;BA_ "NmNode" BU_ CGW_SG 1;BA_ "GenMsgCycleTime" BO_ 245 20;
BA_ "GenSigInvalidValue" SG_ 245 MessageCounter_0F5 15;
BA_ "GenSigStartValue" SG_ 245 ACU_YawRate 30000;
BA_ "GenSigInvalidValue" SG_ 245 ACU_YawRate 65535;
BA_ "GenMsgCycleTime" BO_ 246 20;
BA_ "GenSigInvalidValue" SG_ 246 MessageCounter_0F6 15;
BA_ "GenSigStartValue" SG_ 246 ACU_LatA 4905;
BA_ "GenSigInvalidValue" SG_ 246 ACU_LatA 16383;
BA_ "GenSigStartValue" SG_ 246 ACU_LgtA 4905;
BA_ "GenSigInvalidValue" SG_ 246 ACU_LgtA 16383;
BA_ "GenMsgCycleTime" BO_ 151 20;
BA_ "GenSigInvalidValue" SG_ 151 MessageCounter_097 15;
BA_ "GenSigStartValue" SG_ 151 ACU_CrashOutputStsValid 1;
BA_ "GenMsgCycleTime" BO_ 225 20;
BA_ "GenSigInvalidValue" SG_ 225 MessageCounter_0E1 15;
BA_ "GenSigStartValue" SG_ 225 ADCU_ACC_JERK_Lower_Limit 127;
BA_ "GenMsgCycleTime" BO_ 224 20;
BA_ "GenSigInvalidValue" SG_ 224 MessageCounter_0E0 15;
BA_ "GenSigInvalidValue" SG_ 224 ADCU_ACC_Mode 11;
BA_ "GenSigInvalidValue" SG_ 224 ADCU_DA_Mode 14;
BA_ "GenMsgCycleTime" BO_ 226 20;
BA_ "GenSigInvalidValue" SG_ 226 MessageCounter_0E2 15;
BA_ "GenMsgCycleTime" BO_ 228 20;
BA_ "GenSigInvalidValue" SG_ 228 MessageCounter_0E4 15;
BA_ "GenSigInvalidValue" SG_ 228 ADCU_APSDistanceStop 4095;
BA_ "GenSigInvalidValue" SG_ 228 ADCU_APSMaxSpeedReq 31;
BA_ "GenMsgCycleTime" BO_ 522 100;
BA_ "GenSigInvalidValue" SG_ 522 MessageCounter_20A 15;
BA_ "GenMsgCycleTime" BO_ 232 20;
BA_ "GenSigInvalidValue" SG_ 232 MessageCounter_0E8 15;
BA_ "GenSigInvalidValue" SG_ 232 ADCU_APSEPSControlReq 3;
BA_ "GenSigStartValue" SG_ 232 ADCU_EPSSteerAngTarValReq 65534;
BA_ "GenSigInvalidValue" SG_ 232 ADCU_EPSSteerAngTarValReq 65535;
BA_ "GenSigStartValue" SG_ 232 ADCU_EPSSteerAngSpdReq 254;
BA_ "GenSigInvalidValue" SG_ 232 ADCU_EPSSteerAngSpdReq 255;
BA_ "GenMsgCycleTime" BO_ 515 100;
BA_ "GenMsgCycleTime" BO_ 613 100;
BA_ "GenMsgCycleTime" BO_ 784 200;
BA_ "GenSigStartValue" SG_ 784 AVAS_SoundEnableSts 1;
BA_ "GenMsgCycleTime" BO_ 822 200;
BA_ "GenSigInvalidValue" SG_ 822 BCM_RLHSHumidSensorValue 255;
BA_ "GenSigInvalidValue" SG_ 822 BCM_RLHSTempSensorValue 255;
BA_ "GenSigInvalidValue" SG_ 822 BCM_RLHSTempDewPoint 2047;
BA_ "GenSigStartValue" SG_ 822 BCM_HUDBriRawVal 127;
BA_ "GenSigInvalidValue" SG_ 822 BCM_HUDBriRawVal 127;
BA_ "GenMsgCycleTime" BO_ 823 200;
BA_ "GenSigStartValue" SG_ 823 BCM_WelLightshowTimeSts 11;
BA_ "GenSigStartValue" SG_ 823 BCM_TaxiArrIllSts 2;
BA_ "GenSigStartValue" SG_ 823 BCM_FollowMeHomeTimeSts 11;
BA_ "GenSigStartValue" SG_ 823 BCM_CornerLampSetSts 1;
BA_ "GenSigStartValue" SG_ 823 BCM_CarSharingTimeSts 4;
BA_ "GenSigStartValue" SG_ 823 BCM_CarSharingColorSts 31;
BA_ "GenMsgCycleTime" BO_ 824 200;
BA_ "GenSigInvalidValue" SG_ 824 MessageCounter_338 15;
BA_ "GenSigStartValue" SG_ 824 BCM_DRLReq 1;
BA_ "GenSigStartValue" SG_ 824 BCM_FollowMeHomeSts 1;
BA_ "GenSigStartValue" SG_ 824 BCM_LeCornrgLiReq 1;
BA_ "GenSigStartValue" SG_ 824 BCM_MainBeamReq 1;
BA_ "GenSigStartValue" SG_ 824 BCM_DippedBeamReq 1;
BA_ "GenSigStartValue" SG_ 824 BCM_RiCornrgLiReq 1;
BA_ "GenSigStartValue" SG_ 824 BCM_RLS_AutoLampSenSts 1;
BA_ "GenSigStartValue" SG_ 824 BCM_HeightSetSts 1;
BA_ "GenSigStartValue" SG_ 824 BCM_PosLampReq 1;
BA_ "GenSigStartValue" SG_ 824 BCM_FrontFogLampReq 1;
BA_ "GenMsgSendType" BO_ 825 3;
BA_ "GenMsgCycleTime" BO_ 825 200;
BA_ "GenMsgCycleTimeFast" BO_ 825 20;
BA_ "GenMsgNrOfRepetition" BO_ 825 3;
BA_ "GenMsgDelayTime" BO_ 825 20;
BA_ "GenSigInvalidValue" SG_ 825 MessageCounter_339 15;
BA_ "GenSigSendType" SG_ 825 BCM_GlassUnclsWarnCtrlRqst 4;
BA_ "GenSigStartValue" SG_ 825 BCM_RelockSts 1;
BA_ "GenSigSendType" SG_ 825 BCM_WinClsReq 4;
BA_ "GenMsgCycleTime" BO_ 826 200;
BA_ "GenSigInvalidValue" SG_ 826 MessageCounter_33A 15;
BA_ "GenSigStartValue" SG_ 826 BCM_GearTimesSts 5;
BA_ "GenSigStartValue" SG_ 826 BCM_DomeLampBrightSts 1;
BA_ "GenSigStartValue" SG_ 826 BCM_PuddleLiReq 1;
BA_ "GenSigStartValue" SG_ 826 BCM_DomeLampAutoSts 1;
BA_ "GenSigStartValue" SG_ 826 BCM_WelLightshowOnOffSts 2;
BA_ "GenMsgCycleTime" BO_ 625 100;
BA_ "GenSigInvalidValue" SG_ 625 MessageCounter_271 15;
BA_ "GenSigInvalidValue" SG_ 625 BCM_PepsPowerMode 7;
BA_ "GenMsgCycleTime" BO_ 828 200;
BA_ "GenSigStartValue" SG_ 828 BCM_AmbientLiAniSts 1;
BA_ "GenSigStartValue" SG_ 828 BCM_AmbientLightBrightSts 5;
BA_ "GenSigStartValue" SG_ 828 BCM_AmbientLightColorSts 32;
BA_ "GenMsgCycleTime" BO_ 192 20;
BA_ "GenSigInvalidValue" SG_ 192 MessageCounter_0C0 15;
BA_ "GenMsgSendType" BO_ 267 1;
BA_ "GenMsgCycleTimeFast" BO_ 267 20;
BA_ "GenMsgNrOfRepetition" BO_ 267 3;
BA_ "GenMsgDelayTime" BO_ 267 20;
BA_ "GenSigSendType" SG_ 267 BCM_CentralLockFeedback 4;
BA_ "GenSigSendType" SG_ 267 BCM_LVonReqKeyNotInCar 4;
BA_ "GenMsgCycleTime" BO_ 626 100;
BA_ "GenMsgCycleTime" BO_ 624 100;
BA_ "GenMsgCycleTime" BO_ 820 200;
BA_ "GenMsgCycleTime" BO_ 934 1000;
BA_ "GenMsgCycleTime" BO_ 536 100;
BA_ "GenSigStartValue" SG_ 536 BMS_AverageCellTemp 255;
BA_ "GenSigStartValue" SG_ 536 BMS_MaxCellTemp 255;
BA_ "GenSigStartValue" SG_ 536 BMS_MinCellTemp 255;
BA_ "GenMsgCycleTime" BO_ 535 100;
BA_ "GenMsgCycleTime" BO_ 530 100;
BA_ "GenMsgCycleTime" BO_ 531 100;
BA_ "GenMsgCycleTime" BO_ 528 100;
BA_ "GenSigInvalidValue" SG_ 528 BMS_PosRelayStatus 3;
BA_ "GenSigInvalidValue" SG_ 528 BMS_PTCRelayStatus 3;
BA_ "GenSigInvalidValue" SG_ 528 BMS_NegRelayStatus 3;
BA_ "GenSigInvalidValue" SG_ 528 BMS_PreRelayStatus 3;
BA_ "GenSigStartValue" SG_ 528 BMS_PTC_WorkStatus 1;
BA_ "GenMsgCycleTime" BO_ 772 200;
BA_ "GenMsgCycleTime" BO_ 933 1000;
BA_ "GenMsgCycleTime" BO_ 992 500;
BA_ "GenSigStartValue" SG_ 992 BMS_FeedEnergySts 255;
BA_ "GenSigStartValue" SG_ 992 BMS_DirveDiscSts 255;
BA_ "GenMsgCycleTime" BO_ 193 20;
BA_ "GenSigInvalidValue" SG_ 193 MessageCounter_0C1 15;
BA_ "GenSigInvalidValue" SG_ 193 BMS_WorkMode 7;
BA_ "GenMsgCycleTime" BO_ 194 20;
BA_ "GenMsgCycleTime" BO_ 532 100;
BA_ "GenMsgCycleTime" BO_ 771 200;
BA_ "GenSigStartValue" SG_ 771 BMS_AllowCellTemperature 255;
BA_ "GenSigStartValue" SG_ 771 BMS_TargetBatteryMaxCellTemp 255;
BA_ "GenSigStartValue" SG_ 771 BMS_TempInlet 255;
BA_ "GenSigStartValue" SG_ 771 BMS_Tempoutlet 255;
BA_ "GenSigStartValue" SG_ 771 BMS_FlowRate 255;
BA_ "GenMsgCycleTime" BO_ 932 1000;
BA_ "GenMsgSendType" BO_ 257 3;
BA_ "GenMsgCycleTime" BO_ 257 200;
BA_ "GenMsgCycleTimeFast" BO_ 257 20;
BA_ "GenMsgNrOfRepetition" BO_ 257 3;
BA_ "GenMsgDelayTime" BO_ 257 20;
BA_ "GenSigSendType" SG_ 257 CBM_BLE_CarSearchReq 4;
BA_ "GenMsgCycleTime" BO_ 721 100;
BA_ "GenMsgCycleTime" BO_ 632 100;
BA_ "GenSigInvalidValue" SG_ 632 MessageCounter_278 15;
BA_ "GenMsgCycleTime" BO_ 646 100;
BA_ "GenSigStartValue" SG_ 646 DCM_FL_AmbientLightBrightSts 5;
BA_ "GenSigStartValue" SG_ 646 DCM_FL_AmbientLightColorSts 32;
BA_ "GenSigStartValue" SG_ 646 DCM_FL_AmbientLiAniSts 1;
BA_ "GenMsgCycleTime" BO_ 647 100;
BA_ "GenSigStartValue" SG_ 647 DCM_FR_AmbientLightBrightSts 5;
BA_ "GenSigStartValue" SG_ 647 DCM_FR_AmbientLightColorSts 32;
BA_ "GenSigStartValue" SG_ 647 DCM_FR_AmbientLiAniSts 1;
BA_ "GenMsgCycleTime" BO_ 648 100;
BA_ "GenSigStartValue" SG_ 648 DCM_RL_AmbientLightBrightSts 5;
BA_ "GenSigStartValue" SG_ 648 DCM_RL_AmbientLightColorSts 32;
BA_ "GenSigStartValue" SG_ 648 DCM_RL_AmbientLiAniSts 1;
BA_ "GenMsgCycleTime" BO_ 649 100;
BA_ "GenSigStartValue" SG_ 649 DCM_RR_AmbientLightBrightSts 5;
BA_ "GenSigStartValue" SG_ 649 DCM_RR_AmbientLightColorSts 32;
BA_ "GenSigStartValue" SG_ 649 DCM_RR_AmbientLiAniSts 1;
BA_ "GenMsgSendType" BO_ 642 3;
BA_ "GenMsgCycleTime" BO_ 642 100;
BA_ "GenMsgCycleTimeFast" BO_ 642 20;
BA_ "GenMsgNrOfRepetition" BO_ 642 3;
BA_ "GenMsgDelayTime" BO_ 642 20;
BA_ "GenSigStartValue" SG_ 642 DCM_FL_CarSharingColorSts 31;
BA_ "GenSigStartValue" SG_ 642 DCM_FL_CarSharingTimeSts 4;
BA_ "GenSigStartValue" SG_ 642 DCM_FL_DoorFLAngle 127;
BA_ "GenSigInvalidValue" SG_ 642 DCM_FL_DoorFLAngle 127;
BA_ "GenSigSendType" SG_ 642 DCM_FL_LinkageAvoidanceReq 4;
BA_ "GenMsgCycleTime" BO_ 650 100;
BA_ "GenSigInvalidValue" SG_ 650 MessageCounter_28A 15;
BA_ "GenSigInvalidValue" SG_ 650 DCM_FL_FRWndSwA 5;
BA_ "GenSigInvalidValue" SG_ 650 DCM_FL_RLWndSwA 5;
BA_ "GenSigInvalidValue" SG_ 650 DCM_FL_RRWndSwA 5;
BA_ "GenSigStartValue" SG_ 650 DCM_FL_LeftMirrorHorizontalPos 254;
BA_ "GenSigInvalidValue" SG_ 650 DCM_FL_LeftMirrorHorizontalPos 255;
BA_ "GenSigStartValue" SG_ 650 DCM_FL_LeftMirrorVerticalPos 254;
BA_ "GenSigInvalidValue" SG_ 650 DCM_FL_LeftMirrorVerticalPos 255;
BA_ "GenMsgCycleTime" BO_ 652 100;
BA_ "GenSigStartValue" SG_ 652 DCM_FL_MirrorTiltVerticalPos 254;
BA_ "GenSigInvalidValue" SG_ 652 DCM_FL_MirrorTiltVerticalPos 255;
BA_ "GenSigStartValue" SG_ 652 DCM_FL_MirrorTiltHorizontalPos 254;
BA_ "GenSigInvalidValue" SG_ 652 DCM_FL_MirrorTiltHorizontalPos 255;
BA_ "GenSigStartValue" SG_ 652 DCM_FL_MirrorMainVerticalPos 254;
BA_ "GenSigInvalidValue" SG_ 652 DCM_FL_MirrorMainVerticalPos 255;
BA_ "GenSigStartValue" SG_ 652 DCM_FL_MirrorMainHorizontalPos 254;
BA_ "GenSigInvalidValue" SG_ 652 DCM_FL_MirrorMainHorizontalPos 255;
BA_ "GenMsgSendType" BO_ 309 1;
BA_ "GenSigSendType" SG_ 309 DCM_FL_MirrorAdjustmentSts 4;
BA_ "GenSigSendType" SG_ 309 DCM_FL_MirrorFoldFaultSts 4;
BA_ "GenSigSendType" SG_ 309 DCM_FL_HandleFailReminder 4;
BA_ "GenSigSendType" SG_ 309 DCM_FL_PriorSoundReq 4;

VAL_ 245 MessageCounter_0F5 15 "Invalid" ;
VAL_ 245 ACU_YawRate 65535 "Invalid";
VAL_ 245 ACU_YawRateStatus 0 "Invalid" 1 "Valid" 2 "Reserved" 3 "Reserved" ;
VAL_ 246 MessageCounter_0F6 15 "Invalid" ;
VAL_ 246 ACU_LatA 16383 "Invalid";
VAL_ 246 ACU_LatAStatus 0 "Invalid" 1 "Valid" 2 "Reserved" 3 "Reserved" ;
VAL_ 246 ACU_LgtA 16383 "Invalid";
VAL_ 246 ACU_LgtAStatus 0 "Invalid" 1 "Valid" 2 "Reserved" 3 "Reserved" ;
VAL_ 151 MessageCounter_097 15 "Invalid" ;
VAL_ 151 ACU_CrashOutputSts 0 "No Crash" 1 "Rollover" 2 "BPT Crash" 3 "Rollover + BPT" 4 "Front Crash" 5 "Rollover + Front" 6 "BPT+Front" 7 "Rollover+BPT+Front" 8 "Side Crash" 9 "Rollover+Side" 10 "BPT+Side" 11 "Rollover+BPT+Side" 12 "Front+Side" 13 "Rollover+Front+Side" 14 "BPT+Front+Side" 15 "Rollover+BPT+Front+Side" 16 "Rear Crash" 17 "Rollover+Rear" 18 "BPT+Rear" 19 "Rollover+BPT+Rear" 20 "Front+Rear" 21 "Rollover+Front+Rear" 22 "BPT+Front+Rear" 23 "Rollover+BPT+Front+Rear" 24 "Side+Rear" 25 "Rollover+Side+Rear" 26 "BPT+Side+Rear" 27 "Rollover+BPT+Side+Rear" 28 "Front+Side+Rear" 29 "Rollover+Front+Side+Rear" 30 "BPT+Front+Side+Rear" 31 "Rollover+BPT+Front+Side+Rear" ;
VAL_ 151 ACU_CrashOutputStsValid 0 "INVALID" 1 "VALID" ;
VAL_ 151 ACU_DriverSeatBeltSts 0 "UNTIED" 1 "TIED" ;
VAL_ 151 ACU_DriverSeatBeltStsValid 0 "INVALID" 1 "VALID" ;
VAL_ 151 ACU_PassengerSeatBeltSts 0 "UNTIED" 1 "TIED" ;
VAL_ 151 ACU_PassengerSeatBeltStsValid 0 "INVALID" 1 "VALID" ;
VAL_ 151 ACU_PassengerSts 0 "UNOCCUPIED" 1 "OCCUPIED" ;
VAL_ 151 ACU_SecondLeftSeatBeltSts 0 "UNTIED" 1 "TIED" ;
VAL_ 151 ACU_RLSeatBeltStatusValid 0 "INVALID" 1 "VALID" ;
VAL_ 151 ACU_SecondLeftSts 0 "UNOCCUPIED" 1 "OCCUPIED" ;
VAL_ 151 ACU_SecondRightSeatBeltSts 0 "UNTIED" 1 "TIED" ;
VAL_ 151 ACU_RRSeatBeltStatusValid 0 "INVALID" 1 "VALID" ;
VAL_ 151 ACU_SecondRightSts 0 "UNOCCUPIED" 1 "OCCUPIED" ;
VAL_ 151 ACU_PassengerAirbagSts 0 "RESERVED" 1 "Disabled" 2 "Enabled" 3 "RESERVED" ;
VAL_ 151 ACU_DriverWarningLampSts 0 "OFF" 1 "ON" 2 "FLASH" ;
VAL_ 151 ACU_PassengerWarningLampSts 0 "OFF" 1 "ON" 2 "FLASH" ;
VAL_ 151 ACU_WarningLampSts 0 "OFF" 1 "ON" 2 "FLASH" ;
VAL_ 225 MessageCounter_0E1 15 "Invalid" ;
VAL_ 225 ADCU_ACC_StandstillReq 0 "NO_DEMAND" 1 "DEMAND" ;
VAL_ 225 ADCU_ACC_DriveOff 0 "NO_DEMAND" 1 "DEMAND" ;
VAL_ 224 MessageCounter_0E0 15 "Invalid" ;
VAL_ 224 ADCU_ACCDA_SYS_Failure 0 "No Error" 1 "Error" 2 "Reserved" 3 "Reserved" ;
VAL_ 224 ADCU_ACCDA_HandsOFF_Warning 0 "No Warning" 1 "Hands Off 1st Warning" 2 "Hands Off 2nd Warning" 3 "Function Automatic exit Warning" 4 "Reserved" 5 "Reserved" 6 "Reserved" 7 "Reserved" ;
VAL_ 224 ADCU_ACC_Mode 0 "Off" 1 "Init" 2 "Standby-Inhibit" 3 "Standby-Available" 4 "Reject" 5 "Error" 6 "Override" 7 "ACTIVE_CONTROL" 8 "STAND_ACTIVE" 9 "STAND_WAIT" 10 "BRAKE_ONLY" 11 "Invalid" ;
VAL_ 224 ADCU_DA_Mode 0 "Off" 1 "Init" 2 "Standby-Inhibit" 3 "Standby-Available" 4 "Reject" 5 "Error" 6 "ACC-Active" 7 "Override-Longitudinal" 8 "Override-Lateral" 9 "DA-ACTIVE_CONTROL" 10 "DA-STAND_ACTIVE" 11 "DA-STAND_WAIT" 12 "Slow-Exit" 13 "ESA" 14 "Invalid" ;
VAL_ 226 MessageCounter_0E2 15 "Invalid" ;
VAL_ 226 ADCU_AEBReq 0 "No active" 1 "active" ;
VAL_ 226 ADCU_FCW_State 0 "Off" 1 "Standby" 2 "Active" 3 "Failure" ;
VAL_ 226 ADCU_AEB_State 0 "Off" 1 "Standby" 2 "Active" 3 "Failure" ;
VAL_ 226 ADCU_AEB_AWB_Level 0 "No level" 1 "Level 1" 2 "Level 2" 3 "Level 3" 4 "Reserved" 5 "Reserved" ;
VAL_ 226 ADCU_AEB_AWB_Req 0 "No Request" 1 "Request" ;
VAL_ 226 ADCU_AEB_Stop_Req 0 "No request" 1 "Stop control is required" ;
VAL_ 226 ADCU_AEB_Prefill_CMD 0 "No pre-fill" 1 "Pre-fill act" ;
VAL_ 226 ADCU_AEBWarningSts 0 "NO_WARNING" 1 "PreWarning to car" 2 "Latent distance Warning" 3 "Braking  to car" 4 "PreWarning to PED" 5 "Braking  to PED" 6 "Reserved" 7 "Reserved" ;
VAL_ 228 MessageCounter_0E4 15 "Invalid" ;
VAL_ 228 ADCU_APSCrlModeReq 0 "No Request" 1 "APS" 2 "RC" 3 "Invalid" ;
VAL_ 228 ADCU_APSCrlTypReq 0 "No Request" 1 "Comfort" 2 "Emergency" 3 "Invalid" ;
VAL_ 228 ADCU_APSCrlReq 0 "No Request" 1 "Req_Drive" 2 "Req_LSM" 3 "Invalid" ;
VAL_ 228 ADCU_APSDistanceStop 4095 "Invalid" ;
VAL_ 228 ADCU_TargetGear 0 "No Request" 1 "P" 2 "N" 3 "R" 4 "D" ;
VAL_ 228 ADCU_Parking_CtrlSts 0 "OFF" 1 "ON" 2 "Failure" 3 "Reserved" ;
VAL_ 228 ADCU_APSMaxSpeedReq 31 "Invalid";
VAL_ 228 ADCU_APSComfBrkReq 0 "ComfBrakeReq_NoReq" 1 "ComfBrakeReq_Type1" 2 "ComfBrakeReq_Type2" ;
VAL_ 228 ADCU_Parking_Mode 0 "Off" 1 "Standby" 2 "Background searching" 3 "Searching" 4 "Guidance active" 5 "Recovery interrupt" 6 "Completed" 7 "Failure" 8 "Terminated" 9 "Reserved" 10 "Reserved" 11 "Reserved" 12 "Reserved" 13 "Reserved" 14 "Reserved" 15 "Reserved" ;
VAL_ 522 MessageCounter_20A 15 "Invalid" ;
VAL_ 522 ADCU_LftlndSta 0 "Indicator warning off" 1 "Indicator 1st step warning on" 2 "Indicator 2nd step warning on (blinking)" 3 "Reserved" ;
VAL_ 522 ADCU_RtlndSta 0 "Indicator warning off" 1 "Indicator 1st step warning on" 2 "Indicator 2nd step warning on (blinking)" 3 "Reserved" ;
VAL_ 522 ADCU_HazardLampReq 0 "No Request" 1 "Request Hazard lamp on" ;
VAL_ 522 ADCU_AHB_MaBeam_Req 0 "No request" 1 "Request" ;
VAL_ 232 MessageCounter_0E8 15 "Invalid" ;
VAL_ 232 ADCU_APSEPSControlReq 0 "No request" 1 "Request EPS control" 2 "EPS control active" 3 "Invalid" ;
VAL_ 232 ADCU_LatCtrlFaultSts 0 "No Fault" 1 "Fault" 2 "Reserved" 3 "Reserved" ;
VAL_ 232 ADCU_LCAEPSControlAct 0 "Deactivate" 1 "Activate" 2 "Reserved" 3 "Reserved" ;
VAL_ 232 ADCU_EPSSteerAngTarValReq 65535 "Invalid" ;
VAL_ 232 ADCU_EPSSteerAngSpdReq 255 "Invalid";
VAL_ 515 ADCU_LDW_SYS_Sts 0 "Off" 1 "Standby" 2 "Active" 3 "Warning" 4 "Failure" 5 "Reserved" 6 "Reserved" 7 "Reserved" ;
VAL_ 613 APTC_HVPowerUpReq 0 "APTC OK" 1 "APTC failure" ;
VAL_ 613 APTC_HeatingFaltStatus 0 "no error" 1 "error" ;
VAL_ 613 APTC_DriveFaltStatus 0 "no error" 1 "error" ;
VAL_ 613 APTC_LostCommuFaltStatus 0 "no error" 1 "TCU signal losted" ;
VAL_ 613 APTC_IGBTFaltStatus 0 "no error" 1 "IGBT1 SHORT" 2 "IGBT2 SHORT" 3 "BOTH SHORT" ;
VAL_ 613 APTC_Core1TempSensorFaltStatus 0 "no error" 1 "L sensor open" 2 "sensor short" 3 "overheating" ;
VAL_ 613 APTC_OverCurrentFault 0 "No Error" 1 "Error" ;
VAL_ 613 APTC_LowVoltageStatus 0 "Low Voltage Normal" 1 "Low Voltage Under" 2 "Low Voltage Over" 3 "Reserve" ;
VAL_ 613 APTC_HighVoltageStatus 0 "High Voltage Normal" 1 "High Voltage Under" 2 "High Voltage Over" ;
VAL_ 613 APTC_OverLoadStatus 0 "No Error" 1 "Left APTC OverLoad" 2 "Right APTC Overload" 3 "Both APTC Overload" ;
VAL_ 613 APTC_IGBTTempSensorStatus 0 "No Error" 1 "IGBT Temp Sensor Short" 2 "IGBT Temp Sensor OverTemp" 3 "IGBT Temp Sensor Open" ;
VAL_ 613 APTC_PCBTempSensorStatus 0 "No Error" 1 "PCB Temp Sensor Short" 2 "PCB Temp Sensor OverTemp" 3 "PCB Temp Sensor Open" ;
VAL_ 613 APTC_Core2TempSensorFaltStatus 0 "no error" 1 "R sensor open" 2 "sensor short" 3 "overheating" ;
VAL_ 784 AVAS_SoundEnableSts 0 "Disabled" 1 "Enabled" ;
VAL_ 784 AVAS_ErrorIDentification 0 "NO_ERROR" 1 "ERROR" ;
VAL_ 784 AVAS_ShowCurrSoundSts 0 "Sound1" 1 "Sound2" 2 "Sound3" 3 "Sound4" 4 "Sound5" 5 "Reserve" 6 "Reserve" 7 "Reserve" 8 "Reserve" ;
VAL_ 822 BCM_RLHSHumidSensorValue 255 "Invalid";
VAL_ 822 BCM_RLHSTempSensorValue 255 "Invalid";
VAL_ 822 BCM_RLHSTempDewPoint 2047 "Invalid";
VAL_ 822 BCM_HUDBriUnit 0 "1 lux" 1 "10 lux" 2 "100 lux" 3 "1000 lux" ;
VAL_ 822 BCM_HUDBriRawVal 127 "Invalid";
VAL_ 823 BCM_WelLightshowTimeSts 0 "Invalid";
VAL_ 823 BCM_TaxiArrIllSts 0 "OFF" 1 "ON" 2 "AUTO" ;
VAL_ 823 BCM_FollowMeHomeTimeSts 0 "Invalid";
VAL_ 823 BCM_CarSearchSts 0 "OFF" 1 "ON" ;
VAL_ 823 BCM_CornerLampSetSts 0 "Off" 1 "On" ;
VAL_ 823 BCM_WasherExtraWipeSts 0 "Disable" 1 "Enable" ;
VAL_ 823 BCM_WelcomeOnOffSts 0 "Disable" 1 "Enable" ;
VAL_ 823 BCM_CarSharingTimeSts 0 "1" 1 "2" 2 "3" 3 "4" 4 "5" 5 "6" 6 "7" 7 "8" 8 "9" 9 "10" ;
VAL_ 823 BCM_CarSharingColorSts 0 "Colour1" 1 "Colour2" 2 "Colour3" 3 "Colour4" 4 "Colour5" 5 "Colour6" 6 "Colour7" 7 "Colour8" 8 "Colour9" 9 "Colour10" 10 "Colour11" 11 "Colour12" 12 "Colour13" 13 "Colour14" 14 "Colour15" 15 "Colour16" 16 "Colour17" 17 "Colour18" 18 "Colour19" 19 "Colour20" 20 "Colour21" 21 "Colour22" 22 "Colour23" 23 "Colour24" 24 "Colour25" 25 "Colour26" 26 "Colour27" 27 "Colour28" 28 "Colour29" 29 "Colour30" 30 "Colour31" 31 "Colour32" 32 "Colour33" 33 "Colour34" 34 "Colour35" 35 "Colour36" 36 "Colour37" 37 "Colour38" 38 "Colour39" 39 "Colour40" 40 "Colour41" 41 "Colour42" 42 "Colour43" 43 "Colour44" 44 "Colour45" 45 "Colour46" 46 "Colour47" 47 "Colour48" 48 "Colour49" 49 "Colour50" 50 "Colour51" 51 "Colour52" 52 "Colour53" 53 "Colour54" 54 "Colour55" 55 "Colour56" 56 "Colour57" 57 "Colour58" 58 "Colour59" 59 "Colour60" 60 "Colour61" 61 "Colour62" 62 "Colour63" 63 "Colour64" 64 "Reserved" 65 "Reserved" 66 "Reserved" 67 "Reserved" 68 "Reserved" 69 "Reserved" 70 "Reserved" 71 "Reserved" 72 "Reserved" 73 "Reserved" 74 "Reserved" 75 "Reserved" 76 "Reserved" 77 "Reserved" 78 "Reserved" 79 "Reserved" 80 "Reserved" 81 "Reserved" 82 "Reserved" 83 "Reserved" 84 "Reserved" 85 "Reserved" 86 "Reserved" 87 "Reserved" 88 "Reserved" 89 "Reserved" 90 "Reserved" 91 "Reserved" 92 "Reserved" 93 "Reserved" 94 "Reserved" 95 "Reserved" 96 "Reserved" 97 "Reserved" 98 "Reserved" 99 "Reserved" 100 "Reserved" 101 "Reserved" 102 "Reserved" 103 "Reserved" 104 "Reserved" 105 "Reserved" 106 "Reserved" 107 "Reserved" 108 "Reserved" 109 "Reserved" 110 "Reserved" 111 "Reserved" 112 "Reserved" 113 "Reserved" 114 "Reserved" 115 "Reserved" 116 "Reserved" 117 "Reserved" 118 "Reserved" 119 "Reserved" 120 "Reserved" 121 "Reserved" 122 "Reserved" 123 "Reserved" 124 "Reserved" 125 "Reserved" 126 "Reserved" 127 "Reserved" 128 "Reserved" 129 "Reserved" 130 "Reserved" 131 "Reserved" 132 "Reserved" 133 "Reserved" 134 "Reserved" 135 "Reserved" 136 "Reserved" 137 "Reserved" 138 "Reserved" 139 "Reserved" 140 "Reserved" 141 "Reserved" 142 "Reserved" 143 "Reserved" 144 "Reserved" 145 "Reserved" 146 "Reserved" 147 "Reserved" 148 "Reserved" 149 "Reserved" 150 "Reserved" 151 "Reserved" 152 "Reserved" 153 "Reserved" 154 "Reserved" 155 "Reserved" 156 "Reserved" 157 "Reserved" 158 "Reserved" 159 "Reserved" 160 "Reserved" 161 "Reserved" 162 "Reserved" 163 "Reserved" 164 "Reserved" 165 "Reserved" 166 "Reserved" 167 "Reserved" 168 "Reserved" 169 "Reserved" 170 "Reserved" 171 "Reserved" 172 "Reserved" 173 "Reserved" 174 "Reserved" 175 "Reserved" 176 "Reserved" 177 "Reserved" 178 "Reserved" 179 "Reserved" 180 "Reserved" 181 "Reserved" 182 "Reserved" 183 "Reserved" 184 "Reserved" 185 "Reserved" 186 "Reserved" 187 "Reserved" 188 "Reserved" 189 "Reserved" 190 "Reserved" 191 "Reserved" 192 "Reserved" 193 "Reserved" 194 "Reserved" 195 "Reserved" 196 "Reserved" 197 "Reserved" 198 "Reserved" 199 "Reserved" 200 "Reserved" 201 "Reserved" 202 "Reserved" 203 "Reserved" 204 "Reserved" 205 "Reserved" 206 "Reserved" 207 "Reserved" 208 "Reserved" 209 "Reserved" 210 "Reserved" 211 "Reserved" 212 "Reserved" 213 "Reserved" 214 "Reserved" 215 "Reserved" 216 "Reserved" 217 "Reserved" 218 "Reserved" 219 "Reserved" 220 "Reserved" 221 "Reserved" 222 "Reserved" 223 "Reserved" 224 "Reserved" 225 "Reserved" 226 "Reserved" 227 "Reserved" 228 "Reserved" 229 "Reserved" 230 "Reserved" 231 "Reserved" 232 "Reserved" 233 "Reserved" 234 "Reserved" 235 "Reserved" 236 "Reserved" 237 "Reserved" 238 "Reserved" 239 "Reserved" 240 "Reserved" 241 "Reserved" 242 "Reserved" 243 "Reserved" 244 "Reserved" 245 "Reserved" 246 "Reserved" 247 "Reserved" 248 "Reserved" 249 "Reserved" 250 "Reserved" 251 "Reserved" 252 "Reserved" 253 "Reserved" 254 "Reserved" 255 "Reserved" ;
VAL_ 823 BCM_CarSharingLightSts 0 "Disable" 1 "Enable" ;
VAL_ 823 BCM_HeadlLampMotorError 0 "No Error" 1 "Left Motor Error" 2 "Right Motor Error" 3 "LH&RH Motor Error" 4 "Other Error" 5 "Reserved" 6 "Reserved" 7 "Reserved" ;
VAL_ 824 MessageCounter_338 15 "Invalid" ;
VAL_ 824 BCM_HazardWarnSts 0 "Off" 1 "On" ;
VAL_ 824 BCM_DRLReq 0 "Reserved" 1 "Off" 2 "On" ;
VAL_ 824 BCM_FollowMeHomeSts 0 "OFF" 1 "ON" ;
VAL_ 824 BCM_ChargingLightReq 0 "Not active" 1 "0%-20%" 2 "21%-40%" 3 "41%-60%" 4 "61%-80%" 5 "81%-99%" 6 "100%" 7 "Fault" ;
VAL_ 824 BCM_TaxiArrIllReq 0 "No request" 1 "Active" ;
VAL_ 824 BCM_LeCornrgLiReq 0 "Reserved" 1 "Off" 2 "On" ;
VAL_ 824 BCM_MainBeamReq 0 "Reserved" 1 "Off" 2 "On" ;
VAL_ 824 BCM_DippedBeamReq 0 "Reserved" 1 "Off" 2 "On" 3 "Auto on" ;
VAL_ 824 BCM_RiCornrgLiReq 0 "Reserved" 1 "Off" 2 "On" ;
VAL_ 824 BCM_RLS_AutoLampSenSts 0 "Early" 1 "Standard" 2 "Late" 3 "Reserved" ;
VAL_ 824 BCM_RearFogLampSts 0 "Off" 1 "On" ;
VAL_ 824 BCM_ExtLightFault 0 "No error" 1 "Error" ;
VAL_ 824 BCM_StoplampReq 0 "No Request" 1 "Request" ;
VAL_ 824 BCM_AutoLmpSts 0 "Off" 1 "On" ;
VAL_ 824 BCM_HeightSetSts 0 "Reserved" 1 "Level 0" 2 "Level 1" 3 "Level 2" 4 "Level 3" 5 "Level 4" 6 "Reserved" 7 "Reserved" ;
VAL_ 824 BCM_RLS_LightSensorFault 0 "Normal" 1 "Fault" ;
VAL_ 824 BCM_RLS_RainSensorFault 0 "FALSE" 1 "TRUE" ;
VAL_ 824 BCM_PosLampReq 0 "Reserved" 1 "Off" 2 "On" ;
VAL_ 824 BCM_FrontFogLampReq 0 "Reserved" 1 "Off" 2 "On" ;
VAL_ 824 BCM_FRDomeLampSts 0 "OFF" 1 "ON" ;
VAL_ 824 BCM_RRDomeLampSts 0 "OFF" 1 "ON" ;
VAL_ 824 BCM_WiperFaultWarn 0 "Normal" 1 "Fault" ;
VAL_ 825 MessageCounter_339 15 "Invalid" ;
VAL_ 825 BCM_LockFailRemindReq 0 "No Warning" 1 "Warning" ;
VAL_ 825 BCM_LockRLCtrlReq 0 "No Request" 1 "Unlock" 2 "Lock" 3 "Reserved" ;
VAL_ 825 BCM_LockRRCtrlReq 0 "No Request" 1 "Unlock" 2 "Lock" 3 "Reserved" ;
VAL_ 825 BCM_LockFRCtrlReq 0 "No Request" 1 "Unlock" 2 "Lock" 3 "Reserved" ;
VAL_ 825 BCM_LockFLCtrlReq 0 "No Request" 1 "Unlock" 2 "Lock" 3 "Reserved" ;
VAL_ 825 BCM_AwayLockSts 0 "INACTIVE" 1 "ACTIVE" ;
VAL_ 825 BCM_OutsideUnlockModeSts 0 "One door" 1 "All doors" ;
VAL_ 825 BCM_ApproachingUnlockSts 0 "INACTIVE" 1 "ACTIVE" ;
VAL_ 825 BCM_ChrgFlapSts 0 "Closed" 1 "Opened" ;
VAL_ 825 BCM_TailgateLogicLockSts 0 "Locked" 1 "Unlocked" ;
VAL_ 825 BCM_TailgateSts 0 "Closed" 1 "Opened" ;
VAL_ 825 BCM_HoodSts 0 "Closed" 1 "Opened" ;
VAL_ 825 BCM_CentralLockSts 0 "Locked" 1 "Unlocked" ;
VAL_ 825 BCM_ChdLockSts 0 "Both Sides Unlocked" 1 "Both Sides Locked" 2 "Right Side Locked, Left Side Unlocked" 3 "Right Side Unlocked, Left Side Locked" ;
VAL_ 825 BCM_GlassUnclsWarnCtrlRqst 0 "No Request" 1 "Close Request" ;
VAL_ 825 BCM_NFCCloseDoorAndLockFeedback 0 "Disable" 1 "Enable" ;
VAL_ 825 BCM_WinAntipinchNotice 0 "Not Anti-Pinch" 1 "Anti-Pinch" ;
VAL_ 825 BCM_LockDoorOpenReHornSts 0 "Normal Mode" 1 "Silence Mode" ;
VAL_ 825 BCM_AntiTheftReHornSts 0 "Normal Mode" 1 "Silence Mode" ;
VAL_ 825 BCM_LeftKeyReHornSts 0 "Normal Mode" 1 "Silence Mode" ;
VAL_ 825 BCM_AlarmEnableSts 0 "Disable" 1 "Enable" ;
VAL_ 825 BCM_RelockSts 0 "INACTIVE" 1 "ACTIVE" 2 "Reserved" 3 "Reserved" 4 "Reserved" ;
VAL_ 825 BCM_WinClsReq 0 "No Request" 1 "Close" ;
VAL_ 826 MessageCounter_33A 15 "Invalid" ;
VAL_ 826 BCM_GearTimesSts 0 "0" 1 "1" 2 "2" 3 "3" 4 "4" 5 "5" ;
VAL_ 826 BCM_ChrgFlapLockSts 0 "Locked" 1 "Unlocked" ;
VAL_ 826 BCM_FRSeatBeltRemindReq 0 "No request" 1 "First level reminder" 2 "Second level reminder" 3 "Reserved" ;
VAL_ 826 BCM_FLSeatBeltRemindReq 0 "No request" 1 "First level reminder" 2 "Second level reminder" 3 "Reserved" ;
VAL_ 826 BCM_KeyNotInCarRemind 0 "No Warning" 1 "Warning" ;
VAL_ 826 BCM_RRSeatBeltRemindReq 0 "No request" 1 "First level reminder" 2 "Second level reminder" 3 "Reserved" ;
VAL_ 826 BCM_RLSeatBeltRemindReq 0 "No request" 1 "First level reminder" 2 "Second level reminder" 3 "Reserved" ;
VAL_ 826 BCM_WiperServiceSts 0 "OFF" 1 "ON" ;
VAL_ 826 BCM_AutoCloseWinFunSts 0 "No Active" 1 "Active" ;
VAL_ 826 BCM_DomeLampBrightSts 0 "100%" 1 "50%" ;
VAL_ 826 BCM_PuddleLiReq 0 "Reserved" 1 "Off" 2 "On" ;
VAL_ 826 BCM_DomeLampAutoSts 0 "Non-auto set" 1 "Door open auto set" 2 "Door close auto set" ;
VAL_ 826 BCM_FrontWiperModeSts 0 "OFF" 1 "AUTO" 2 "Low speed" 3 "High speed" 4 "Intermittent" 5 "Reserved" ;
VAL_ 826 BCM_WiperWorkingSts 0 "OFF" 1 "Low speed" 2 "High speed" ;
VAL_ 826 BCM_WelLightshowOnOffSts 0 "Reserved" 1 "OFF" 2 "ON" ;
VAL_ 625 MessageCounter_271 15 "Invalid" ;
VAL_ 625 BCM_PepsPowerMode 0 "Default" 1 "OFF" 2 "Local ON" 3 "Reserve" 4 "Reserve" 5 "Reserve" 6 "Reserve" 7 "Invalid" ;
VAL_ 625 BCM_PowerOffDisplayReq 0 "No Request" 1 "Req_Power off" ;
VAL_ 828 BCM_AmbientLiAniSts 0 "Reserved" 1 "Animation 1" 2 "Animation 2" 3 "Animation 3" 4 "Animation 4" 5 "Animation 5" 6 "Animation 6" 7 "Animation 7" 8 "Animation 8" 9 "Animation 9" 10 "Animation 10" 11 "Animation 11" 12 "Animation 12" 13 "Animation 13" 14 "Animation 14" 15 "Animation 15" 16 "Animation 16" 17 "Animation 17" 18 "Animation 18" 19 "Animation 19" 20 "Animation 20" 21 "Animation 21" 22 "Animation 22" 23 "Animation 23" 24 "Animation 24" 25 "Animation 25" ;
VAL_ 828 BCM_ChildLockError 0 "No error" 1 "Error" 2 "Reserved" 3 "Reserved" ;
VAL_ 828 BCM_RLS_lightSWReason 0 "Dark start" 1 "Day" 2 "Night" 3 "Tunnel" ;
VAL_ 828 BCM_FrontwinHeatingSts 0 "OFF" 1 "ON" ;
VAL_ 828 BCM_RearwinHeatingSts 0 "OFF" 1 "ON" ;
VAL_ 828 BCM_WiperWashSts 0 "No Wash" 1 "Wash" ;
VAL_ 828 BCM_RearCameraWashingSts 0 "OFF" 1 "ON" ;
VAL_ 828 BCM_LiquidLevelAlarmSts 0 "No Alarm" 1 "<10% Alarm" ;
VAL_ 828 BCM_L_RearSeatHeatSts 0 "OFF" 1 "ON" ;
VAL_ 828 BCM_R_RearSeatHeatSts 0 "OFF" 1 "ON" ;
VAL_ 828 BCM_IPAmbientLightSts 0 "OFF" 1 "ON" ;
VAL_ 828 BCM_AmbientLightBrightSts 0 "Reserved" 1 "LV1" 2 "LV2" 3 "LV3" 4 "LV4" 5 "LV5_NORMAL" 6 "LV6" 7 "LV7" 8 "LV8" 9 "LV9" 10 "LV10" ;
VAL_ 828 BCM_AmbientLightColorSts 0 "Colour1" 1 "Colour2" 2 "Colour3" 3 "Colour4" 4 "Colour5" 5 "Colour6" 6 "Colour7" 7 "Colour8" 8 "Colour9" 9 "Colour10" 10 "Colour11" 11 "Colour12" 12 "Colour13" 13 "Colour14" 14 "Colour15" 15 "Colour16" 16 "Colour17" 17 "Colour18" 18 "Colour19" 19 "Colour20" 20 "Colour21" 21 "Colour22" 22 "Colour23" 23 "Colour24" 24 "Colour25" 25 "Colour26" 26 "Colour27" 27 "Colour28" 28 "Colour29" 29 "Colour30" 30 "Colour31" 31 "Colour32" 32 "Colour33" 33 "Colour34" 34 "Colour35" 35 "Colour36" 36 "Colour37" 37 "Colour38" 38 "Colour39" 39 "Colour40" 40 "Colour41" 41 "Colour42" 42 "Colour43" 43 "Colour44" 44 "Colour45" 45 "Colour46" 46 "Colour47" 47 "Colour48" 48 "Colour49" 49 "Colour50" 50 "Colour51" 51 "Colour52" 52 "Colour53" 53 "Colour54" 54 "Colour55" 55 "Colour56" 56 "Colour57" 57 "Colour58" 58 "Colour59" 59 "Colour60" 60 "Colour61" 61 "Colour62" 62 "Colour63" 63 "Colour64" 64 "Reserved" 65 "Reserved" 66 "Reserved" 67 "Reserved" 68 "Reserved" 69 "Reserved" 70 "Reserved" 71 "Reserved" 72 "Reserved" 73 "Reserved" 74 "Reserved" 75 "Reserved" 76 "Reserved" 77 "Reserved" 78 "Reserved" 79 "Reserved" 80 "Reserved" 81 "Reserved" 82 "Reserved" 83 "Reserved" 84 "Reserved" 85 "Reserved" 86 "Reserved" 87 "Reserved" 88 "Reserved" 89 "Reserved" 90 "Reserved" 91 "Reserved" 92 "Reserved" 93 "Reserved" 94 "Reserved" 95 "Reserved" 96 "Reserved" 97 "Reserved" 98 "Reserved" 99 "Reserved" 100 "Reserved" 101 "Reserved" 102 "Reserved" 103 "Reserved" 104 "Reserved" 105 "Reserved" 106 "Reserved" 107 "Reserved" 108 "Reserved" 109 "Reserved" 110 "Reserved" 111 "Reserved" 112 "Reserved" 113 "Reserved" 114 "Reserved" 115 "Reserved" 116 "Reserved" 117 "Reserved" 118 "Reserved" 119 "Reserved" 120 "Reserved" 121 "Reserved" 122 "Reserved" 123 "Reserved" 124 "Reserved" 125 "Reserved" 126 "Reserved" 127 "Reserved" 128 "Reserved" 129 "Reserved" 130 "Reserved" 131 "Reserved" 132 "Reserved" 133 "Reserved" 134 "Reserved" 135 "Reserved" 136 "Reserved" 137 "Reserved" 138 "Reserved" 139 "Reserved" 140 "Reserved" 141 "Reserved" 142 "Reserved" 143 "Reserved" 144 "Reserved" 145 "Reserved" 146 "Reserved" 147 "Reserved" 148 "Reserved" 149 "Reserved" 150 "Reserved" 151 "Reserved" 152 "Reserved" 153 "Reserved" 154 "Reserved" 155 "Reserved" 156 "Reserved" 157 "Reserved" 158 "Reserved" 159 "Reserved" 160 "Reserved" 161 "Reserved" 162 "Reserved" 163 "Reserved" 164 "Reserved" 165 "Reserved" 166 "Reserved" 167 "Reserved" 168 "Reserved" 169 "Reserved" 170 "Reserved" 171 "Reserved" 172 "Reserved" 173 "Reserved" 174 "Reserved" 175 "Reserved" 176 "Reserved" 177 "Reserved" 178 "Reserved" 179 "Reserved" 180 "Reserved" 181 "Reserved" 182 "Reserved" 183 "Reserved" 184 "Reserved" 185 "Reserved" 186 "Reserved" 187 "Reserved" 188 "Reserved" 189 "Reserved" 190 "Reserved" 191 "Reserved" 192 "Reserved" 193 "Reserved" 194 "Reserved" 195 "Reserved" 196 "Reserved" 197 "Reserved" 198 "Reserved" 199 "Reserved" 200 "Reserved" 201 "Reserved" 202 "Reserved" 203 "Reserved" 204 "Reserved" 205 "Reserved" 206 "Reserved" 207 "Reserved" 208 "Reserved" 209 "Reserved" 210 "Reserved" 211 "Reserved" 212 "Reserved" 213 "Reserved" 214 "Reserved" 215 "Reserved" 216 "Reserved" 217 "Reserved" 218 "Reserved" 219 "Reserved" 220 "Reserved" 221 "Reserved" 222 "Reserved" 223 "Reserved" 224 "Reserved" 225 "Reserved" 226 "Reserved" 227 "Reserved" 228 "Reserved" 229 "Reserved" 230 "Reserved" 231 "Reserved" 232 "Reserved" 233 "Reserved" 234 "Reserved" 235 "Reserved" 236 "Reserved" 237 "Reserved" 238 "Reserved" 239 "Reserved" 240 "Reserved" 241 "Reserved" 242 "Reserved" 243 "Reserved" 244 "Reserved" 245 "Reserved" 246 "Reserved" 247 "Reserved" 248 "Reserved" 249 "Reserved" 250 "Reserved" 251 "Reserved" 252 "Reserved" 253 "Reserved" 254 "Reserved" 255 "Reserved" ;
VAL_ 192 MessageCounter_0C0 15 "Invalid" ;
VAL_ 192 BCM_LeftTurnLampReq 0 "No Request" 1 "Off" 2 "On" ;
VAL_ 192 BCM_RightTurnLampReq 0 "No Request" 1 "Off" 2 "On" ;
VAL_ 192 BCM_TurnLampSerialReq 0 "No Request" 1 "Request" 2 "RESERVED" 3 "RESERVED" ;
VAL_ 267 BCM_CentralLockFeedback 0 "Locking Fail Outside" 1 "Locking Success Outside" 2 "Unlocking Fail Outside" 3 "Unlocking Success Outside" ;
VAL_ 267 BCM_LVonReqKeyNotInCar 0 "NO_WARNING" 1 "WARNING" ;
VAL_ 626 BCM_Immo_State 0 "Disable immo" 1 "Enable immo" ;
VAL_ 624 BCM_ALM1_MusicFrequencySts 0 "OFF" 1 "ON" ;
VAL_ 624 BCM_ALM2_MusicFrequencySts 0 "OFF" 1 "ON" ;
VAL_ 820 BCM_AntiTheftSts 0 "DISARMED" 1 "ARMED" 2 "ALARM" 3 "HALF_ARMED" ;
VAL_ 820 BCM_AlarmedRemind 0 "No Warning" 1 "Warning" ;
VAL_ 820 BCM_ImmobilizingRemind 0 "No worning" 1 "Please stop" 2 "Immobilizing" 3 "Reserved" ;
VAL_ 531 BMS_DCChgMode 0 "Ready" 1 "Constant voltage" 2 "Constant current" ;
VAL_ 531 BMS_AbortAchiveSingleVolt 0 "Not reached" 1 "Reached" 2 "Untrustable" ;
VAL_ 531 BMS_AbortAchiveTotalVolt 0 "Not reached" 1 "Reached" 2 "Untrustable" ;
VAL_ 531 BMS_AbortFaultBMSTemp 0 "Normal" 1 "Over temp" 2 "Untrustable" ;
VAL_ 531 BMS_AbortFaultBatteryTemp 0 "Normal" 1 "Over temp" 2 "Untrustable" ;
VAL_ 531 BMS_AbortErrorCurrent 0 "Normal" 1 "Over current" 2 "Untrustable" ;
VAL_ 531 BMS_AbortAchivesetValue 0 "Not reached" 1 "Reached" 2 "Untrustable" ;
VAL_ 531 BMS_AbortErrorVoltage 0 "Normal" 1 "Abnormal" 2 "Untrustable" ;
VAL_ 531 BMS_ChagComplete 0 "Normal Completion" 1 "Abnormal completion" 2 "Untrustable" 3 "During Charging" ;
VAL_ 531 BMS_ChargeRequest 0 "Invalid" 1 "Heat Request only" 2 "Heat And Charge Request" 3 "Charge Only" 4 "Cool And Charge Request" ;
VAL_ 528 BMS_PosRelayStatus 0 "Reserved" 1 "Closed" 2 "Opened" 3 "Signal Invalid" ;
VAL_ 528 BMS_PTCRelayStatus 0 "Reserved" 1 "Closed" 2 "Opened" 3 "Signal Invalid" ;
VAL_ 528 BMS_NegRelayStatus 0 "Reserved" 1 "Closed" 2 "Opened" 3 "Signal Invalid" ;
VAL_ 528 BMS_PreRelayStatus 0 "Reserved" 1 "Closed" 2 "Opened" 3 "Signal Invalid" ;
VAL_ 772 BMS_ErrorCellOverVolt 0 "Normal" 1 "Fault Level1" 2 "Fault Level2" 3 "Fault Level3" ;
VAL_ 772 BMS_ErrorCellUnderVolt 0 "Normal" 1 "Fault Level1" 2 "Fault Level2" 3 "Fault Level3" ;
VAL_ 772 BMS_ErrorCellHighTemp 0 "Normal" 1 "Fault Level1" 2 "Fault Level2" 3 "Fault Level3" ;
VAL_ 772 BMS_ErrorCellLowTemp 0 "Normal" 1 "Fault Level1" 2 "Fault Level2" 3 "Fault Level3" ;
VAL_ 772 BMS_ErrorBattOverVolt 0 "Normal" 1 "Fault Level1" 2 "Fault Level2" 3 "Fault Level3" ;
VAL_ 772 BMS_ErrorBattUnderVolt 0 "Normal" 1 "Fault Level1" 2 "Fault Level2" 3 "Fault Level3" ;
VAL_ 772 BMS_ErrorChaCurrentOver 0 "Normal" 1 "Fault Level1" 2 "Fault Level2" 3 "Fault Level3" ;
VAL_ 772 BMS_ErrorDisChaCurrentOver 0 "Normal" 1 "Fault Level1" 2 "Fault Level2" 3 "Fault Level3" ;
VAL_ 772 BMS_ErrorBSUOffline 0 "Normal" 1 "Fault" ;
VAL_ 772 BMS_ErrorLeakCurrent 0 "Normal" 1 "Fault Level1" 2 "Fault Level2" 3 "Fault Level3" ;
VAL_ 772 BMS_ErrorCellVoltDiff 0 "Normal" 1 "Fault Level1" 2 "Fault Level2" 3 "Fault Level3" ;
VAL_ 772 BMS_ErrorCellTempDiff 0 "Normal" 1 "Fault Level1" 2 "Fault Level2" 3 "Fault Level3" ;
VAL_ 772 BMS_ErrorBatVolt 0 "Normal" 1 "Fault Level1" 2 "Fault Level2" 3 "Fault Level3" ;
VAL_ 772 BMS_ErrorHallOffline 0 "Normal" 1 "Fault" ;
VAL_ 772 BMS_ErrorCellVoltOffline 0 "Normal" 1 "Fault" ;
VAL_ 772 BMS_ErrorCellTempOffline 0 "Normal" 1 "Fault" ;
VAL_ 772 BMS_ErrorPreChaFailed 0 "Normal" 1 "Fault" ;
VAL_ 772 BMS_ErrorRelay 0 "Normal" 1 "Fault" ;
VAL_ 772 BMS_ErrorBSUBalance 0 "Normal" 1 "Fault" ;
VAL_ 772 BMS_ErrorLowSoc 0 "Normal" 1 "Fault Level1" 2 "Fault Level2" 3 "Fault Level3" ;
VAL_ 772 BMS_ErrorHighSoc 0 "Normal" 1 "Fault" ;
VAL_ 772 BMS_ErrorSoCJump_RM 0 "Normal" 1 "Fault" ;
VAL_ 772 BMS_ErrorHVIL 0 "Normal" 1 "Fault" ;
VAL_ 772 BMS_ErrorEmergencyOffCrash 0 "Normal" 1 "Fault" ;
VAL_ 772 BMS_ErrorSystemsMatch 0 "Normal" 1 "Fault" ;
VAL_ 772 BMS_ErrorSmoke 0 "Normal" 1 "Fault" ;
VAL_ 772 BMS_ErrorLeakDet 0 "Normal" 1 "Fault" ;
VAL_ 772 BMS_ThermalRunawayFault 0 "Normal" 1 "Fault" ;
VAL_ 193 MessageCounter_0C1 15 "Invalid" ;
VAL_ 193 BMS_ErrorIsolationSingleLow 0 "Normal" 1 "Fault Level1" 2 "Fault Level2" 3 "Fault Level3" ;
VAL_ 193 BMS_WorkMode 0 "Initialize" 1 "Standby" 2 "Running" 3 "DC charge" 4 "AC charge" 5 "Discharge" 6 "Error" 7 "Invalid" ;
VAL_ 193 BMS_BalancingStatus 0 "stop" 1 "active" ;
VAL_ 193 BMS_HVinterlockState 0 "Normal" 1 "Fault" ;
VAL_ 193 BMS_ThrmlRunawayFault 0 "Normal" 1 "Fault" ;
VAL_ 193 BMS_PreCharge 0 "Not precharge" 1 "Precharging" 2 "Precharge finished" 3 "Precharge failed" ;
VAL_ 193 BMS_ChargeStatus 0 "Not charging" 1 "Heat only" 2 "Charge and heat(DC)" 3 "Charge and heat(AC)" 4 "Charge only(DC)" 5 "Charge only(AC)" 6 "Charge hold" 7 "Charge stop" ;
VAL_ 193 BMS_RunHeatStatus 0 "Running heat" 1 "Target heat" 2 "App heat" 3 "Running cool" 4 "not heat not cool" ;
VAL_ 193 BMS_ErrorLevel 0 "Normal" 1 "level1" 2 "level2" 3 "level3" 4 "level4" ;
VAL_ 771 BMS_CoolCommand 0 "Not cooling" 1 "Reserved" 2 "Charge and cool(DC)" 3 "Charge and cool(AC)" 4 "Running cool" 5 "Keep cool" 6 "Reserved" 7 "Target cool" ;
VAL_ 771 BMS_HeatCommand 0 "Not heat" 1 "Preheating" 2 "Charge and heat(DC)" 3 "Charge and heat(AC)" 4 "Running heat" 5 "Keep warm" 6 "Reserved" 7 "Target heat" ;
VAL_ 771 BMS_KeepWarmRequest 0 "Not Request" 1 "Request" ;
VAL_ 771 BMS_KeepWarmStatus 0 "Init" 1 "OFF" 2 "ON" ;
VAL_ 771 BMS_RTC_Request 0 "No request" 1 "Request" ;
VAL_ 771 BMS_BalanceCommand 0 "No request" 1 "Request" ;
VAL_ 932 BMS_BatProRights 0 "lease" 1 "Buy" ;
VAL_ 257 CBM_BLE_CarSearchReq 0 "No Request" 1 "Request" ;
VAL_ 721 CBM_PhoneLocation 0 "Invalid" 1 "Welcome Invalid Zone" 2 "Welcome lighting area" 3 "Stay away from the locked area" 4 "Approaching the unlocking area" 5 "In Car" 6 "Left PE area" 7 "Right PE area" 8 "PE area of back door" ;
VAL_ 721 CBM_BlePairingSetSts 0 "Invalid" 1 "Enable" 2 "Disable" ;
VAL_ 632 MessageCounter_278 15 "Invalid" ;
VAL_ 632 CGW_VehicleState 0 "Fully sleep" 1 "Invisible awake-CANwakeup" 2 "Reserve" 3 "Reserve" 4 "Invisible awake-OnlyHVon" 5 "Standby-Normal" 6 "Standby-OnlyLVon" 7 "Drive-Normal" 8 "Drive-LVFault" ;
VAL_ 646 DCM_ALM_FL_MusicFrequencySts 0 "OFF" 1 "ON" ;
VAL_ 646 DCM_FL_AmbientLightSts 0 "OFF" 1 "ON" ;
VAL_ 646 DCM_FL_AmbientLightBrightSts 0 "Reserved" 1 "LV1" 2 "LV2" 3 "LV3" 4 "LV4" 5 "LV5_NORMAL" 6 "LV6" 7 "LV7" 8 "LV8" 9 "LV9" 10 "LV10" ;
VAL_ 646 DCM_FL_AmbientLightColorSts 0 "Colour1" 1 "Colour2" 2 "Colour3" 3 "Colour4" 4 "Colour5" 5 "Colour6" 6 "Colour7" 7 "Colour8" 8 "Colour9" 9 "Colour10" 10 "Colour11" 11 "Colour12" 12 "Colour13" 13 "Colour14" 14 "Colour15" 15 "Colour16" 16 "Colour17" 17 "Colour18" 18 "Colour19" 19 "Colour20" 20 "Colour21" 21 "Colour22" 22 "Colour23" 23 "Colour24" 24 "Colour25" 25 "Colour26" 26 "Colour27" 27 "Colour28" 28 "Colour29" 29 "Colour30" 30 "Colour31" 31 "Colour32" 32 "Colour33" 33 "Colour34" 34 "Colour35" 35 "Colour36" 36 "Colour37" 37 "Colour38" 38 "Colour39" 39 "Colour40" 40 "Colour41" 41 "Colour42" 42 "Colour43" 43 "Colour44" 44 "Colour45" 45 "Colour46" 46 "Colour47" 47 "Colour48" 48 "Colour49" 49 "Colour50" 50 "Colour51" 51 "Colour52" 52 "Colour53" 53 "Colour54" 54 "Colour55" 55 "Colour56" 56 "Colour57" 57 "Colour58" 58 "Colour59" 59 "Colour60" 60 "Colour61" 61 "Colour62" 62 "Colour63" 63 "Colour64" 64 "Reserved" 65 "Reserved" 66 "Reserved" 67 "Reserved" 68 "Reserved" 69 "Reserved" 70 "Reserved" 71 "Reserved" 72 "Reserved" 73 "Reserved" 74 "Reserved" 75 "Reserved" 76 "Reserved" 77 "Reserved" 78 "Reserved" 79 "Reserved" 80 "Reserved" 81 "Reserved" 82 "Reserved" 83 "Reserved" 84 "Reserved" 85 "Reserved" 86 "Reserved" 87 "Reserved" 88 "Reserved" 89 "Reserved" 90 "Reserved" 91 "Reserved" 92 "Reserved" 93 "Reserved" 94 "Reserved" 95 "Reserved" 96 "Reserved" 97 "Reserved" 98 "Reserved" 99 "Reserved" 100 "Reserved" 101 "Reserved" 102 "Reserved" 103 "Reserved" 104 "Reserved" 105 "Reserved" 106 "Reserved" 107 "Reserved" 108 "Reserved" 109 "Reserved" 110 "Reserved" 111 "Reserved" 112 "Reserved" 113 "Reserved" 114 "Reserved" 115 "Reserved" 116 "Reserved" 117 "Reserved" 118 "Reserved" 119 "Reserved" 120 "Reserved" 121 "Reserved" 122 "Reserved" 123 "Reserved" 124 "Reserved" 125 "Reserved" 126 "Reserved" 127 "Reserved" 128 "Reserved" 129 "Reserved" 130 "Reserved" 131 "Reserved" 132 "Reserved" 133 "Reserved" 134 "Reserved" 135 "Reserved" 136 "Reserved" 137 "Reserved" 138 "Reserved" 139 "Reserved" 140 "Reserved" 141 "Reserved" 142 "Reserved" 143 "Reserved" 144 "Reserved" 145 "Reserved" 146 "Reserved" 147 "Reserved" 148 "Reserved" 149 "Reserved" 150 "Reserved" 151 "Reserved" 152 "Reserved" 153 "Reserved" 154 "Reserved" 155 "Reserved" 156 "Reserved" 157 "Reserved" 158 "Reserved" 159 "Reserved" 160 "Reserved" 161 "Reserved" 162 "Reserved" 163 "Reserved" 164 "Reserved" 165 "Reserved" 166 "Reserved" 167 "Reserved" 168 "Reserved" 169 "Reserved" 170 "Reserved" 171 "Reserved" 172 "Reserved" 173 "Reserved" 174 "Reserved" 175 "Reserved" 176 "Reserved" 177 "Reserved" 178 "Reserved" 179 "Reserved" 180 "Reserved" 181 "Reserved" 182 "Reserved" 183 "Reserved" 184 "Reserved" 185 "Reserved" 186 "Reserved" 187 "Reserved" 188 "Reserved" 189 "Reserved" 190 "Reserved" 191 "Reserved" 192 "Reserved" 193 "Reserved" 194 "Reserved" 195 "Reserved" 196 "Reserved" 197 "Reserved" 198 "Reserved" 199 "Reserved" 200 "Reserved" 201 "Reserved" 202 "Reserved" 203 "Reserved" 204 "Reserved" 205 "Reserved" 206 "Reserved" 207 "Reserved" 208 "Reserved" 209 "Reserved" 210 "Reserved" 211 "Reserved" 212 "Reserved" 213 "Reserved" 214 "Reserved" 215 "Reserved" 216 "Reserved" 217 "Reserved" 218 "Reserved" 219 "Reserved" 220 "Reserved" 221 "Reserved" 222 "Reserved" 223 "Reserved" 224 "Reserved" 225 "Reserved" 226 "Reserved" 227 "Reserved" 228 "Reserved" 229 "Reserved" 230 "Reserved" 231 "Reserved" 232 "Reserved" 233 "Reserved" 234 "Reserved" 235 "Reserved" 236 "Reserved" 237 "Reserved" 238 "Reserved" 239 "Reserved" 240 "Reserved" 241 "Reserved" 242 "Reserved" 243 "Reserved" 244 "Reserved" 245 "Reserved" 246 "Reserved" 247 "Reserved" 248 "Reserved" 249 "Reserved" 250 "Reserved" 251 "Reserved" 252 "Reserved" 253 "Reserved" 254 "Reserved" 255 "Reserved" ;
VAL_ 646 DCM_FL_AmbientLiAniSts 0 "Reserved" 1 "Animation 1" 2 "Animation 2" 3 "Animation 3" 4 "Animation 4" 5 "Animation 5" 6 "Animation 6" 7 "Animation 7" 8 "Animation 8" 9 "Animation 9" 10 "Animation 10" 11 "Animation 11" 12 "Animation 12" 13 "Animation 13" 14 "Animation 14" 15 "Animation 15" 16 "Animation 16" 17 "Animation 17" 18 "Animation 18" 19 "Animation 19" 20 "Animation 20" 21 "Animation 21" 22 "Animation 22" 23 "Animation 23" 24 "Animation 24" 25 "Animation 25" ;
VAL_ 647 DCM_ALM_FR_MusicFrequencySts 0 "OFF" 1 "ON" ;
VAL_ 647 DCM_FR_AmbientLightSts 0 "OFF" 1 "ON" ;
VAL_ 647 DCM_FR_AmbientLightBrightSts 0 "Reserved" 1 "LV1" 2 "LV2" 3 "LV3" 4 "LV4" 5 "LV5_NORMAL" 6 "LV6" 7 "LV7" 8 "LV8" 9 "LV9" 10 "LV10" ;
VAL_ 647 DCM_FR_AmbientLightColorSts 0 "Colour1" 1 "Colour2" 2 "Colour3" 3 "Colour4" 4 "Colour5" 5 "Colour6" 6 "Colour7" 7 "Colour8" 8 "Colour9" 9 "Colour10" 10 "Colour11" 11 "Colour12" 12 "Colour13" 13 "Colour14" 14 "Colour15" 15 "Colour16" 16 "Colour17" 17 "Colour18" 18 "Colour19" 19 "Colour20" 20 "Colour21" 21 "Colour22" 22 "Colour23" 23 "Colour24" 24 "Colour25" 25 "Colour26" 26 "Colour27" 27 "Colour28" 28 "Colour29" 29 "Colour30" 30 "Colour31" 31 "Colour32" 32 "Colour33" 33 "Colour34" 34 "Colour35" 35 "Colour36" 36 "Colour37" 37 "Colour38" 38 "Colour39" 39 "Colour40" 40 "Colour41" 41 "Colour42" 42 "Colour43" 43 "Colour44" 44 "Colour45" 45 "Colour46" 46 "Colour47" 47 "Colour48" 48 "Colour49" 49 "Colour50" 50 "Colour51" 51 "Colour52" 52 "Colour53" 53 "Colour54" 54 "Colour55" 55 "Colour56" 56 "Colour57" 57 "Colour58" 58 "Colour59" 59 "Colour60" 60 "Colour61" 61 "Colour62" 62 "Colour63" 63 "Colour64" 64 "Reserved" 65 "Reserved" 66 "Reserved" 67 "Reserved" 68 "Reserved" 69 "Reserved" 70 "Reserved" 71 "Reserved" 72 "Reserved" 73 "Reserved" 74 "Reserved" 75 "Reserved" 76 "Reserved" 77 "Reserved" 78 "Reserved" 79 "Reserved" 80 "Reserved" 81 "Reserved" 82 "Reserved" 83 "Reserved" 84 "Reserved" 85 "Reserved" 86 "Reserved" 87 "Reserved" 88 "Reserved" 89 "Reserved" 90 "Reserved" 91 "Reserved" 92 "Reserved" 93 "Reserved" 94 "Reserved" 95 "Reserved" 96 "Reserved" 97 "Reserved" 98 "Reserved" 99 "Reserved" 100 "Reserved" 101 "Reserved" 102 "Reserved" 103 "Reserved" 104 "Reserved" 105 "Reserved" 106 "Reserved" 107 "Reserved" 108 "Reserved" 109 "Reserved" 110 "Reserved" 111 "Reserved" 112 "Reserved" 113 "Reserved" 114 "Reserved" 115 "Reserved" 116 "Reserved" 117 "Reserved" 118 "Reserved" 119 "Reserved" 120 "Reserved" 121 "Reserved" 122 "Reserved" 123 "Reserved" 124 "Reserved" 125 "Reserved" 126 "Reserved" 127 "Reserved" 128 "Reserved" 129 "Reserved" 130 "Reserved" 131 "Reserved" 132 "Reserved" 133 "Reserved" 134 "Reserved" 135 "Reserved" 136 "Reserved" 137 "Reserved" 138 "Reserved" 139 "Reserved" 140 "Reserved" 141 "Reserved" 142 "Reserved" 143 "Reserved" 144 "Reserved" 145 "Reserved" 146 "Reserved" 147 "Reserved" 148 "Reserved" 149 "Reserved" 150 "Reserved" 151 "Reserved" 152 "Reserved" 153 "Reserved" 154 "Reserved" 155 "Reserved" 156 "Reserved" 157 "Reserved" 158 "Reserved" 159 "Reserved" 160 "Reserved" 161 "Reserved" 162 "Reserved" 163 "Reserved" 164 "Reserved" 165 "Reserved" 166 "Reserved" 167 "Reserved" 168 "Reserved" 169 "Reserved" 170 "Reserved" 171 "Reserved" 172 "Reserved" 173 "Reserved" 174 "Reserved" 175 "Reserved" 176 "Reserved" 177 "Reserved" 178 "Reserved" 179 "Reserved" 180 "Reserved" 181 "Reserved" 182 "Reserved" 183 "Reserved" 184 "Reserved" 185 "Reserved" 186 "Reserved" 187 "Reserved" 188 "Reserved" 189 "Reserved" 190 "Reserved" 191 "Reserved" 192 "Reserved" 193 "Reserved" 194 "Reserved" 195 "Reserved" 196 "Reserved" 197 "Reserved" 198 "Reserved" 199 "Reserved" 200 "Reserved" 201 "Reserved" 202 "Reserved" 203 "Reserved" 204 "Reserved" 205 "Reserved" 206 "Reserved" 207 "Reserved" 208 "Reserved" 209 "Reserved" 210 "Reserved" 211 "Reserved" 212 "Reserved" 213 "Reserved" 214 "Reserved" 215 "Reserved" 216 "Reserved" 217 "Reserved" 218 "Reserved" 219 "Reserved" 220 "Reserved" 221 "Reserved" 222 "Reserved" 223 "Reserved" 224 "Reserved" 225 "Reserved" 226 "Reserved" 227 "Reserved" 228 "Reserved" 229 "Reserved" 230 "Reserved" 231 "Reserved" 232 "Reserved" 233 "Reserved" 234 "Reserved" 235 "Reserved" 236 "Reserved" 237 "Reserved" 238 "Reserved" 239 "Reserved" 240 "Reserved" 241 "Reserved" 242 "Reserved" 243 "Reserved" 244 "Reserved" 245 "Reserved" 246 "Reserved" 247 "Reserved" 248 "Reserved" 249 "Reserved" 250 "Reserved" 251 "Reserved" 252 "Reserved" 253 "Reserved" 254 "Reserved" 255 "Reserved" ;
VAL_ 647 DCM_FR_AmbientLiAniSts 0 "Reserved" 1 "Animation 1" 2 "Animation 2" 3 "Animation 3" 4 "Animation 4" 5 "Animation 5" 6 "Animation 6" 7 "Animation 7" 8 "Animation 8" 9 "Animation 9" 10 "Animation 10" 11 "Animation 11" 12 "Animation 12" 13 "Animation 13" 14 "Animation 14" 15 "Animation 15" 16 "Animation 16" 17 "Animation 17" 18 "Animation 18" 19 "Animation 19" 20 "Animation 20" 21 "Animation 21" 22 "Animation 22" 23 "Animation 23" 24 "Animation 24" 25 "Animation 25" ;
VAL_ 648 DCM_ALM_RL_MusicFrequencySts 0 "OFF" 1 "ON" ;
VAL_ 648 DCM_RL_AmbientLightSts 0 "OFF" 1 "ON" ;
VAL_ 648 DCM_RL_AmbientLightBrightSts 0 "Reserved" 1 "LV1" 2 "LV2" 3 "LV3" 4 "LV4" 5 "LV5_NORMAL" 6 "LV6" 7 "LV7" 8 "LV8" 9 "LV9" 10 "LV10" ;
VAL_ 648 DCM_RL_AmbientLightColorSts 0 "Colour1" 1 "Colour2" 2 "Colour3" 3 "Colour4" 4 "Colour5" 5 "Colour6" 6 "Colour7" 7 "Colour8" 8 "Colour9" 9 "Colour10" 10 "Colour11" 11 "Colour12" 12 "Colour13" 13 "Colour14" 14 "Colour15" 15 "Colour16" 16 "Colour17" 17 "Colour18" 18 "Colour19" 19 "Colour20" 20 "Colour21" 21 "Colour22" 22 "Colour23" 23 "Colour24" 24 "Colour25" 25 "Colour26" 26 "Colour27" 27 "Colour28" 28 "Colour29" 29 "Colour30" 30 "Colour31" 31 "Colour32" 32 "Colour33" 33 "Colour34" 34 "Colour35" 35 "Colour36" 36 "Colour37" 37 "Colour38" 38 "Colour39" 39 "Colour40" 40 "Colour41" 41 "Colour42" 42 "Colour43" 43 "Colour44" 44 "Colour45" 45 "Colour46" 46 "Colour47" 47 "Colour48" 48 "Colour49" 49 "Colour50" 50 "Colour51" 51 "Colour52" 52 "Colour53" 53 "Colour54" 54 "Colour55" 55 "Colour56" 56 "Colour57" 57 "Colour58" 58 "Colour59" 59 "Colour60" 60 "Colour61" 61 "Colour62" 62 "Colour63" 63 "Colour64" 64 "Reserved" 65 "Reserved" 66 "Reserved" 67 "Reserved" 68 "Reserved" 69 "Reserved" 70 "Reserved" 71 "Reserved" 72 "Reserved" 73 "Reserved" 74 "Reserved" 75 "Reserved" 76 "Reserved" 77 "Reserved" 78 "Reserved" 79 "Reserved" 80 "Reserved" 81 "Reserved" 82 "Reserved" 83 "Reserved" 84 "Reserved" 85 "Reserved" 86 "Reserved" 87 "Reserved" 88 "Reserved" 89 "Reserved" 90 "Reserved" 91 "Reserved" 92 "Reserved" 93 "Reserved" 94 "Reserved" 95 "Reserved" 96 "Reserved" 97 "Reserved" 98 "Reserved" 99 "Reserved" 100 "Reserved" 101 "Reserved" 102 "Reserved" 103 "Reserved" 104 "Reserved" 105 "Reserved" 106 "Reserved" 107 "Reserved" 108 "Reserved" 109 "Reserved" 110 "Reserved" 111 "Reserved" 112 "Reserved" 113 "Reserved" 114 "Reserved" 115 "Reserved" 116 "Reserved" 117 "Reserved" 118 "Reserved" 119 "Reserved" 120 "Reserved" 121 "Reserved" 122 "Reserved" 123 "Reserved" 124 "Reserved" 125 "Reserved" 126 "Reserved" 127 "Reserved" 128 "Reserved" 129 "Reserved" 130 "Reserved" 131 "Reserved" 132 "Reserved" 133 "Reserved" 134 "Reserved" 135 "Reserved" 136 "Reserved" 137 "Reserved" 138 "Reserved" 139 "Reserved" 140 "Reserved" 141 "Reserved" 142 "Reserved" 143 "Reserved" 144 "Reserved" 145 "Reserved" 146 "Reserved" 147 "Reserved" 148 "Reserved" 149 "Reserved" 150 "Reserved" 151 "Reserved" 152 "Reserved" 153 "Reserved" 154 "Reserved" 155 "Reserved" 156 "Reserved" 157 "Reserved" 158 "Reserved" 159 "Reserved" 160 "Reserved" 161 "Reserved" 162 "Reserved" 163 "Reserved" 164 "Reserved" 165 "Reserved" 166 "Reserved" 167 "Reserved" 168 "Reserved" 169 "Reserved" 170 "Reserved" 171 "Reserved" 172 "Reserved" 173 "Reserved" 174 "Reserved" 175 "Reserved" 176 "Reserved" 177 "Reserved" 178 "Reserved" 179 "Reserved" 180 "Reserved" 181 "Reserved" 182 "Reserved" 183 "Reserved" 184 "Reserved" 185 "Reserved" 186 "Reserved" 187 "Reserved" 188 "Reserved" 189 "Reserved" 190 "Reserved" 191 "Reserved" 192 "Reserved" 193 "Reserved" 194 "Reserved" 195 "Reserved" 196 "Reserved" 197 "Reserved" 198 "Reserved" 199 "Reserved" 200 "Reserved" 201 "Reserved" 202 "Reserved" 203 "Reserved" 204 "Reserved" 205 "Reserved" 206 "Reserved" 207 "Reserved" 208 "Reserved" 209 "Reserved" 210 "Reserved" 211 "Reserved" 212 "Reserved" 213 "Reserved" 214 "Reserved" 215 "Reserved" 216 "Reserved" 217 "Reserved" 218 "Reserved" 219 "Reserved" 220 "Reserved" 221 "Reserved" 222 "Reserved" 223 "Reserved" 224 "Reserved" 225 "Reserved" 226 "Reserved" 227 "Reserved" 228 "Reserved" 229 "Reserved" 230 "Reserved" 231 "Reserved" 232 "Reserved" 233 "Reserved" 234 "Reserved" 235 "Reserved" 236 "Reserved" 237 "Reserved" 238 "Reserved" 239 "Reserved" 240 "Reserved" 241 "Reserved" 242 "Reserved" 243 "Reserved" 244 "Reserved" 245 "Reserved" 246 "Reserved" 247 "Reserved" 248 "Reserved" 249 "Reserved" 250 "Reserved" 251 "Reserved" 252 "Reserved" 253 "Reserved" 254 "Reserved" 255 "Reserved" ;
VAL_ 648 DCM_RL_AmbientLiAniSts 0 "Reserved" 1 "Animation 1" 2 "Animation 2" 3 "Animation 3" 4 "Animation 4" 5 "Animation 5" 6 "Animation 6" 7 "Animation 7" 8 "Animation 8" 9 "Animation 9" 10 "Animation 10" 11 "Animation 11" 12 "Animation 12" 13 "Animation 13" 14 "Animation 14" 15 "Animation 15" 16 "Animation 16" 17 "Animation 17" 18 "Animation 18" 19 "Animation 19" 20 "Animation 20" 21 "Animation 21" 22 "Animation 22" 23 "Animation 23" 24 "Animation 24" 25 "Animation 25" ;
VAL_ 649 DCM_ALM_RR_MusicFrequencySts 0 "OFF" 1 "ON" ;
VAL_ 649 DCM_RR_AmbientLightSts 0 "OFF" 1 "ON" ;
VAL_ 649 DCM_RR_AmbientLightBrightSts 0 "Reserved" 1 "LV1" 2 "LV2" 3 "LV3" 4 "LV4" 5 "LV5_NORMAL" 6 "LV6" 7 "LV7" 8 "LV8" 9 "LV9" 10 "LV10" ;
VAL_ 649 DCM_RR_AmbientLightColorSts 0 "Colour1" 1 "Colour2" 2 "Colour3" 3 "Colour4" 4 "Colour5" 5 "Colour6" 6 "Colour7" 7 "Colour8" 8 "Colour9" 9 "Colour10" 10 "Colour11" 11 "Colour12" 12 "Colour13" 13 "Colour14" 14 "Colour15" 15 "Colour16" 16 "Colour17" 17 "Colour18" 18 "Colour19" 19 "Colour20" 20 "Colour21" 21 "Colour22" 22 "Colour23" 23 "Colour24" 24 "Colour25" 25 "Colour26" 26 "Colour27" 27 "Colour28" 28 "Colour29" 29 "Colour30" 30 "Colour31" 31 "Colour32" 32 "Colour33" 33 "Colour34" 34 "Colour35" 35 "Colour36" 36 "Colour37" 37 "Colour38" 38 "Colour39" 39 "Colour40" 40 "Colour41" 41 "Colour42" 42 "Colour43" 43 "Colour44" 44 "Colour45" 45 "Colour46" 46 "Colour47" 47 "Colour48" 48 "Colour49" 49 "Colour50" 50 "Colour51" 51 "Colour52" 52 "Colour53" 53 "Colour54" 54 "Colour55" 55 "Colour56" 56 "Colour57" 57 "Colour58" 58 "Colour59" 59 "Colour60" 60 "Colour61" 61 "Colour62" 62 "Colour63" 63 "Colour64" 64 "Reserved" 65 "Reserved" 66 "Reserved" 67 "Reserved" 68 "Reserved" 69 "Reserved" 70 "Reserved" 71 "Reserved" 72 "Reserved" 73 "Reserved" 74 "Reserved" 75 "Reserved" 76 "Reserved" 77 "Reserved" 78 "Reserved" 79 "Reserved" 80 "Reserved" 81 "Reserved" 82 "Reserved" 83 "Reserved" 84 "Reserved" 85 "Reserved" 86 "Reserved" 87 "Reserved" 88 "Reserved" 89 "Reserved" 90 "Reserved" 91 "Reserved" 92 "Reserved" 93 "Reserved" 94 "Reserved" 95 "Reserved" 96 "Reserved" 97 "Reserved" 98 "Reserved" 99 "Reserved" 100 "Reserved" 101 "Reserved" 102 "Reserved" 103 "Reserved" 104 "Reserved" 105 "Reserved" 106 "Reserved" 107 "Reserved" 108 "Reserved" 109 "Reserved" 110 "Reserved" 111 "Reserved" 112 "Reserved" 113 "Reserved" 114 "Reserved" 115 "Reserved" 116 "Reserved" 117 "Reserved" 118 "Reserved" 119 "Reserved" 120 "Reserved" 121 "Reserved" 122 "Reserved" 123 "Reserved" 124 "Reserved" 125 "Reserved" 126 "Reserved" 127 "Reserved" 128 "Reserved" 129 "Reserved" 130 "Reserved" 131 "Reserved" 132 "Reserved" 133 "Reserved" 134 "Reserved" 135 "Reserved" 136 "Reserved" 137 "Reserved" 138 "Reserved" 139 "Reserved" 140 "Reserved" 141 "Reserved" 142 "Reserved" 143 "Reserved" 144 "Reserved" 145 "Reserved" 146 "Reserved" 147 "Reserved" 148 "Reserved" 149 "Reserved" 150 "Reserved" 151 "Reserved" 152 "Reserved" 153 "Reserved" 154 "Reserved" 155 "Reserved" 156 "Reserved" 157 "Reserved" 158 "Reserved" 159 "Reserved" 160 "Reserved" 161 "Reserved" 162 "Reserved" 163 "Reserved" 164 "Reserved" 165 "Reserved" 166 "Reserved" 167 "Reserved" 168 "Reserved" 169 "Reserved" 170 "Reserved" 171 "Reserved" 172 "Reserved" 173 "Reserved" 174 "Reserved" 175 "Reserved" 176 "Reserved" 177 "Reserved" 178 "Reserved" 179 "Reserved" 180 "Reserved" 181 "Reserved" 182 "Reserved" 183 "Reserved" 184 "Reserved" 185 "Reserved" 186 "Reserved" 187 "Reserved" 188 "Reserved" 189 "Reserved" 190 "Reserved" 191 "Reserved" 192 "Reserved" 193 "Reserved" 194 "Reserved" 195 "Reserved" 196 "Reserved" 197 "Reserved" 198 "Reserved" 199 "Reserved" 200 "Reserved" 201 "Reserved" 202 "Reserved" 203 "Reserved" 204 "Reserved" 205 "Reserved" 206 "Reserved" 207 "Reserved" 208 "Reserved" 209 "Reserved" 210 "Reserved" 211 "Reserved" 212 "Reserved" 213 "Reserved" 214 "Reserved" 215 "Reserved" 216 "Reserved" 217 "Reserved" 218 "Reserved" 219 "Reserved" 220 "Reserved" 221 "Reserved" 222 "Reserved" 223 "Reserved" 224 "Reserved" 225 "Reserved" 226 "Reserved" 227 "Reserved" 228 "Reserved" 229 "Reserved" 230 "Reserved" 231 "Reserved" 232 "Reserved" 233 "Reserved" 234 "Reserved" 235 "Reserved" 236 "Reserved" 237 "Reserved" 238 "Reserved" 239 "Reserved" 240 "Reserved" 241 "Reserved" 242 "Reserved" 243 "Reserved" 244 "Reserved" 245 "Reserved" 246 "Reserved" 247 "Reserved" 248 "Reserved" 249 "Reserved" 250 "Reserved" 251 "Reserved" 252 "Reserved" 253 "Reserved" 254 "Reserved" 255 "Reserved" ;
VAL_ 649 DCM_RR_AmbientLiAniSts 0 "Reserved" 1 "Animation 1" 2 "Animation 2" 3 "Animation 3" 4 "Animation 4" 5 "Animation 5" 6 "Animation 6" 7 "Animation 7" 8 "Animation 8" 9 "Animation 9" 10 "Animation 10" 11 "Animation 11" 12 "Animation 12" 13 "Animation 13" 14 "Animation 14" 15 "Animation 15" 16 "Animation 16" 17 "Animation 17" 18 "Animation 18" 19 "Animation 19" 20 "Animation 20" 21 "Animation 21" 22 "Animation 22" 23 "Animation 23" 24 "Animation 24" 25 "Animation 25" ;
VAL_ 642 DCM_FL_CarSharingColorSts 0 "Colour1" 1 "Colour2" 2 "Colour3" 3 "Colour4" 4 "Colour5" 5 "Colour6" 6 "Colour7" 7 "Colour8" 8 "Colour9" 9 "Colour10" 10 "Colour11" 11 "Colour12" 12 "Colour13" 13 "Colour14" 14 "Colour15" 15 "Colour16" 16 "Colour17" 17 "Colour18" 18 "Colour19" 19 "Colour20" 20 "Colour21" 21 "Colour22" 22 "Colour23" 23 "Colour24" 24 "Colour25" 25 "Colour26" 26 "Colour27" 27 "Colour28" 28 "Colour29" 29 "Colour30" 30 "Colour31" 31 "Colour32" 32 "Colour33" 33 "Colour34" 34 "Colour35" 35 "Colour36" 36 "Colour37" 37 "Colour38" 38 "Colour39" 39 "Colour40" 40 "Colour41" 41 "Colour42" 42 "Colour43" 43 "Colour44" 44 "Colour45" 45 "Colour46" 46 "Colour47" 47 "Colour48" 48 "Colour49" 49 "Colour50" 50 "Colour51" 51 "Colour52" 52 "Colour53" 53 "Colour54" 54 "Colour55" 55 "Colour56" 56 "Colour57" 57 "Colour58" 58 "Colour59" 59 "Colour60" 60 "Colour61" 61 "Colour62" 62 "Colour63" 63 "Colour64" 64 "Reserved" 65 "Reserved" 66 "Reserved" 67 "Reserved" 68 "Reserved" 69 "Reserved" 70 "Reserved" 71 "Reserved" 72 "Reserved" 73 "Reserved" 74 "Reserved" 75 "Reserved" 76 "Reserved" 77 "Reserved" 78 "Reserved" 79 "Reserved" 80 "Reserved" 81 "Reserved" 82 "Reserved" 83 "Reserved" 84 "Reserved" 85 "Reserved" 86 "Reserved" 87 "Reserved" 88 "Reserved" 89 "Reserved" 90 "Reserved" 91 "Reserved" 92 "Reserved" 93 "Reserved" 94 "Reserved" 95 "Reserved" 96 "Reserved" 97 "Reserved" 98 "Reserved" 99 "Reserved" 100 "Reserved" 101 "Reserved" 102 "Reserved" 103 "Reserved" 104 "Reserved" 105 "Reserved" 106 "Reserved" 107 "Reserved" 108 "Reserved" 109 "Reserved" 110 "Reserved" 111 "Reserved" 112 "Reserved" 113 "Reserved" 114 "Reserved" 115 "Reserved" 116 "Reserved" 117 "Reserved" 118 "Reserved" 119 "Reserved" 120 "Reserved" 121 "Reserved" 122 "Reserved" 123 "Reserved" 124 "Reserved" 125 "Reserved" 126 "Reserved" 127 "Reserved" 128 "Reserved" 129 "Reserved" 130 "Reserved" 131 "Reserved" 132 "Reserved" 133 "Reserved" 134 "Reserved" 135 "Reserved" 136 "Reserved" 137 "Reserved" 138 "Reserved" 139 "Reserved" 140 "Reserved" 141 "Reserved" 142 "Reserved" 143 "Reserved" 144 "Reserved" 145 "Reserved" 146 "Reserved" 147 "Reserved" 148 "Reserved" 149 "Reserved" 150 "Reserved" 151 "Reserved" 152 "Reserved" 153 "Reserved" 154 "Reserved" 155 "Reserved" 156 "Reserved" 157 "Reserved" 158 "Reserved" 159 "Reserved" 160 "Reserved" 161 "Reserved" 162 "Reserved" 163 "Reserved" 164 "Reserved" 165 "Reserved" 166 "Reserved" 167 "Reserved" 168 "Reserved" 169 "Reserved" 170 "Reserved" 171 "Reserved" 172 "Reserved" 173 "Reserved" 174 "Reserved" 175 "Reserved" 176 "Reserved" 177 "Reserved" 178 "Reserved" 179 "Reserved" 180 "Reserved" 181 "Reserved" 182 "Reserved" 183 "Reserved" 184 "Reserved" 185 "Reserved" 186 "Reserved" 187 "Reserved" 188 "Reserved" 189 "Reserved" 190 "Reserved" 191 "Reserved" 192 "Reserved" 193 "Reserved" 194 "Reserved" 195 "Reserved" 196 "Reserved" 197 "Reserved" 198 "Reserved" 199 "Reserved" 200 "Reserved" 201 "Reserved" 202 "Reserved" 203 "Reserved" 204 "Reserved" 205 "Reserved" 206 "Reserved" 207 "Reserved" 208 "Reserved" 209 "Reserved" 210 "Reserved" 211 "Reserved" 212 "Reserved" 213 "Reserved" 214 "Reserved" 215 "Reserved" 216 "Reserved" 217 "Reserved" 218 "Reserved" 219 "Reserved" 220 "Reserved" 221 "Reserved" 222 "Reserved" 223 "Reserved" 224 "Reserved" 225 "Reserved" 226 "Reserved" 227 "Reserved" 228 "Reserved" 229 "Reserved" 230 "Reserved" 231 "Reserved" 232 "Reserved" 233 "Reserved" 234 "Reserved" 235 "Reserved" 236 "Reserved" 237 "Reserved" 238 "Reserved" 239 "Reserved" 240 "Reserved" 241 "Reserved" 242 "Reserved" 243 "Reserved" 244 "Reserved" 245 "Reserved" 246 "Reserved" 247 "Reserved" 248 "Reserved" 249 "Reserved" 250 "Reserved" 251 "Reserved" 252 "Reserved" 253 "Reserved" 254 "Reserved" 255 "Reserved" ;
VAL_ 642 DCM_FL_CarSharingTimeSts 0 "1" 1 "2" 2 "3" 3 "4" 4 "5" 5 "6" 6 "7" 7 "8" 8 "9" 9 "10" ;
VAL_ 642 DCM_FL_PowerDoorModeSts 0 "Fully Auto" 1 "Half Auto" 2 "Assist Manual" 3 "Fully Manual" ;
VAL_ 642 DCM_FL_FrontKeepOpenSts 0 "Disable" 1 "Enable" ;
VAL_ 642 DCM_FL_PriorSoundSts 0 "Disable" 1 "Enable" ;
VAL_ 642 DCM_FL_DoorFLAngle 127 "Invalid";
VAL_ 642 DCM_FL_DoorFLLockSts 0 "Locked" 1 "Unlocked" ;
VAL_ 642 DCM_FL_LinkageAvoidanceReq 0 "No request" 1 "Close" 2 "Open" 3 "Stop" ;
VAL_ 642 DCM_FL_ElectricDoorMovementSts 0 "FullyClosed" 1 "FullyOpened" 2 "Opening" 3 "Closing" 4 "Stoped" 5 "Revserved" 6 "Revserved" 7 "Revserved" ;
VAL_ 642 DCM_FL_DoorAntiPinchSts 0 "Normal" 1 "Anti pinch" ;
VAL_ 642 DCM_FL_DoorObstacleSts 0 "Normal" 1 "Outer obstacle" ;
VAL_ 642 DCM_FL_FLPESwitchReq 0 "Not pressed" 1 "Pressed" ;
VAL_ 642 DCM_FL_PWM_POS_STS 0 "Bottom stall" 1 "No stall" 2 "Top stall" 3 "Top soft stop" 4 "Bottom soft stop" ;
VAL_ 642 DCM_FL_WindowSts 0 "stopped" 1 "Auto Up moving" 2 "Manual Up moving" 3 "Auto Down moving" 4 "Manual Down moving" 5 "Pinch Reversing" ;
VAL_ 642 DCM_FL_InsideSwitchReq 0 "Not pressed" 1 "Pressed" ;
VAL_ 642 DCM_FL_FrontDoorAngleFeedback 0 "Fully Open" 1 "Half Open" ;
VAL_ 642 DCM_FL_GLASS_LOCATION 0 "0%" 1 "5%" 2 "10%" 3 "15%" 4 "20%" 5 "25%" 6 "30%" 7 "35%" 8 "40%" 9 "45%" 10 "50%" 11 "55%" 12 "60%" 13 "65%" 14 "70%" 15 "75%" 16 "80%" 17 "85%" 18 "90%" 19 "95%" 20 "100%" ;
VAL_ 642 DCM_FL_CarSharingLightSts 0 "Disable" 1 "Enable" ;
VAL_ 642 DCM_FL_WelcomeOnOffSts 0 "Disable" 1 "Enable" ;
VAL_ 650 MessageCounter_28A 15 "Invalid" ;
VAL_ 650 DCM_FL_DoorFLSts 0 "Closed" 1 "Opened" ;
VAL_ 650 DCM_FL_FRWndSwA 0 "Off switch" 1 "manually press the window lift switch" 2 "automatically press the window lift switch" 3 "manually press the window drop switch" 4 "automatically press the window drop switch" 5 "Invalid" ;
VAL_ 650 DCM_FL_RLWndSwA 0 "Off switch" 1 "manually press the window lift switch" 2 "automatically press the window lift switch" 3 "manually press the window drop switch" 4 "automatically press the window drop switch" 5 "Invalid" ;
VAL_ 650 DCM_FL_RRWndSwA 0 "Off switch" 1 "manually press the window lift switch" 2 "automatically press the window lift switch" 3 "manually press the window drop switch" 4 "automatically press the window drop switch" 5 "Invalid" ;
VAL_ 650 DCM_FL_PowerDoorErrorSts 0 "Normal" 1 "Tilt sensor error" 2 "Internal button error" 3 "Hidden Handle error" 4 "Door position uncertain" 5 "Actuator load protection" 6 "Obstacle sensor error" 7 "Excessive slope" ;
VAL_ 650 DCM_FL_LeftMirrorHorizontalPos 255 "Invalid";
VAL_ 650 DCM_FL_LeftMirrorVerticalPos 255 "Invalid";
VAL_ 650 DCM_FL_MirrorAutoTurnDownSts 0 "Disable" 1 "Enable" ;
VAL_ 650 DCM_FL_MirrorAutoFoldUnfoldSts 0 "Disable" 1 "Enable" ;
VAL_ 650 DCM_FL_RearmirrorHeatingSts 0 "OFF" 1 "ON" ;
VAL_ 650 DCM_FL_MirrorFold_UnfoldSts 0 "Unfold" 1 "Fold" ;
VAL_ 652 DCM_FL_MirrorTiltVerticalPos 255 "Invalid";
VAL_ 652 DCM_FL_MirrorTiltHorizontalPos 255 "Invalid";
VAL_ 652 DCM_FL_MirrorMainVerticalPos 255 "Invalid";
VAL_ 652 DCM_FL_MirrorMainHorizontalPos 255 "Invalid";
VAL_ 309 DCM_FL_MirrorAdjustmentSts 0 "No Request" 1 "Fault_Folded" ;
VAL_ 309 DCM_FL_MirrorFoldFaultSts 0 "No Request" 1 "Fail to fold" 2 "Fail to unfold" 3 "Fail on speed" ;
VAL_ 309 DCM_FL_HandleFailReminder 0 "Disable" 1 "Enable" 2 "Reserved" 3 "Reserved" ;
VAL_ 309 DCM_FL_PriorSoundReq 0 "No request" 1 "Enable" ;
